VERSION "5.0.7"

NS_ :

BS_:

BU_: BMS EAC EVCC FMCU CVC_P PDU PTC CCU DUMMY_ECU

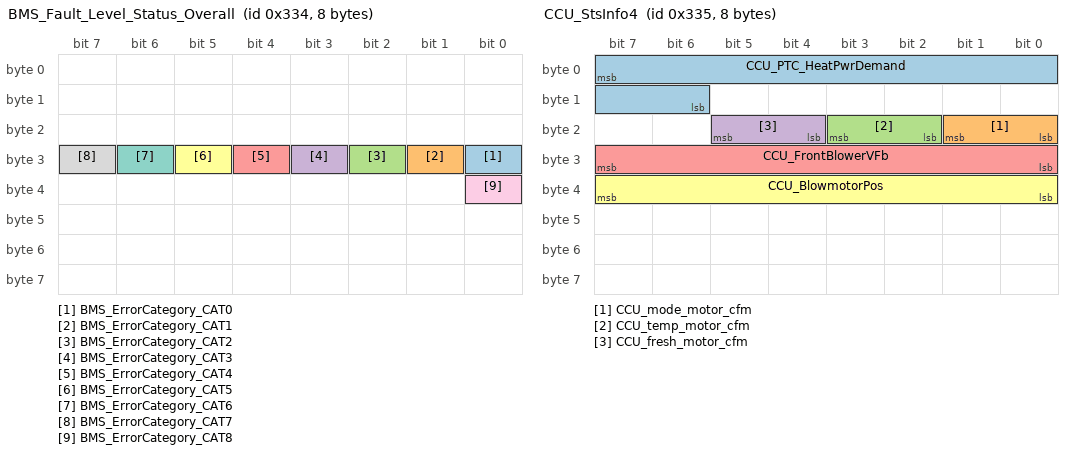
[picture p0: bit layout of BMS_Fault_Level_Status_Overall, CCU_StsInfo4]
BO_ 820 BMS_Fault_Level_Status_Overall: 8 BMS
 SG_ BMS_ErrorCategory_CAT0 : 24|1@0+ (1,0) [0|1] "" Vector__XXX
 SG_ BMS_ErrorCategory_CAT1 : 25|1@0+ (1,0) [0|1] "" Vector__XXX
 SG_ BMS_ErrorCategory_CAT2 : 26|1@0+ (1,0) [0|1] "" Vector__XXX
 SG_ BMS_ErrorCategory_CAT3 : 27|1@0+ (1,0) [0|1] "" Vector__XXX
 SG_ BMS_ErrorCategory_CAT4 : 28|1@0+ (1,0) [0|1] "" Vector__XXX
 SG_ BMS_ErrorCategory_CAT5 : 29|1@0+ (1,0) [0|1] "" Vector__XXX
 SG_ BMS_ErrorCategory_CAT6 : 30|1@0+ (1,0) [0|1] "" Vector__XXX
 SG_ BMS_ErrorCategory_CAT7 : 31|1@0+ (1,0) [0|1] "" Vector__XXX
 SG_ BMS_ErrorCategory_CAT8 : 32|1@0+ (1,0) [0|1] "" Vector__XXX

BO_ 821 CCU_StsInfo4: 8 CCU
 SG_ CCU_PTC_HeatPwrDemand : 7|10@0+ (20,0) [0|5080] "W"  CVC_P,EVCC,PTC
 SG_ CCU_mode_motor_cfm : 17|2@0+ (1,0) [0|3] ""  CVC_P,EVCC,PTC
 SG_ CCU_temp_motor_cfm : 19|2@0+ (1,0) [0|3] ""  CVC_P,EVCC,PTC
 SG_ CCU_fresh_motor_cfm : 21|2@0+ (1,0) [0|3] ""  CVC_P,EVCC,PTC
 SG_ CCU_FrontBlowerVFb : 31|8@0+ (0.1,0) [3|15] "V"  CVC_P
 SG_ CCU_BlowmotorPos : 39|8@0+ (0.1,0) [0|10] "V"  CVC_P

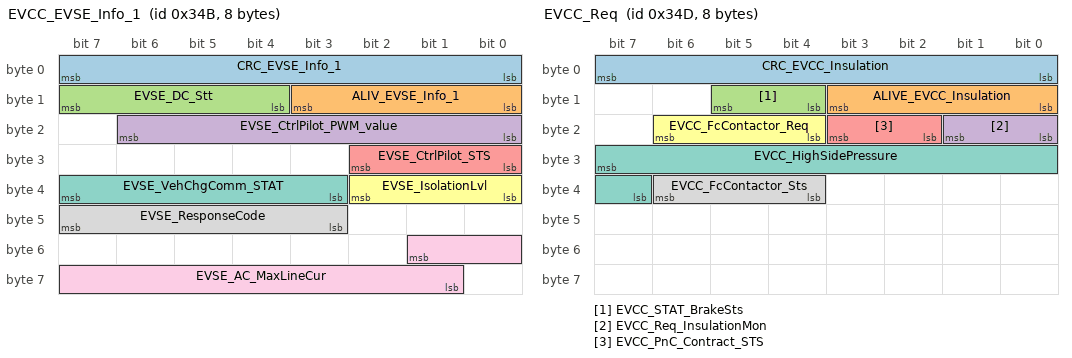
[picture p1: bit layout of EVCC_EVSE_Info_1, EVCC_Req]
BO_ 843 EVCC_EVSE_Info_1: 8 EVCC
 SG_ CRC_EVSE_Info_1 : 7|8@0+ (1,0) [0|255] ""  CVC_P,PDU
 SG_ ALIV_EVSE_Info_1 : 11|4@0+ (1,0) [0|15] ""  CVC_P,PDU
 SG_ EVSE_DC_Stt : 15|4@0+ (1,0) [0|12] ""  CVC_P,PDU
 SG_ EVSE_CtrlPilot_PWM_value : 22|7@0+ (1,0) [0|100] "%"  CVC_P,PDU
 SG_ EVSE_CtrlPilot_STS : 26|3@0+ (1,0) [0|6] ""  CVC_P,PDU
 SG_ EVSE_IsolationLvl : 34|3@0+ (1,0) [0|5] ""  CVC_P,PDU
 SG_ EVSE_VehChgComm_STAT : 39|5@0+ (1,0) [0|27] ""  CVC_P,PDU
 SG_ EVSE_ResponseCode : 47|5@0+ (1,0) [0|26] ""  CVC_P,PDU
 SG_ EVSE_AC_MaxLineCur : 49|9@0+ (1,0) [0|400] "A"  CVC_P,PDU

BO_ 845 EVCC_Req: 8 EVCC
 SG_ CRC_EVCC_Insulation : 7|8@0+ (1,0) [0|255] ""  CVC_P,BMS,PDU
 SG_ ALIVE_EVCC_Insulation : 11|4@0+ (1,0) [0|15] ""  CVC_P,BMS,PDU
 SG_ EVCC_STAT_BrakeSts : 13|2@0+ (1,0) [0|3] ""  CVC_P
 SG_ EVCC_Req_InsulationMon : 17|2@0+ (1,0) [0|3] ""  CVC_P,BMS,PDU
 SG_ EVCC_PnC_Contract_STS : 19|2@0+ (1,0) [0|3] ""  CVC_P,BMS,PDU
 SG_ EVCC_FcContactor_Req : 22|3@0+ (1,0) [0|7] ""  CVC_P,BMS,PDU
 SG_ EVCC_HighSidePressure : 31|9@0+ (10,0) [100|4000] "KPa"  BMS,CVC_P
 SG_ EVCC_FcContactor_Sts : 38|3@0+ (1,0) [0|7] ""  CVC_P,BMS,PDU

BO_ 847 EVCC_EVSE_Info_2: 8 EVCC
 SG_ CRC_EVSE_Info_2 : 7|8@0+ (1,0) [0|255] ""  BMS,CVC_P
 SG_ ALIV_EVSE_Info_2 : 11|4@0+ (1,0) [0|15] ""  BMS,CVC_P
 SG_ EVSE_DC_MaxChgCur : 23|16@0+ (0.1,0) [0|6553.5] "A"  BMS,CVC_P
 SG_ EVSE_DC_MaxChgPwr : 39|16@0+ (0.1,0) [0|6553.5] "kW"  BMS,CVC_P
 SG_ EVSE_DC_ActCurOut : 55|16@0+ (0.1,0) [0|6553.5] "A"  BMS,CVC_P

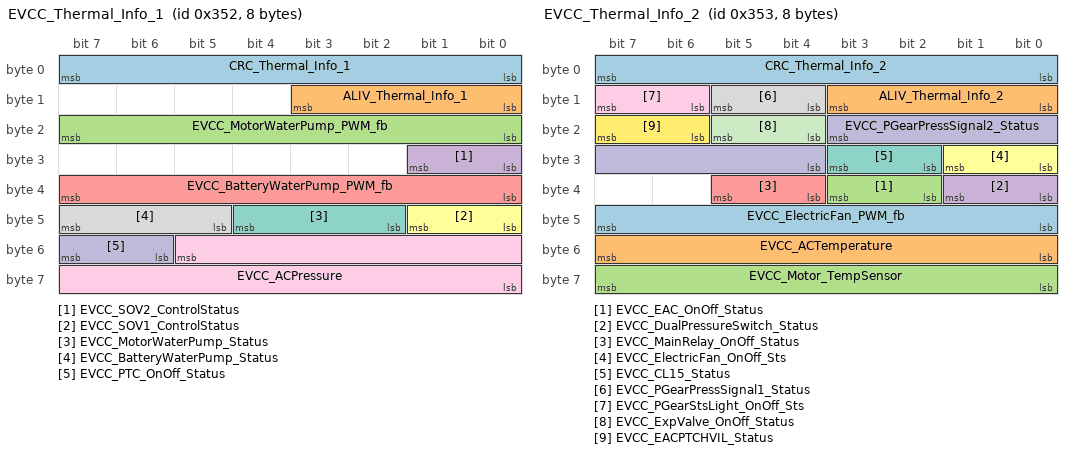
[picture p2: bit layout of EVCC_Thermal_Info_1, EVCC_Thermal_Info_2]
BO_ 850 EVCC_Thermal_Info_1: 8 EVCC
 SG_ CRC_Thermal_Info_1 : 7|8@0+ (1,0) [0|255] ""  CVC_P,CCU
 SG_ ALIV_Thermal_Info_1 : 11|4@0+ (1,0) [0|15] ""  CVC_P,CCU
 SG_ EVCC_MotorWaterPump_PWM_fb : 23|8@0+ (1,0) [0|100] "%"  CVC_P,CCU
 SG_ EVCC_SOV2_ControlStatus : 25|2@0+ (1,0) [0|3] ""  CVC_P,CCU
 SG_ EVCC_BatteryWaterPump_PWM_fb : 39|8@0+ (1,0) [0|100] "%"  CVC_P,CCU
 SG_ EVCC_SOV1_ControlStatus : 41|2@0+ (1,0) [0|3] ""  CVC_P,CCU
 SG_ EVCC_MotorWaterPump_Status : 44|3@0+ (1,0) [0|4] ""  CVC_P,CCU
 SG_ EVCC_BatteryWaterPump_Status : 47|3@0+ (1,0) [0|6] ""  CVC_P,CCU
 SG_ EVCC_ACPressure : 53|14@0+ (0.295,-60) [0|1150] "kPa"  CVC_P,CCU
 SG_ EVCC_PTC_OnOff_Status : 55|2@0+ (1,0) [0|3] ""  CVC_P,CCU

BO_ 851 EVCC_Thermal_Info_2: 8 EVCC
 SG_ CRC_Thermal_Info_2 : 7|8@0+ (1,0) [0|255] ""  CVC_P
 SG_ ALIV_Thermal_Info_2 : 11|4@0+ (1,0) [0|15] ""  CVC_P
 SG_ EVCC_EAC_OnOff_Status : 35|2@0+ (1,0) [0|3] ""  CVC_P
 SG_ EVCC_DualPressureSwitch_Status : 33|2@0+ (1,0) [0|3] ""  CVC_P
 SG_ EVCC_MainRelay_OnOff_Status : 37|2@0+ (1,0) [0|3] ""  CVC_P
 SG_ EVCC_ElectricFan_OnOff_Sts : 25|2@0+ (1,0) [0|3] ""  CVC_P
 SG_ EVCC_CL15_Status : 27|2@0+ (1,0) [0|3] ""  CVC_P
 SG_ EVCC_PGearPressSignal1_Status : 13|2@0+ (1,0) [0|3] ""  CVC_P
 SG_ EVCC_PGearStsLight_OnOff_Sts : 15|2@0+ (1,0) [0|3] ""  CVC_P
 SG_ EVCC_PGearPressSignal2_Status : 19|8@0+ (1,0) [0|255] "kilo ohms"  CVC_P
 SG_ EVCC_ExpValve_OnOff_Status : 21|2@0+ (1,0) [0|3] ""  CVC_P
 SG_ EVCC_EACPTCHVIL_Status : 23|2@0+ (1,0) [0|3] ""  CVC_P
 SG_ EVCC_ElectricFan_PWM_fb : 47|8@0+ (1,0) [0|100] "%"  CVC_P
 SG_ EVCC_ACTemperature : 55|8@0+ (1,-40) [-40|140] "Degree C"  CVC_P
 SG_ EVCC_Motor_TempSensor : 63|8@0+ (1,-40) [-40|140] "Degree C"  CVC_P

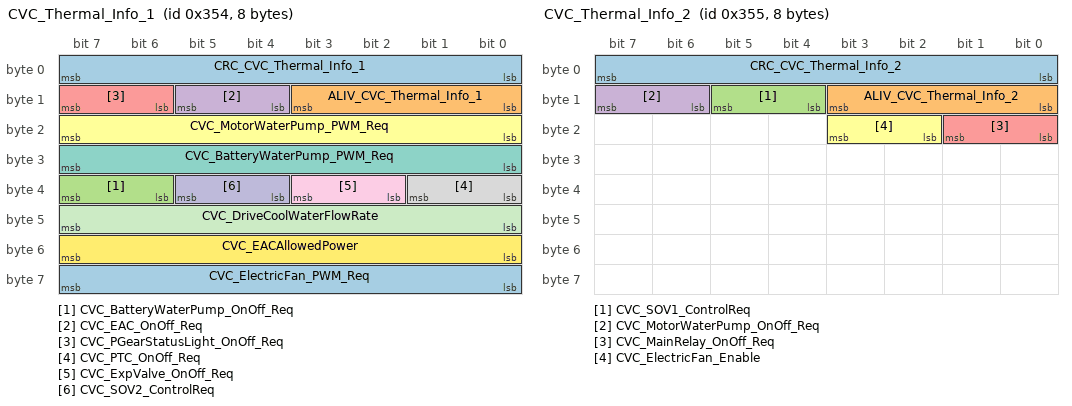
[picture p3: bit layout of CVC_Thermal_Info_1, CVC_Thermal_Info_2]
BO_ 852 CVC_Thermal_Info_1: 8 CVC_P
 SG_ CRC_CVC_Thermal_Info_1 : 7|8@0+ (1,0) [0|255] ""  EVCC,EAC,FMCU
 SG_ ALIV_CVC_Thermal_Info_1 : 11|4@0+ (1,0) [0|15] ""  EVCC,EAC,FMCU
 SG_ CVC_BatteryWaterPump_OnOff_Req : 39|2@0+ (1,0) [0|3] ""  EVCC
 SG_ CVC_EAC_OnOff_Req : 13|2@0+ (1,0) [0|3] ""  EVCC
 SG_ CVC_PGearStatusLight_OnOff_Req : 15|2@0+ (1,0) [0|3] ""  EVCC
 SG_ CVC_MotorWaterPump_PWM_Req : 23|8@0+ (1,0) [0|100] "%"  EVCC
 SG_ CVC_BatteryWaterPump_PWM_Req : 31|8@0+ (1,0) [0|100] "%"  EVCC
 SG_ CVC_PTC_OnOff_Req : 33|2@0+ (1,0) [0|3] ""  EVCC
 SG_ CVC_ExpValve_OnOff_Req : 35|2@0+ (1,0) [0|3] ""  EVCC
 SG_ CVC_SOV2_ControlReq : 37|2@0+ (1,0) [0|3] ""  EVCC
 SG_ CVC_DriveCoolWaterFlowRate : 47|8@0+ (0.1,0) [0|25] "L/min"  EAC,FMCU
 SG_ CVC_EACAllowedPower : 55|8@0+ (40,0) [0|10200] "W"  EAC
 SG_ CVC_ElectricFan_PWM_Req : 63|8@0+ (1,0) [0|100] "%"  EVCC

BO_ 853 CVC_Thermal_Info_2: 8 CVC_P
 SG_ CRC_CVC_Thermal_Info_2 : 7|8@0+ (1,0) [0|255] ""  EVCC
 SG_ ALIV_CVC_Thermal_Info_2 : 11|4@0+ (1,0) [0|15] ""  EVCC
 SG_ CVC_SOV1_ControlReq : 13|2@0+ (1,0) [0|3] ""  EVCC
 SG_ CVC_MotorWaterPump_OnOff_Req : 15|2@0+ (1,0) [0|3] ""  EVCC
 SG_ CVC_MainRelay_OnOff_Req : 17|2@0+ (1,0) [0|3] ""  EVCC
 SG_ CVC_ElectricFan_Enable : 19|2@0+ (1,0) [0|3] ""  EVCC

BO_ 855 CVC_ChgSetting_Info: 8 CVC_P
 SG_ CRC_CVC_ChgSetting_Info : 7|8@0+ (1,0) [0|255] ""  EVCC,BMS
 SG_ ALIV_CVC_ChgSetting_Info : 11|4@0+ (1,0) [0|15] ""  EVCC,BMS
 SG_ CVC_Ack_LimitSetting_SOC : 22|7@0+ (1,0) [0|100] "%"  EVCC,BMS
 SG_ CVC_ACInputChgCurLim : 29|6@0+ (1,0) [0|48] "A"  EVCC

BO_ 858 CVC_CP_Req: 8 CVC_P
 SG_ CRC_CVC_CP_Req : 7|8@0+ (1,0) [0|255] ""  EVCC
 SG_ ALIV_CVC_CP_Req : 11|4@0+ (1,0) [0|15] ""  EVCC
 SG_ CVC_LockCP_Req : 13|2@0+ (1,0) [0|3] ""  EVCC

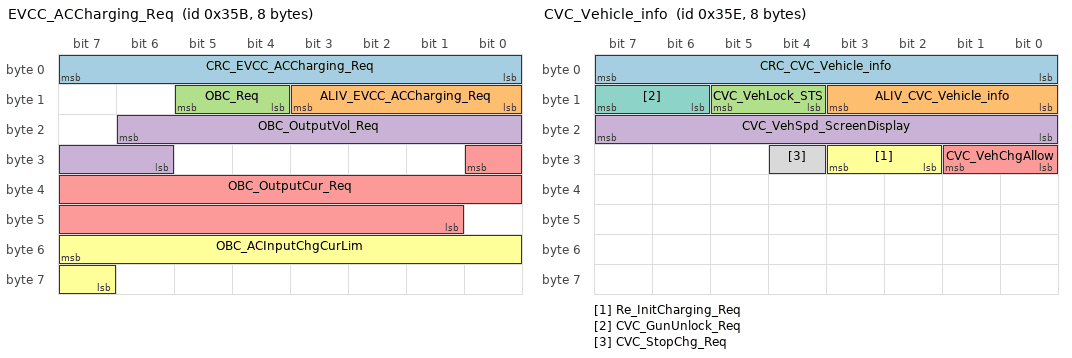
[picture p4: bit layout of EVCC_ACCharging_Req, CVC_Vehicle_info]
BO_ 859 EVCC_ACCharging_Req: 8 EVCC
 SG_ CRC_EVCC_ACCharging_Req : 7|8@0+ (1,0) [0|255] ""  CVC_P,PDU
 SG_ ALIV_EVCC_ACCharging_Req : 11|4@0+ (1,0) [0|15] ""  CVC_P,PDU
 SG_ OBC_Req : 13|2@0+ (1,0) [0|3] ""  CVC_P,PDU
 SG_ OBC_OutputVol_Req : 22|9@0+ (1,0) [0|500] "V"  CVC_P,PDU
 SG_ OBC_OutputCur_Req : 24|16@0+ (0.1,0) [0|48] "A"  CVC_P,PDU
 SG_ OBC_ACInputChgCurLim : 55|9@0+ (0.1,0) [0|48] "A"  CVC_P,PDU

BO_ 862 CVC_Vehicle_info: 8 CVC_P
 SG_ CRC_CVC_Vehicle_info : 7|8@0+ (1,0) [0|255] ""  EVCC,BMS,PDU
 SG_ ALIV_CVC_Vehicle_info : 11|4@0+ (1,0) [0|15] ""  EVCC,BMS,PDU
 SG_ CVC_VehLock_STS : 13|2@0+ (1,0) [0|3] ""  EVCC,BMS,PDU
 SG_ CVC_VehSpd_ScreenDisplay : 23|8@0+ (1,0) [0|254] ""  EVCC,BMS,PDU
 SG_ CVC_VehChgAllow : 25|2@0+ (1,0) [0|3] ""  EVCC,BMS,PDU
 SG_ Re_InitCharging_Req : 27|2@0+ (1,0) [0|3] ""  EVCC,BMS,PDU
 SG_ CVC_GunUnlock_Req : 15|2@0+ (1,0) [0|3] ""  EVCC
 SG_ CVC_StopChg_Req : 28|1@0+ (1,0) [0|1] ""  EVCC

BO_ 872 FMCU_Fault: 8 FMCU
 SG_ FMCU_MCUinternalFault : 48|1@0+ (1,0) [0|1] "" Vector__XXX
 SG_ FMCU_PhaseOverCurrentSWFault : 0|1@0+ (1,0) [0|1] ""  CVC_P
 SG_ FMCU_MCUOverTempFault : 1|1@0+ (1,0) [0|1] ""  CVC_P
 SG_ FMCU_MCUOverTempAlarm : 2|1@0+ (1,0) [0|1] ""  CVC_P
 SG_ FMCU_MotTempSenWFault : 3|1@0+ (1,0) [0|1] ""  CVC_P
 SG_ FMCU_MotTempSenVFault : 4|1@0+ (1,0) [0|1] ""  CVC_P
 SG_ FMCU_MotTempSenUFault : 5|1@0+ (1,0) [0|1] ""  CVC_P
 SG_ FMCU_MotTempSenFault : 6|1@0+ (1,0) [0|1] ""  CVC_P
 SG_ FMCU_MotOverTempFault : 7|1@0+ (1,0) [0|1] ""  CVC_P
 SG_ FMCU_MotOverTempAlarm : 8|1@0+ (1,0) [0|1] ""  CVC_P
 SG_ FMCU_MCUHVUnderVoltageFault : 9|1@0+ (1,0) [0|1] ""  CVC_P
 SG_ FMCU_MCUHVUnderVoltageAlarm : 10|1@0+ (1,0) [0|1] ""  CVC_P
 SG_ FMCU_MCUHVOverVoltageFault : 11|1@0+ (1,0) [0|1] ""  CVC_P
 SG_ FMCU_MCUHVOverVoltageAlarm : 12|1@0+ (1,0) [0|1] ""  CVC_P
 SG_ FMCU_MCUCurrentSenWFault : 13|1@0+ (1,0) [0|1] ""  CVC_P
 SG_ FMCU_MCUCurrentSenVFault : 14|1@0+ (1,0) [0|1] ""  CVC_P
 SG_ FMCU_MCUCurrentSenUFault : 15|1@0+ (1,0) [0|1] ""  CVC_P
 SG_ FMCU_PhaseOverCurrentHWFault : 16|1@0+ (1,0) [0|1] ""  CVC_P
 SG_ FMCU_MotOverFault : 17|1@0+ (1,0) [0|1] ""  CVC_P
 SG_ FMCU_MotOverAlarm : 18|1@0+ (1,0) [0|1] ""  CVC_P
 SG_ FMCU_12VUnderVoltageAlarm : 20|1@0+ (1,0) [0|1] ""  CVC_P
 SG_ FMCU_12VOverVoltageAlarm : 21|1@0+ (1,0) [0|1] ""  CVC_P
 SG_ FMCU_MCUHVSensorFault : 22|1@0+ (1,0) [0|1] ""  CVC_P
 SG_ FMCU_MCUDisChgFault : 24|1@0+ (1,0) [0|1] ""  CVC_P
 SG_ FMCU_MotBlockedFault : 30|1@0+ (1,0) [0|1] ""  CVC_P
 SG_ FMCU_MotRotSenFault : 31|1@0+ (1,0) [0|1] ""  CVC_P
 SG_ FMCU_BMSLostFault : 34|1@0+ (1,0) [0|1] ""  CVC_P
 SG_ FMCU_CVCLostFault : 35|1@0+ (1,0) [0|1] ""  CVC_P
 SG_ FMCU_CANBusoffFault : 36|1@0+ (1,0) [0|1] ""  CVC_P
 SG_ FMCU_IGBTFault : 37|1@0+ (1,0) [0|1] ""  CVC_P
 SG_ FMCU_MCUCurrentSenWZeroFault : 38|1@0+ (1,0) [0|1] ""  CVC_P
 SG_ FMCU_MCUCurrentSenVZeroFault : 43|1@0+ (1,0) [0|1] ""  CVC_P
 SG_ FMCU_MCUCurrentSenUZeroFault : 44|1@0+ (1,0) [0|1] ""  CVC_P
 SG_ FMCU_MCUTempSenWFault : 45|1@0+ (1,0) [0|1] ""  CVC_P
 SG_ FMCU_MCUTempSenVFault : 46|1@0+ (1,0) [0|1] ""  CVC_P
 SG_ FMCU_MCUTempSenUFault : 47|1@0+ (1,0) [0|1] ""  CVC_P
 SG_ FMCU_InitMode : 50|1@0+ (1,0) [0|1] ""  CVC_P
 SG_ FMCU_MCUFaultCode : 63|8@0+ (1,0) [0|255] ""  CVC_P

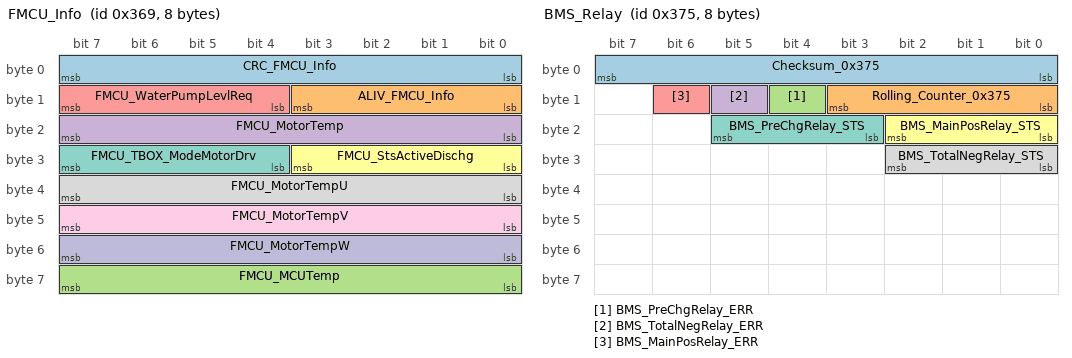
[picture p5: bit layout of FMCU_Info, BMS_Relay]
BO_ 873 FMCU_Info: 8 FMCU
 SG_ CRC_FMCU_Info : 7|8@0+ (1,0) [0|255] ""  CVC_P
 SG_ ALIV_FMCU_Info : 11|4@0+ (1,0) [0|15] ""  CVC_P
 SG_ FMCU_MCUTemp : 63|8@0+ (1,-40) [-40|210] "Degree C"  CVC_P
 SG_ FMCU_MotorTemp : 23|8@0+ (1,-40) [-40|210] "Degree C"  CVC_P
 SG_ FMCU_WaterPumpLevlReq : 15|4@0+ (2,0) [0|30] "l/min"  CVC_P
 SG_ FMCU_StsActiveDischg : 27|4@0+ (1,0) [0|15] ""  CVC_P
 SG_ FMCU_TBOX_ModeMotorDrv : 31|4@0+ (1,0) [0|15] ""  CVC_P
 SG_ FMCU_MotorTempU : 39|8@0+ (1,-40) [-40|210] "Degree C"  CVC_P
 SG_ FMCU_MotorTempV : 47|8@0+ (1,-40) [-40|210] "Degree C"  CVC_P
 SG_ FMCU_MotorTempW : 55|8@0+ (1,-40) [-40|210] "Degree C"  CVC_P

BO_ 876 AC_36C: 8 CVC_P
 SG_ CRC_AC_36C : 7|8@0+ (1,0) [0|255] ""  PTC
 SG_ ALIV_AC_36C : 11|4@0+ (1,0) [0|15] ""  PTC
 SG_ AC_PTC_HeatPwrReq : 23|8@0+ (20,0) [0|5080] "W"  PTC
 SG_ AC_PTC_Enable : 12|1@0+ (1,0) [0|1] "bit"  PTC

BO_ 884 PTC_Info1: 8 PTC
 SG_ PTC_PCBT : 23|8@0+ (1,-48) [-48|207] "Degree C"  CVC_P,CCU
 SG_ PTC_Crt : 31|16@0+ (0.001,0) [0|65.535] "A"  CVC_P,CCU
 SG_ PTC_CrtSts : 41|2@0+ (1,0) [0|3] ""  CVC_P,CCU
 SG_ PTC_HVIntlkFlt : 42|1@0+ (1,0) [0|1] ""  CVC_P,CCU
 SG_ PTC_ComLost_ECC : 43|1@0+ (1,0) [0|1] ""  CVC_P,CCU
 SG_ PTC_OverCrtFlt : 44|1@0+ (1,0) [0|1] ""  CVC_P,CCU
 SG_ PTC_HVUnderVoltFlt : 45|1@0+ (1,0) [0|1] ""  CVC_P,CCU
 SG_ PTC_HVOverVoltFlt : 46|1@0+ (1,0) [0|1] ""  CVC_P,CCU
 SG_ PTC_ChkBattOverVoltFlt : 47|1@0+ (1,0) [0|1] ""  CVC_P,CCU
 SG_ PTC_ChkBattUnderVoltFlt : 48|1@0+ (1,0) [0|1] ""  CVC_P,CCU
 SG_ PTC_InlTSnsrFlt : 49|1@0+ (1,0) [0|1] ""  CVC_P,CCU
 SG_ PTC_OutlTSnsrFlt : 50|1@0+ (1,0) [0|1] ""  CVC_P,CCU
 SG_ PTC_InlOverTFlt : 51|1@0+ (1,0) [0|1] ""  CVC_P,CCU
 SG_ PTC_OutlOverTFlt : 52|1@0+ (1,0) [0|1] ""  CVC_P,CCU
 SG_ PTC_PCBOverTFlt : 53|1@0+ (1,0) [0|1] ""  CVC_P,CCU
 SG_ PTC_PCBTSnsrFlt : 54|1@0+ (1,0) [0|1] ""  CVC_P,CCU
 SG_ PTC_PwrOutpFlt : 55|1@0+ (1,0) [0|1] ""  CVC_P,CCU

BO_ 885 BMS_Relay: 8 BMS
 SG_ Checksum_0x375 : 7|8@0+ (1,0) [0|255] ""  FMCU,CVC_P
 SG_ Rolling_Counter_0x375 : 11|4@0+ (1,0) [0|15] ""  FMCU,CVC_P
 SG_ BMS_PreChgRelay_ERR : 12|1@0+ (1,0) [0|1] ""  FMCU,CVC_P
 SG_ BMS_TotalNegRelay_ERR : 13|1@0+ (1,0) [0|1] ""  FMCU,CVC_P,PDU
 SG_ BMS_MainPosRelay_ERR : 14|1@0+ (1,0) [0|1] ""  FMCU,CVC_P
 SG_ BMS_MainPosRelay_STS : 18|3@0+ (1,0) [0|7] ""  FMCU,CVC_P,PDU
 SG_ BMS_PreChgRelay_STS : 21|3@0+ (1,0) [0|7] ""  FMCU,CVC_P,PDU
 SG_ BMS_TotalNegRelay_STS : 26|3@0+ (1,0) [0|7] ""  FMCU,CVC_P

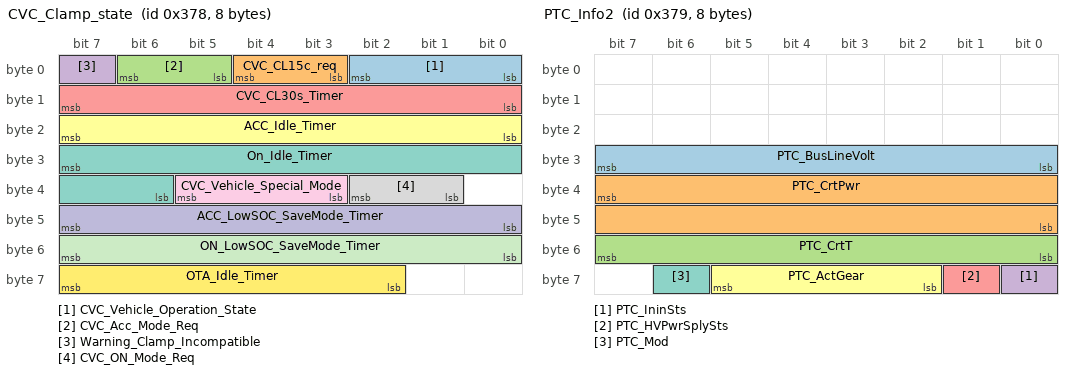
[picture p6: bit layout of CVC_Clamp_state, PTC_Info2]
BO_ 888 CVC_Clamp_state: 8 CVC_P
 SG_ CVC_Vehicle_Operation_State : 2|3@0+ (1,0) [0|7] ""  BMS,FMCU,PDU,EVCC,CCU,EAC,PTC
 SG_ CVC_CL15c_req : 4|2@0+ (1,0) [0|3] ""  BMS,FMCU,PDU,EVCC,CCU
 SG_ CVC_Acc_Mode_Req : 6|2@0+ (1,0) [0|3] ""  BMS,FMCU,PDU,EVCC,CCU
 SG_ Warning_Clamp_Incompatible : 7|1@0+ (1,0) [0|1] ""  BMS,FMCU,PDU,EVCC,CCU
 SG_ CVC_CL30s_Timer : 15|8@0+ (1,0) [0|255] ""  BMS,FMCU,PDU,EVCC,CCU
 SG_ ACC_Idle_Timer : 23|8@0+ (1,0) [0|255] ""  BMS,FMCU,PDU,EVCC,CCU
 SG_ On_Idle_Timer : 31|10@0+ (1,0) [0|1023] ""  BMS,FMCU,PDU,EVCC,CCU
 SG_ CVC_ON_Mode_Req : 34|2@0+ (1,0) [0|3] ""  BMS,FMCU,PDU,EVCC,CCU
 SG_ CVC_Vehicle_Special_Mode : 37|3@0+ (1,0) [0|7] ""  BMS,FMCU,PDU,EVCC,CCU
 SG_ ACC_LowSOC_SaveMode_Timer : 47|8@0+ (1,0) [0|255] ""  BMS,FMCU,PDU,EVCC,CCU
 SG_ ON_LowSOC_SaveMode_Timer : 55|8@0+ (1,0) [0|255] ""  BMS,FMCU,PDU,EVCC,CCU
 SG_ OTA_Idle_Timer : 63|6@0+ (1,0) [0|64] "minute"  DUMMY_ECU

BO_ 889 PTC_Info2: 8 PTC
 SG_ PTC_BusLineVolt : 31|8@0+ (2,0) [0|500] "Volt"  CVC_P,CCU,BMS
 SG_ PTC_CrtPwr : 39|16@0+ (20,0) [0|5080] "W"  CVC_P,CCU,BMS
 SG_ PTC_CrtT : 55|8@0+ (1,-48) [-48|207] "Degree C"  CVC_P,CCU,BMS
 SG_ PTC_IninSts : 56|1@0+ (1,0) [0|1] ""  CVC_P,CCU,BMS
 SG_ PTC_HVPwrSplySts : 57|1@0+ (1,0) [0|1] ""  CVC_P,CCU,BMS
 SG_ PTC_ActGear : 61|4@0+ (1,0) [0|15] ""  CVC_P,CCU,BMS
 SG_ PTC_Mod : 62|1@0+ (1,0) [0|1] ""  CVC_P,CCU,BMS

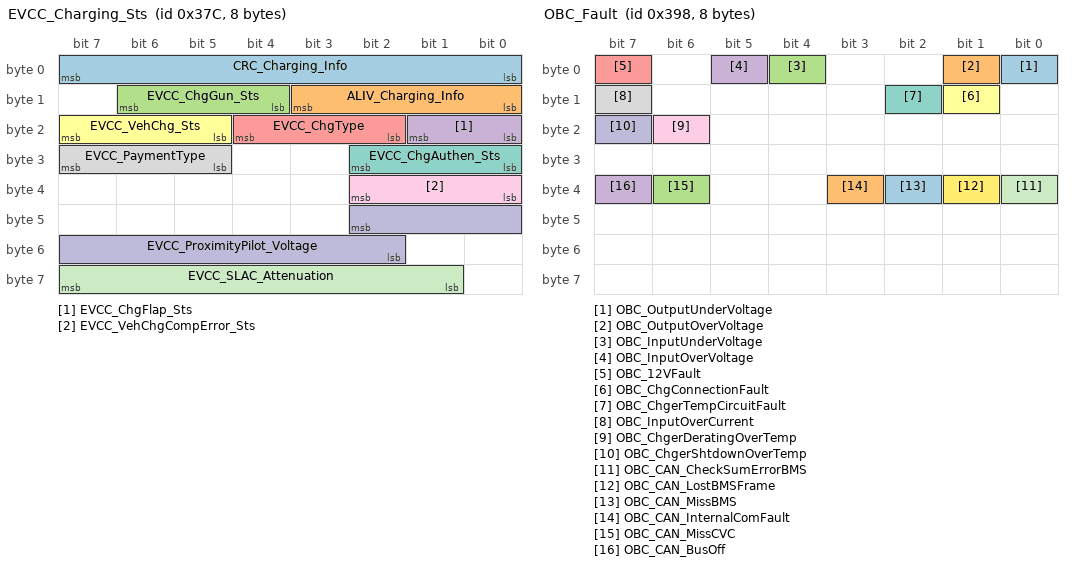
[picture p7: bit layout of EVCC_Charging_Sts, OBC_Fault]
BO_ 892 EVCC_Charging_Sts: 8 EVCC
 SG_ CRC_Charging_Info : 7|8@0+ (1,0) [0|255] ""  CVC_P,BMS,PDU
 SG_ ALIV_Charging_Info : 11|4@0+ (1,0) [0|15] ""  CVC_P,BMS,PDU
 SG_ EVCC_ChgGun_Sts : 14|3@0+ (1,0) [0|7] ""  CVC_P,BMS,PDU
 SG_ EVCC_ChgFlap_Sts : 17|2@0+ (1,0) [0|3] ""  CVC_P,BMS,PDU
 SG_ EVCC_ChgType : 20|3@0+ (1,0) [0|7] ""  CVC_P,BMS,PDU
 SG_ EVCC_VehChg_Sts : 23|3@0+ (1,0) [0|7] ""  CVC_P,BMS,PDU
 SG_ EVCC_ChgAuthen_Sts : 26|3@0+ (1,0) [0|7] ""  CVC_P,BMS,PDU
 SG_ EVCC_PaymentType : 31|3@0+ (1,0) [0|7] ""  CVC_P,BMS,PDU
 SG_ EVCC_VehChgCompError_Sts : 34|3@0+ (1,0) [0|7] ""  CVC_P,BMS,PDU
 SG_ EVCC_ProximityPilot_Voltage : 42|9@0+ (0.01,0) [0|5] "V"  CVC_P,BMS,PDU
 SG_ EVCC_SLAC_Attenuation : 63|7@0+ (1,0) [0|100] "dB"  CVC_P

BO_ 893 CVC_Battery_Info: 8 CVC_P
 SG_ CRC_CVC_Battery_Info : 7|8@0+ (1,0) [0|255] ""  EVCC,BMS,PDU
 SG_ ALIV_CVC_Battery_Info : 11|4@0+ (1,0) [0|15] ""  EVCC,BMS,PDU
 SG_ CVC_HV_DispSOC : 23|10@0+ (0.1,0) [0|100] "%"  EVCC
 SG_ CVC_HV_Cur_LoadComp : 29|10@0+ (0.1,0) [0|100] "A"  EVCC,BMS,PDU

BO_ 896 BCM_VEHICLE_IDENT_NUMBER: 8 CVC_P
 SG_ VIN_Byte1 : 7|8@0+ (1,0) [0|255] ""  FMCU,PDU,BMS
 SG_ VIN_Byte2 : 15|8@0+ (1,0) [0|255] ""  FMCU,PDU,BMS
 SG_ VIN_Byte3 : 23|8@0+ (1,0) [0|255] ""  FMCU,PDU,BMS
 SG_ VIN_Byte4 : 31|8@0+ (1,0) [0|255] ""  FMCU,PDU,BMS
 SG_ VIN_Byte5 : 39|8@0+ (1,0) [0|255] ""  FMCU,PDU,BMS
 SG_ VIN_Byte6 : 47|8@0+ (1,0) [0|255] ""  FMCU,PDU,BMS
 SG_ VIN_Byte7 : 55|8@0+ (1,0) [0|255] ""  FMCU,PDU,BMS

BO_ 919 OBC_Temp: 8 PDU
 SG_ CRC_OBC_Temp : 7|8@0+ (1,0) [0|255] ""  CVC_P
 SG_ ALIV_OBC_Temp : 11|4@0+ (1,0) [0|15] ""  CVC_P
 SG_ OBC_OBCTemp : 31|8@0+ (1,-40) [-40|214] "Degree C"  CVC_P
 SG_ OBC_InletTemp : 23|8@0+ (1,-40) [-40|210] "Degree C"  CVC_P
 SG_ OBC_InletTempSenFault : 46|1@0+ (1,0) [0|1] "-"  CVC_P

BO_ 920 OBC_Fault: 8 PDU
 SG_ OBC_OutputUnderVoltage : 0|1@0+ (1,0) [0|1] ""  CVC_P
 SG_ OBC_OutputOverVoltage : 1|1@0+ (1,0) [0|1] ""  CVC_P
 SG_ OBC_InputUnderVoltage : 4|1@0+ (1,0) [0|1] ""  CVC_P
 SG_ OBC_InputOverVoltage : 5|1@0+ (1,0) [0|1] ""  CVC_P
 SG_ OBC_12VFault : 7|1@0+ (1,0) [0|1] ""  CVC_P
 SG_ OBC_ChgConnectionFault : 9|1@0+ (1,0) [0|1] ""  CVC_P
 SG_ OBC_ChgerTempCircuitFault : 10|1@0+ (1,0) [0|1] ""  CVC_P
 SG_ OBC_InputOverCurrent : 15|1@0+ (1,0) [0|1] ""  CVC_P
 SG_ OBC_ChgerDeratingOverTemp : 22|1@0+ (1,0) [0|1] ""  CVC_P
 SG_ OBC_ChgerShtdownOverTemp : 23|1@0+ (1,0) [0|1] ""  CVC_P
 SG_ OBC_CAN_CheckSumErrorBMS : 32|1@0+ (1,0) [0|1] ""  CVC_P
 SG_ OBC_CAN_LostBMSFrame : 33|1@0+ (1,0) [0|1] ""  CVC_P
 SG_ OBC_CAN_MissBMS : 34|1@0+ (1,0) [0|1] ""  CVC_P
 SG_ OBC_CAN_InternalComFault : 35|1@0+ (1,0) [0|1] ""  CVC_P
 SG_ OBC_CAN_MissCVC : 38|1@0+ (1,0) [0|1] ""  CVC_P
 SG_ OBC_CAN_BusOff : 39|1@0+ (1,0) [0|1] ""  CVC_P

BO_ 1009 IPC_TotalOdometer: 8 CVC_P
 SG_ CheckSum_0x3F1 : 7|8@0+ (1,0) [0|255] ""  BMS,FMCU,PDU,PTC,EAC,CCU,EVCC
 SG_ RollingCounter_0x3F1 : 11|4@0+ (1,0) [0|15] ""  BMS,FMCU,PDU,PTC,EAC,CCU,EVCC
 SG_ IPC_IPCTotalOdometer : 23|24@0+ (0.1,0) [0|999999] "km"  BMS,FMCU,PDU,PTC,EAC,CCU,EVCC
 SG_ IPC_IPCTotalOdometerV : 40|1@0+ (1,0) [0|1] ""  BMS,FMCU,PDU,PTC,EAC,CCU,EVCC
 SG_ IPC_Remain_Maintenance : 55|16@0+ (1,0) [0|50000] "km"  BMS,FMCU,PDU,PTC,EAC,CCU,EVCC

BO_ 1098 PTC_Version: 8 PTC
 SG_ PTC_SwVersS : 15|8@0+ (1,0) [0|255] "" Vector__XXX
 SG_ PTC_PartVers : 23|32@0+ (1,0) [0|4294967295] "" Vector__XXX
 SG_ PTC_HwVers : 55|8@0+ (1,0) [0|255] "" Vector__XXX
 SG_ PTC_SwVersM : 63|8@0+ (1,0) [0|255] "" Vector__XXX

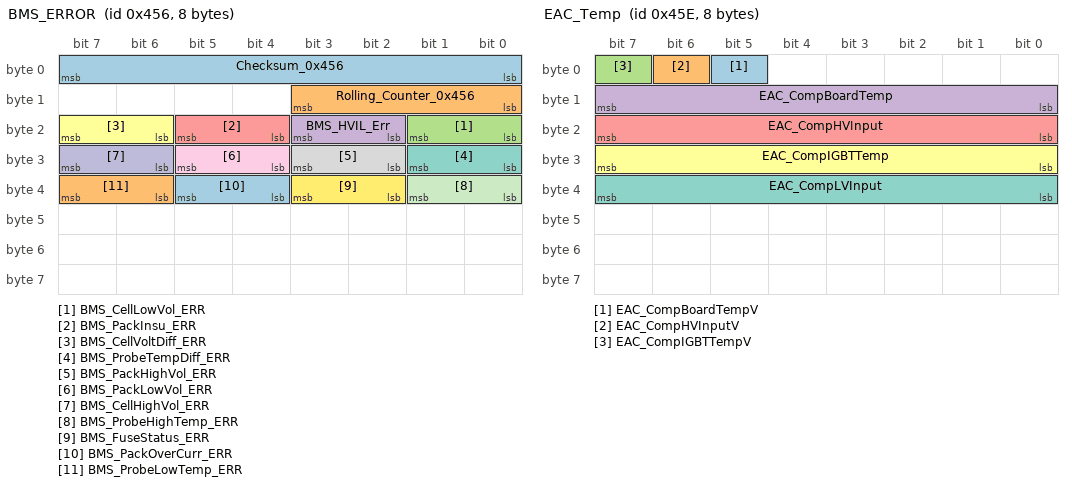
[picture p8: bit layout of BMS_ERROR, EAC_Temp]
BO_ 1110 BMS_ERROR: 8 BMS
 SG_ Checksum_0x456 : 7|8@0+ (1,0) [0|255] ""  CVC_P
 SG_ Rolling_Counter_0x456 : 11|4@0+ (1,0) [0|15] ""  CVC_P
 SG_ BMS_CellLowVol_ERR : 17|2@0+ (1,0) [0|3] ""  CVC_P
 SG_ BMS_HVIL_Err : 19|2@0+ (1,0) [0|3] ""  CVC_P
 SG_ BMS_PackInsu_ERR : 21|2@0+ (1,0) [0|3] ""  CVC_P
 SG_ BMS_CellVoltDiff_ERR : 23|2@0+ (1,0) [0|3] ""  CVC_P
 SG_ BMS_ProbeTempDiff_ERR : 25|2@0+ (1,0) [0|3] ""  CVC_P
 SG_ BMS_PackHighVol_ERR : 27|2@0+ (1,0) [0|3] ""  CVC_P
 SG_ BMS_PackLowVol_ERR : 29|2@0+ (1,0) [0|3] ""  CVC_P
 SG_ BMS_CellHighVol_ERR : 31|2@0+ (1,0) [0|3] ""  CVC_P
 SG_ BMS_ProbeHighTemp_ERR : 33|2@0+ (1,0) [0|3] ""  CVC_P
 SG_ BMS_FuseStatus_ERR : 35|2@0+ (1,0) [0|1] ""  CVC_P
 SG_ BMS_PackOverCurr_ERR : 37|2@0+ (1,0) [0|3] ""  CVC_P
 SG_ BMS_ProbeLowTemp_ERR : 39|2@0+ (1,0) [0|3] ""  CVC_P

BO_ 1118 EAC_Temp: 8 EAC
 SG_ EAC_CompBoardTempV : 5|1@0+ (1,0) [0|1] ""  CVC_P
 SG_ EAC_CompHVInputV : 6|1@0+ (1,0) [0|1] ""  CVC_P
 SG_ EAC_CompIGBTTempV : 7|1@0+ (1,0) [0|1] ""  CVC_P
 SG_ EAC_CompBoardTemp : 15|8@0+ (1,-40) [-40|215] "Degree C"  CVC_P
 SG_ EAC_CompHVInput : 23|8@0+ (4,0) [0|1020] "V"  CVC_P
 SG_ EAC_CompIGBTTemp : 31|8@0+ (1,-40) [-40|215] "Degree C"  CVC_P
 SG_ EAC_CompLVInput : 39|8@0+ (4,0) [0|1020] "V" Vector__XXX

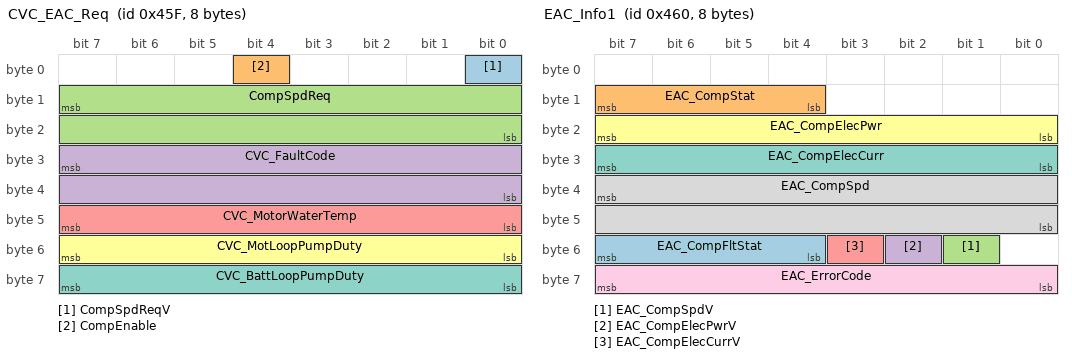
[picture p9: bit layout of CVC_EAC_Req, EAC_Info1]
BO_ 1119 CVC_EAC_Req: 8 CVC_P
 SG_ CompSpdReqV : 0|1@0+ (1,0) [0|1] ""  EAC
 SG_ CompEnable : 4|1@0+ (1,0) [0|1] ""  EAC
 SG_ CompSpdReq : 15|16@0+ (1,0) [0|65535] "RPM"  EAC
 SG_ CVC_FaultCode : 31|16@0+ (1,0) [0|65535] ""  EAC
 SG_ CVC_MotorWaterTemp : 47|8@0+ (1,-40) [-40|210] "Degree C"  EAC
 SG_ CVC_MotLoopPumpDuty : 55|8@0+ (1,0) [0|100] "%"  EAC
 SG_ CVC_BattLoopPumpDuty : 63|8@0+ (1,0) [0|100] "%"  EAC

BO_ 1117 EAC_Version: 8 EAC
 SG_ EAC_HW_MasterVersion : 7|8@0+ (1,0) [0|255] "" Vector__XXX
 SG_ EAC_SW_bottomVersion : 23|8@0+ (1,0) [0|255] "" Vector__XXX
 SG_ EAC_SW_ApplicationVersion : 31|8@0+ (1,0) [0|255] "" Vector__XXX
 SG_ EAC_SW_year : 39|8@0+ (1,2000) [2000|2255] "" Vector__XXX
 SG_ EAC_SW_month : 47|8@0+ (1,0) [0|255] "" Vector__XXX
 SG_ EAC_SW_day : 55|8@0+ (1,0) [0|255] "" Vector__XXX

BO_ 1120 EAC_Info1: 8 EAC
 SG_ EAC_CompFltStat : 55|4@0+ (1,0) [0|15] ""  CVC_P,CCU,BMS
 SG_ EAC_CompStat : 15|4@0+ (1,0) [0|15] ""  CVC_P,CCU,BMS
 SG_ EAC_CompSpdV : 49|1@0+ (1,0) [0|1] ""  CVC_P,CCU,BMS
 SG_ EAC_CompElecPwrV : 50|1@0+ (1,0) [0|1] ""  CVC_P,CCU,BMS
 SG_ EAC_CompElecCurrV : 51|1@0+ (1,0) [0|1] ""  CVC_P,CCU,BMS
 SG_ EAC_CompElecPwr : 23|8@0+ (40,0) [0|10200] "W"  CVC_P,CCU,BMS
 SG_ EAC_CompElecCurr : 31|8@0+ (0.2,0) [0|51] "A"  CVC_P,CCU,BMS
 SG_ EAC_CompSpd : 39|16@0+ (1,0) [0|65535] "rpm"  CVC_P,CCU,BMS
 SG_ EAC_ErrorCode : 63|8@0+ (1,0) [0|255] ""  CVC_P

BO_ 1141 PDU_DCFC_EventMatrix: 8 PDU
 SG_ PDU_DCFC_evt_reserved15 : 63|8@0+ (1,0) [0|1] "" Vector__XXX
 SG_ PDU_DCFC_evt_reserved14 : 55|8@0+ (1,0) [0|1] "" Vector__XXX
 SG_ PDU_DCFC_evt_reserved13 : 47|8@0+ (1,0) [0|1] "" Vector__XXX
 SG_ PDU_DCFC_evt_reserved12 : 39|8@0+ (1,0) [0|1] "" Vector__XXX
 SG_ PDU_DCFC_evt_reserved11 : 24|1@0+ (1,0) [0|1] "" Vector__XXX
 SG_ PDU_DCFC_evt_reserved10 : 25|1@0+ (1,0) [0|1] "" Vector__XXX
 SG_ PDU_DCFC_evt_reserved9 : 26|1@0+ (1,0) [0|1] "" Vector__XXX
 SG_ PDU_DCFC_evt_reserved8 : 27|1@0+ (1,0) [0|1] "" Vector__XXX
 SG_ PDU_DCFC_evt_reserved7 : 28|1@0+ (1,0) [0|1] "" Vector__XXX
 SG_ PDU_DCFC_evt_reserved6 : 29|1@0+ (1,0) [0|1] "" Vector__XXX
 SG_ PDU_DCFC_evt_reserved5 : 30|1@0+ (1,0) [0|1] "" Vector__XXX
 SG_ PDU_DCFC_evt_reserved4 : 31|1@0+ (1,0) [0|1] "" Vector__XXX
 SG_ PDU_DCFC_evt_reserved3 : 16|1@0+ (1,0) [0|1] "" Vector__XXX
 SG_ PDU_DCFC_evt_reserved2 : 17|1@0+ (1,0) [0|1] "" Vector__XXX
 SG_ PDU_DCFC_evt_reserved1 : 18|1@0+ (1,0) [0|1] "" Vector__XXX
 SG_ PDU_DCFC_evt_reserved0 : 19|1@0+ (1,0) [0|1] "" Vector__XXX
 SG_ PDU_DCFC_evt_I2CDataWrong : 20|1@0+ (1,0) [0|1] "" Vector__XXX
 SG_ PDU_DCFC_evt_I2CComFail : 21|1@0+ (1,0) [0|1] "" Vector__XXX
 SG_ PDU_DCFC_evt_ChgPort_RvrsPoltFlt : 22|1@0+ (1,0) [0|1] "" Vector__XXX
 SG_ PDU_DCFC_evt_ChgPort_UnderV_CMP : 23|1@0+ (1,0) [0|1] "" Vector__XXX
 SG_ PDU_DCFC_evt_ChgPort_OverV_CMP : 8|1@0+ (1,0) [0|1] "" Vector__XXX
 SG_ PDU_DCFC_evt_BUSOFF : 9|1@0+ (1,0) [0|1] "" Vector__XXX
 SG_ PDU_DCFC_evt_EXTMEMFAIL : 10|1@0+ (1,0) [0|1] "" Vector__XXX
 SG_ PDU_DCFC_evt_MCUPWRFAIL : 11|1@0+ (1,0) [0|1] "" Vector__XXX
 SG_ PDU_DCFC_evt_CoilPwrFlt : 12|1@0+ (1,0) [0|1] "" Vector__XXX
 SG_ PDU_DCFC_evt_ChgPort_VSensFlt : 13|1@0+ (1,0) [0|1] "" Vector__XXX
 SG_ PDU_DCFC_evt_E2E : 14|1@0+ (1,0) [0|1] "" Vector__XXX
 SG_ PDU_DCFC_evt_MIA : 15|1@0+ (1,0) [0|1] "" Vector__XXX
 SG_ PDU_DCFC_evt_ChgPort_UnderV_SW : 0|1@0+ (1,0) [0|1] "" Vector__XXX
 SG_ PDU_DCFC_evt_PosBB_OverTempFlt : 1|1@0+ (1,0) [0|1] "" Vector__XXX
 SG_ PDU_DCFC_evt_NegBB_OverTempFlt : 2|1@0+ (1,0) [0|1] "" Vector__XXX
 SG_ PDU_DCFC_evt_ChgPort_OverV_SW : 3|1@0+ (1,0) [0|1] "" Vector__XXX
 SG_ PDU_DCFC_evt_Contactor_StuckOpen : 4|1@0+ (1,0) [0|1] "" Vector__XXX
 SG_ PDU_DCFC_evt_Contactor_Welded : 5|1@0+ (1,0) [0|1] "" Vector__XXX
 SG_ PDU_DCFC_evt_PosBB_TempSensFlt : 6|1@0+ (1,0) [0|1] "" Vector__XXX
 SG_ PDU_DCFC_evt_NegBB_TempSensFlt : 7|1@0+ (1,0) [0|1] "" Vector__XXX

BO_ 1145 EVCC_EventMatrix: 8 EVCC
 SG_ EVCC_evt_ePP : 0|1@0+ (1,0) [0|1] "" Vector__XXX
 SG_ EVCC_evt_eCP : 1|1@0+ (1,0) [0|1] "" Vector__XXX
 SG_ EVCC_evt_eGunLck : 2|1@0+ (1,0) [0|1] "" Vector__XXX
 SG_ EVCC_evt_eV2G : 3|1@0+ (1,0) [0|1] "" Vector__XXX
 SG_ EVCC_evt_eAcPlugTemp : 4|1@0+ (1,0) [0|1] "" Vector__XXX
 SG_ EVCC_evt_eDcPlugTemp : 5|1@0+ (1,0) [0|1] "" Vector__XXX
 SG_ EVCC_evt_eBmsLvl : 6|1@0+ (1,0) [0|1] "" Vector__XXX
 SG_ EVCC_evt_eHLC : 7|1@0+ (1,0) [0|1] "" Vector__XXX
 SG_ EVCC_evt_iEvseDcPeakRpl : 8|1@0+ (1,0) [0|1] "" Vector__XXX
 SG_ EVCC_evt_eObcLvl : 9|1@0+ (1,0) [0|1] "" Vector__XXX
 SG_ EVCC_evt_ChgGunStkOpnd : 10|1@0+ (1,0) [0|1] "" Vector__XXX
 SG_ EVCC_evt_ChgGunStkClsd : 11|1@0+ (1,0) [0|1] "" Vector__XXX
 SG_ EVCC_evt_AcTmpShortVcc : 12|1@0+ (1,0) [0|1] "" Vector__XXX
 SG_ EVCC_evt_PPShortVcc : 13|1@0+ (1,0) [0|1] "" Vector__XXX
 SG_ EVCC_evt_PPShortGnd : 14|1@0+ (1,0) [0|1] "" Vector__XXX
 SG_ EVCC_evt_DcPTmpShortGnd : 15|1@0+ (1,0) [0|1] "" Vector__XXX
 SG_ EVCC_evt_eFCWelded : 16|1@0+ (1,0) [0|1] "" Vector__XXX
 SG_ EVCC_evt_eHVBusTemp : 17|1@0+ (1,0) [0|1] "" Vector__XXX
 SG_ EVCC_evt_ChgFlapHBShtGnd : 18|1@0+ (1,0) [0|1] "" Vector__XXX
 SG_ EVCC_evt_ChgFlapHBShtBatt : 19|1@0+ (1,0) [0|1] "" Vector__XXX
 SG_ EVCC_evt_ChgFlapHBOpnCir : 20|1@0+ (1,0) [0|1] "" Vector__XXX
 SG_ EVCC_evt_ChgFlapHBOCVCrr : 21|1@0+ (1,0) [0|1] "" Vector__XXX
 SG_ EVCC_evt_ChgFlapHBOvTemp : 22|1@0+ (1,0) [0|1] "" Vector__XXX
 SG_ EVCC_evt_DcPTmpShortVcc : 23|1@0+ (1,0) [0|1] "" Vector__XXX
 SG_ EVCC_evt_AcTmpShortGnd : 24|1@0+ (1,0) [0|1] "" Vector__XXX
 SG_ EVCC_evt_eBmsInsu : 25|1@0+ (1,0) [0|1] "" Vector__XXX
 SG_ EVCC_evt_eBmsHvil : 26|1@0+ (1,0) [0|1] "" Vector__XXX
 SG_ EVCC_evt_eDcFcLvl1 : 27|1@0+ (1,0) [0|1] "" Vector__XXX
 SG_ EVCC_evt_eDcFcLvl2 : 28|1@0+ (1,0) [0|1] "" Vector__XXX
 SG_ EVCC_evt_eDcFcLvl3 : 29|1@0+ (1,0) [0|1] "" Vector__XXX
 SG_ EVCC_evt_eEVSE : 30|1@0+ (1,0) [0|1] "" Vector__XXX
 SG_ EVCC_evt_S2StkClsd : 31|1@0+ (1,0) [0|1] "" Vector__XXX
 SG_ EVCC_evt_S2StkOpnd : 32|1@0+ (1,0) [0|1] "" Vector__XXX
 SG_ EVCC_evt_CpFreqFailr : 33|1@0+ (1,0) [0|1] "" Vector__XXX
 SG_ EVCC_evt_bPmicOV : 34|1@0+ (1,0) [0|1] "" Vector__XXX
 SG_ EVCC_evt_bPmicUV : 35|1@0+ (1,0) [0|1] "" Vector__XXX
 SG_ EVCC_evt_bMissCvcMsg : 36|1@0+ (1,0) [0|1] "" Vector__XXX
 SG_ EVCC_evt_bMissBmsMsg : 37|1@0+ (1,0) [0|1] "" Vector__XXX
 SG_ EVCC_evt_bMissPodMsg : 38|1@0+ (1,0) [0|1] "" Vector__XXX
 SG_ EVCC_evt_bMissBcmMsg : 39|1@0+ (1,0) [0|1] "" Vector__XXX
 SG_ EVCC_evt_bE2eCvcMsg : 40|1@0+ (1,0) [0|1] "" Vector__XXX
 SG_ EVCC_evt_bE2eBmsMsg : 41|1@0+ (1,0) [0|1] "" Vector__XXX
 SG_ EVCC_evt_bE2ePodMsg : 42|1@0+ (1,0) [0|1] "" Vector__XXX
 SG_ EVCC_evt_bE2eBcmMsg : 43|1@0+ (1,0) [0|1] "" Vector__XXX
 SG_ EVCC_evt_ChgGunHBOvTemp : 44|1@0+ (1,0) [0|1] "" Vector__XXX
 SG_ EVCC_evt_ChgGunHBOCVCrr : 45|1@0+ (1,0) [0|1] "" Vector__XXX
 SG_ EVCC_evt_ChgGunHBOpnCir : 46|1@0+ (1,0) [0|1] "" Vector__XXX
 SG_ EVCC_evt_ChgGunHBShtBatt : 47|1@0+ (1,0) [0|1] "" Vector__XXX
 SG_ EVCC_evt_ChgFlapHBPorErr : 48|1@0+ (1,0) [0|1] "" Vector__XXX
 SG_ EVCC_evt_ChgFlapHBSpiComErr : 49|1@0+ (1,0) [0|1] "" Vector__XXX
 SG_ EVCC_evt_ChgGunHBPorErr : 50|1@0+ (1,0) [0|1] "" Vector__XXX
 SG_ EVCC_evt_ChgGunHBShtGnd : 51|1@0+ (1,0) [0|1] "" Vector__XXX
 SG_ EVCC_evt_DcNTmpShortVcc : 52|1@0+ (1,0) [0|1] "" Vector__XXX
 SG_ EVCC_evt_DcNTmpShortGnd : 53|1@0+ (1,0) [0|1] "" Vector__XXX
 SG_ EVCC_evt_L2ChkErr : 54|1@0+ (1,0) [0|1] "" Vector__XXX
 SG_ EVCC_evt_ChgTypeErr : 55|1@0+ (1,0) [0|1] "" Vector__XXX
 SG_ EVCC_evt_ChgGunHBSpiComErr : 56|1@0+ (1,0) [0|1] "" Vector__XXX
 SG_ EVCC_evt_PreconditionFlt : 57|1@0+ (1,0) [0|1] "" Vector__XXX
 SG_ EVCC_evt_eChrgnUpEvseNotRdy : 58|1@0+ (1,0) [0|1] "" Vector__XXX
 SG_ EVCC_evt_eChrgUpV2GIdle : 59|1@0+ (1,0) [0|1] "" Vector__XXX
 SG_ EVCC_evt_eChrg69CpNot9 : 60|1@0+ (1,0) [0|1] "" Vector__XXX
 SG_ EVCC_evt_eCoEssChModFlt : 61|1@0+ (1,0) [0|1] "" Vector__XXX
 SG_ EVCC_evt_eChrgUpEvseNotifStp : 62|1@0+ (1,0) [0|1] "" Vector__XXX
 SG_ EVCC_evt_ePLCSubTimeOut : 63|1@0+ (1,0) [0|1] "" Vector__XXX

BO_ 1146 BMS_SOCDiag: 8 BMS
 SG_ BMS_CellMaxSOC : 1|10@0+ (0.1,0) [0|100] "%"  FMCU
 SG_ BMS_CellMinSOC : 17|10@0+ (0.1,0) [0|100] "%"  FMCU
 SG_ BMS_CorrectedSOC : 33|10@0+ (0.1,0) [0|100] "%" Vector__XXX
 SG_ BMS_PackSOCDiff : 49|10@0+ (0.1,0) [0|100] "%" Vector__XXX

BO_ 1147 EVCC_EventMatrix_2: 8 EVCC
 SG_ EVCC_evt_ExtHiSide1HBOpnCir : 0|1@0+ (1,0) [0|1] "" Vector__XXX
 SG_ EVCC_evt_ExtHiSide2HBOpnCir : 1|1@0+ (1,0) [0|1] "" Vector__XXX
 SG_ EVCC_evt_ExtHiSide3HBOpnCir : 2|1@0+ (1,0) [0|1] "" Vector__XXX
 SG_ EVCC_evt_ExtHiSide4HBOpnCir : 3|1@0+ (1,0) [0|1] "" Vector__XXX
 SG_ EVCC_evt_ExtHiSide5HBOpnCir : 4|1@0+ (1,0) [0|1] "" Vector__XXX
 SG_ EVCC_evt_ExtHiSide1HBOCVCrr : 5|1@0+ (1,0) [0|1] "" Vector__XXX
 SG_ EVCC_evt_ExtHiSide2HBOCVCrr : 6|1@0+ (1,0) [0|1] "" Vector__XXX
 SG_ EVCC_evt_ExtHiSide3HBOCVCrr : 7|1@0+ (1,0) [0|1] "" Vector__XXX
 SG_ EVCC_evt_ExtHiSide4HBOCVCrr : 8|1@0+ (1,0) [0|1] "" Vector__XXX
 SG_ EVCC_evt_ExtHiSide5HBOCVCrr : 9|1@0+ (1,0) [0|1] "" Vector__XXX
 SG_ EVCC_evt_ExtHiSideHBShtBatt : 10|1@0+ (1,0) [0|1] "" Vector__XXX
 SG_ EVCC_evt_ExtHiSideHBShtGnd : 11|1@0+ (1,0) [0|1] "" Vector__XXX
 SG_ EVCC_evt_ExtHiSideHBTempOv : 12|1@0+ (1,0) [0|1] "" Vector__XXX
 SG_ EVCC_evt_ExtHiSideHBPorErr : 13|1@0+ (1,0) [0|1] "" Vector__XXX
 SG_ EVCC_evt_ExtHiSideHBTempWn : 14|1@0+ (1,0) [0|1] "" Vector__XXX
 SG_ EVCC_evt_ExtLoSide1HBOpnCir : 15|1@0+ (1,0) [0|1] "" Vector__XXX
 SG_ EVCC_evt_ExtLoSide2HBOpnCir : 16|1@0+ (1,0) [0|1] "" Vector__XXX
 SG_ EVCC_evt_ExtLoSide3HBOpnCir : 17|1@0+ (1,0) [0|1] "" Vector__XXX
 SG_ EVCC_evt_ExtLoSide4HBOpnCir : 18|1@0+ (1,0) [0|1] "" Vector__XXX
 SG_ EVCC_evt_ExtLoSide5HBOpnCir : 19|1@0+ (1,0) [0|1] "" Vector__XXX
 SG_ EVCC_evt_ExtLoSide1HBOCVCrr : 20|1@0+ (1,0) [0|1] "" Vector__XXX
 SG_ EVCC_evt_ExtLoSide2HBOCVCrr : 21|1@0+ (1,0) [0|1] "" Vector__XXX
 SG_ EVCC_evt_ExtLoSide3HBOCVCrr : 22|1@0+ (1,0) [0|1] "" Vector__XXX
 SG_ EVCC_evt_ExtLoSide4HBOCVCrr : 23|1@0+ (1,0) [0|1] "" Vector__XXX
 SG_ EVCC_evt_ExtLoSide5HBOCVCrr : 24|1@0+ (1,0) [0|1] "" Vector__XXX
 SG_ EVCC_evt_ExtLoSideHBShtBatt : 25|1@0+ (1,0) [0|1] "" Vector__XXX
 SG_ EVCC_evt_ExtLoSideHBShtGnd : 26|1@0+ (1,0) [0|1] "" Vector__XXX
 SG_ EVCC_evt_ExtLoSideHBTempOv : 27|1@0+ (1,0) [0|1] "" Vector__XXX
 SG_ EVCC_evt_ExtLoSideHBPorErr : 28|1@0+ (1,0) [0|1] "" Vector__XXX
 SG_ EVCC_evt_ExtLoSideHBTempWn : 29|1@0+ (1,0) [0|1] "" Vector__XXX
 SG_ EVCC_bChEndLongDeb : 30|1@0+ (1,0) [0|1] "" Vector__XXX
 SG_ EVCC_bChEndShortDeb : 31|1@0+ (1,0) [0|1] "" Vector__XXX
 SG_ EVCC_stV2GErr : 32|1@0+ (1,0) [0|1] "" Vector__XXX
 SG_ EVCC_stSup : 33|1@0+ (1,0) [0|1] "" Vector__XXX

BO_ 1171 BMS_WarnMsg: 8 BMS
 SG_ CHSKM_BMS_WarnMsg : 7|8@0+ (1,0) [0|255] ""  CVC_P
 SG_ ALV_BMS_WarnMsg : 11|4@0+ (1,0) [0|15] ""  CVC_P
 SG_ BMS_PackTempSts : 13|2@0+ (1,0) [0|3] ""  CVC_P
 SG_ BMS_ThermalRunaway : 14|1@0+ (1,0) [0|1] ""  CVC_P
 SG_ BMS_BatteryReplacement : 15|1@0+ (1,0) [0|1] ""  CVC_P
 SG_ BMS_Warning_PowerDegrade : 16|1@0+ (1,0) [0|1] ""  CVC_P
 SG_ BMS_Warning_DeltaSoC : 17|1@0+ (1,0) [0|1] ""  CVC_P
 SG_ BMS_Warning_HVILSts : 18|1@0+ (1,0) [0|1] ""  CVC_P
 SG_ BMS_Warning_Isolation : 19|1@0+ (1,0) [0|1] ""  CVC_P
 SG_ BMS_Warning_CoolantLeakage : 20|1@0+ (1,0) [0|1] ""  CVC_P
 SG_ BMS_MalfunctionSts : 21|1@0+ (1,0) [0|1] ""  CVC_P
 SG_ BMS_LowBattery : 23|2@0+ (1,0) [0|3] ""  CVC_P
 SG_ BMS_Warning_DeltaTemperature : 31|8@0+ (1,0) [0|255] ""  CVC_P
 SG_ BMS_Warning_BDUTemperatureSts : 39|8@0+ (1,0) [0|255] ""  CVC_P
 SG_ BMS_Warning_Contactor_Aging : 47|1@0+ (1,0) [0|1] ""  CVC_P
 SG_ BMS_Reserved_signal4 : 55|8@0+ (1,0) [0|255] ""  CVC_P
 SG_ BMS_Reserved_signal5 : 63|8@0+ (1,0) [0|255] ""  CVC_P

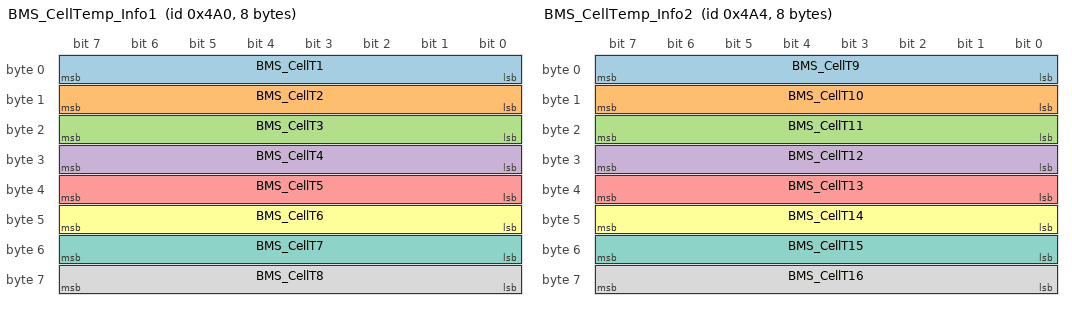
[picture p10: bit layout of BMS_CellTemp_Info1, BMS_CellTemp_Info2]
BO_ 1184 BMS_CellTemp_Info1: 8 BMS
 SG_ BMS_CellT1 : 7|8@0+ (1,-40) [-40|210] "℃" Vector__XXX
 SG_ BMS_CellT2 : 15|8@0+ (1,-40) [-40|210] "℃" Vector__XXX
 SG_ BMS_CellT3 : 23|8@0+ (1,-40) [-40|210] "℃" Vector__XXX
 SG_ BMS_CellT4 : 31|8@0+ (1,-40) [-40|210] "℃" Vector__XXX
 SG_ BMS_CellT5 : 39|8@0+ (1,-40) [-40|210] "℃" Vector__XXX
 SG_ BMS_CellT6 : 47|8@0+ (1,-40) [-40|210] "℃" Vector__XXX
 SG_ BMS_CellT7 : 55|8@0+ (1,-40) [-40|210] "℃" Vector__XXX
 SG_ BMS_CellT8 : 63|8@0+ (1,-40) [-40|210] "℃" Vector__XXX

BO_ 1188 BMS_CellTemp_Info2: 8 BMS
 SG_ BMS_CellT9 : 7|8@0+ (1,-40) [-40|210] "℃" Vector__XXX
 SG_ BMS_CellT10 : 15|8@0+ (1,-40) [-40|210] "℃" Vector__XXX
 SG_ BMS_CellT11 : 23|8@0+ (1,-40) [-40|210] "℃" Vector__XXX
 SG_ BMS_CellT12 : 31|8@0+ (1,-40) [-40|210] "℃" Vector__XXX
 SG_ BMS_CellT13 : 39|8@0+ (1,-40) [-40|210] "℃" Vector__XXX
 SG_ BMS_CellT14 : 47|8@0+ (1,-40) [-40|210] "℃" Vector__XXX
 SG_ BMS_CellT15 : 55|8@0+ (1,-40) [-40|210] "℃" Vector__XXX
 SG_ BMS_CellT16 : 63|8@0+ (1,-40) [-40|210] "℃" Vector__XXX

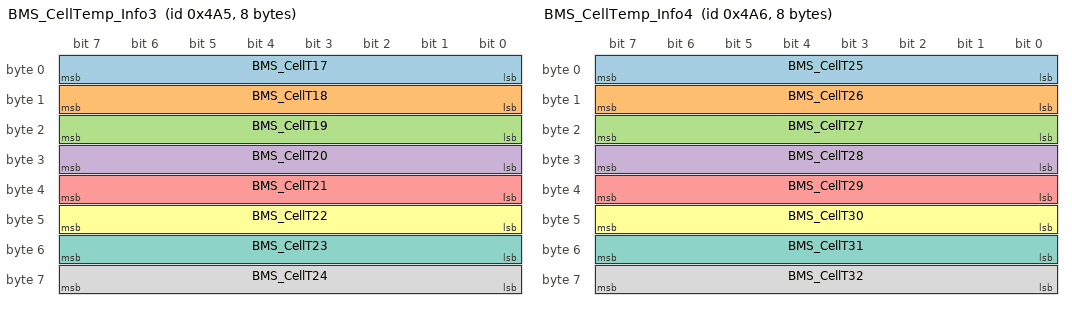
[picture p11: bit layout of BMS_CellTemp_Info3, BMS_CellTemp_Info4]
BO_ 1189 BMS_CellTemp_Info3: 8 BMS
 SG_ BMS_CellT17 : 7|8@0+ (1,-40) [-40|210] "℃" Vector__XXX
 SG_ BMS_CellT18 : 15|8@0+ (1,-40) [-40|210] "℃" Vector__XXX
 SG_ BMS_CellT19 : 23|8@0+ (1,-40) [-40|210] "℃" Vector__XXX
 SG_ BMS_CellT20 : 31|8@0+ (1,-40) [-40|210] "℃" Vector__XXX
 SG_ BMS_CellT21 : 39|8@0+ (1,-40) [-40|210] "℃" Vector__XXX
 SG_ BMS_CellT22 : 47|8@0+ (1,-40) [-40|210] "℃" Vector__XXX
 SG_ BMS_CellT23 : 55|8@0+ (1,-40) [-40|210] "℃" Vector__XXX
 SG_ BMS_CellT24 : 63|8@0+ (1,-40) [-40|210] "℃" Vector__XXX

BO_ 1190 BMS_CellTemp_Info4: 8 BMS
 SG_ BMS_CellT25 : 7|8@0+ (1,-40) [-40|210] "℃" Vector__XXX
 SG_ BMS_CellT26 : 15|8@0+ (1,-40) [-40|210] "℃" Vector__XXX
 SG_ BMS_CellT27 : 23|8@0+ (1,-40) [-40|210] "℃" Vector__XXX
 SG_ BMS_CellT28 : 31|8@0+ (1,-40) [-40|210] "℃" Vector__XXX
 SG_ BMS_CellT29 : 39|8@0+ (1,-40) [-40|210] "℃" Vector__XXX
 SG_ BMS_CellT30 : 47|8@0+ (1,-40) [-40|210] "℃" Vector__XXX
 SG_ BMS_CellT31 : 55|8@0+ (1,-40) [-40|210] "℃" Vector__XXX
 SG_ BMS_CellT32 : 63|8@0+ (1,-40) [-40|210] "℃" Vector__XXX

BO_ 1191 BMS_CellTemp_Info5: 8 BMS
 SG_ BMS_CellT33 : 7|8@0+ (1,-40) [-40|210] "℃" Vector__XXX
 SG_ BMS_CellT34 : 15|8@0+ (1,-40) [-40|210] "℃" Vector__XXX
 SG_ BMS_CellT35 : 23|8@0+ (1,-40) [-40|210] "℃" Vector__XXX
 SG_ BMS_CellT36 : 31|8@0+ (1,-40) [-40|210] "℃" Vector__XXX

BO_ 1192 BMS_CellVolt_Info01: 8 BMS
 SG_ BMS_CellVolt_1 : 7|16@0+ (0.001,0) [0|5] "V" Vector__XXX
 SG_ BMS_CellVolt_2 : 23|16@0+ (0.001,0) [0|5] "V" Vector__XXX
 SG_ BMS_CellVolt_3 : 39|16@0+ (0.001,0) [0|5] "V" Vector__XXX
 SG_ BMS_CellVolt_4 : 55|16@0+ (0.001,0) [0|5] "V" Vector__XXX

BO_ 1193 BMS_CellVolt_Info02: 8 BMS
 SG_ BMS_CellVolt_5 : 7|16@0+ (0.001,0) [0|5] "V" Vector__XXX
 SG_ BMS_CellVolt_6 : 23|16@0+ (0.001,0) [0|5] "V" Vector__XXX
 SG_ BMS_CellVolt_7 : 39|16@0+ (0.001,0) [0|5] "V" Vector__XXX
 SG_ BMS_CellVolt_8 : 55|16@0+ (0.001,0) [0|5] "V" Vector__XXX

BO_ 1196 BMS_CellVolt_Info03: 8 BMS
 SG_ BMS_CellVolt_9 : 7|16@0+ (0.001,0) [0|5] "V" Vector__XXX
 SG_ BMS_CellVolt_10 : 23|16@0+ (0.001,0) [0|5] "V" Vector__XXX
 SG_ BMS_CellVolt_11 : 39|16@0+ (0.001,0) [0|5] "V" Vector__XXX
 SG_ BMS_CellVolt_12 : 55|16@0+ (0.001,0) [0|5] "V" Vector__XXX

BO_ 1197 BMS_CellVolt_Info04: 8 BMS
 SG_ BMS_CellVolt_13 : 7|16@0+ (0.001,0) [0|5] "V" Vector__XXX
 SG_ BMS_CellVolt_14 : 23|16@0+ (0.001,0) [0|5] "V" Vector__XXX
 SG_ BMS_CellVolt_15 : 39|16@0+ (0.001,0) [0|5] "V" Vector__XXX
 SG_ BMS_CellVolt_16 : 55|16@0+ (0.001,0) [0|5] "V" Vector__XXX

BO_ 1198 BMS_CellVolt_Info05: 8 BMS
 SG_ BMS_CellVolt_17 : 7|16@0+ (0.001,0) [0|5] "V" Vector__XXX
 SG_ BMS_CellVolt_18 : 23|16@0+ (0.001,0) [0|5] "V" Vector__XXX
 SG_ BMS_CellVolt_19 : 39|16@0+ (0.001,0) [0|5] "V" Vector__XXX
 SG_ BMS_CellVolt_20 : 55|16@0+ (0.001,0) [0|5] "V" Vector__XXX

BO_ 1199 BMS_CellVolt_Info06: 8 BMS
 SG_ BMS_CellVolt_21 : 7|16@0+ (0.001,0) [0|5] "V" Vector__XXX
 SG_ BMS_CellVolt_22 : 23|16@0+ (0.001,0) [0|5] "V" Vector__XXX
 SG_ BMS_CellVolt_23 : 39|16@0+ (0.001,0) [0|5] "V" Vector__XXX
 SG_ BMS_CellVolt_24 : 55|16@0+ (0.001,0) [0|5] "V" Vector__XXX

BO_ 1200 BMS_CellVolt_Info07: 8 BMS
 SG_ BMS_CellVolt_25 : 7|16@0+ (0.001,0) [0|5] "V" Vector__XXX
 SG_ BMS_CellVolt_26 : 23|16@0+ (0.001,0) [0|5] "V" Vector__XXX
 SG_ BMS_CellVolt_27 : 39|16@0+ (0.001,0) [0|5] "V" Vector__XXX
 SG_ BMS_CellVolt_28 : 55|16@0+ (0.001,0) [0|5] "V" Vector__XXX

BO_ 1201 BMS_CellVolt_Info08: 8 BMS
 SG_ BMS_CellVolt_29 : 7|16@0+ (0.001,0) [0|5] "V" Vector__XXX
 SG_ BMS_CellVolt_30 : 23|16@0+ (0.001,0) [0|5] "V" Vector__XXX
 SG_ BMS_CellVolt_31 : 39|16@0+ (0.001,0) [0|5] "V" Vector__XXX
 SG_ BMS_CellVolt_32 : 55|16@0+ (0.001,0) [0|5] "V" Vector__XXX

BO_ 1202 BMS_CellVolt_Info09: 8 BMS
 SG_ BMS_CellVolt_33 : 7|16@0+ (0.001,0) [0|5] "V" Vector__XXX
 SG_ BMS_CellVolt_34 : 23|16@0+ (0.001,0) [0|5] "V" Vector__XXX
 SG_ BMS_CellVolt_35 : 39|16@0+ (0.001,0) [0|5] "V" Vector__XXX
 SG_ BMS_CellVolt_36 : 55|16@0+ (0.001,0) [0|5] "V" Vector__XXX

BO_ 1203 BMS_CellVolt_Info10: 8 BMS
 SG_ BMS_CellVolt_37 : 7|16@0+ (0.001,0) [0|5] "V" Vector__XXX
 SG_ BMS_CellVolt_38 : 23|16@0+ (0.001,0) [0|5] "V" Vector__XXX
 SG_ BMS_CellVolt_39 : 39|16@0+ (0.001,0) [0|5] "V" Vector__XXX
 SG_ BMS_CellVolt_40 : 55|16@0+ (0.001,0) [0|5] "V" Vector__XXX

BO_ 1204 BMS_CellVolt_Info11: 8 BMS
 SG_ BMS_CellVolt_41 : 7|16@0+ (0.001,0) [0|5] "V" Vector__XXX
 SG_ BMS_CellVolt_42 : 23|16@0+ (0.001,0) [0|5] "V" Vector__XXX
 SG_ BMS_CellVolt_43 : 39|16@0+ (0.001,0) [0|5] "V" Vector__XXX
 SG_ BMS_CellVolt_44 : 55|16@0+ (0.001,0) [0|5] "V" Vector__XXX

BO_ 1205 BMS_CellVolt_Info12: 8 BMS
 SG_ BMS_CellVolt_45 : 7|16@0+ (0.001,0) [0|5] "V" Vector__XXX
 SG_ BMS_CellVolt_46 : 23|16@0+ (0.001,0) [0|5] "V" Vector__XXX
 SG_ BMS_CellVolt_47 : 39|16@0+ (0.001,0) [0|5] "V" Vector__XXX
 SG_ BMS_CellVolt_48 : 55|16@0+ (0.001,0) [0|5] "V" Vector__XXX

BO_ 1206 BMS_CellVolt_Info13: 8 BMS
 SG_ BMS_CellVolt_49 : 7|16@0+ (0.001,0) [0|5] "V" Vector__XXX
 SG_ BMS_CellVolt_50 : 23|16@0+ (0.001,0) [0|5] "V" Vector__XXX
 SG_ BMS_CellVolt_51 : 39|16@0+ (0.001,0) [0|5] "V" Vector__XXX
 SG_ BMS_CellVolt_52 : 55|16@0+ (0.001,0) [0|5] "V" Vector__XXX

BO_ 1207 BMS_CellVolt_Info14: 8 BMS
 SG_ BMS_CellVolt_53 : 7|16@0+ (0.001,0) [0|5] "V" Vector__XXX
 SG_ BMS_CellVolt_54 : 23|16@0+ (0.001,0) [0|5] "V" Vector__XXX
 SG_ BMS_CellVolt_55 : 39|16@0+ (0.001,0) [0|5] "V" Vector__XXX
 SG_ BMS_CellVolt_56 : 55|16@0+ (0.001,0) [0|5] "V" Vector__XXX

BO_ 1208 BMS_CellVolt_Info15: 8 BMS
 SG_ BMS_CellVolt_57 : 7|16@0+ (0.001,0) [0|5] "V" Vector__XXX
 SG_ BMS_CellVolt_58 : 23|16@0+ (0.001,0) [0|5] "V" Vector__XXX
 SG_ BMS_CellVolt_59 : 39|16@0+ (0.001,0) [0|5] "V" Vector__XXX
 SG_ BMS_CellVolt_60 : 55|16@0+ (0.001,0) [0|5] "V" Vector__XXX

BO_ 1209 BMS_CellVolt_Info16: 8 BMS
 SG_ BMS_CellVolt_61 : 7|16@0+ (0.001,0) [0|5] "V" Vector__XXX
 SG_ BMS_CellVolt_62 : 23|16@0+ (0.001,0) [0|5] "V" Vector__XXX
 SG_ BMS_CellVolt_63 : 39|16@0+ (0.001,0) [0|5] "V" Vector__XXX
 SG_ BMS_CellVolt_64 : 55|16@0+ (0.001,0) [0|5] "V" Vector__XXX

BO_ 1210 BMS_CellVolt_Info17: 8 BMS
 SG_ BMS_CellVolt_65 : 7|16@0+ (0.001,0) [0|5] "V" Vector__XXX
 SG_ BMS_CellVolt_66 : 23|16@0+ (0.001,0) [0|5] "V" Vector__XXX
 SG_ BMS_CellVolt_67 : 39|16@0+ (0.001,0) [0|5] "V" Vector__XXX
 SG_ BMS_CellVolt_68 : 55|16@0+ (0.001,0) [0|5] "V" Vector__XXX

BO_ 1211 BMS_CellVolt_Info18: 8 BMS
 SG_ BMS_CellVolt_69 : 7|16@0+ (0.001,0) [0|5] "V" Vector__XXX
 SG_ BMS_CellVolt_70 : 23|16@0+ (0.001,0) [0|5] "V" Vector__XXX
 SG_ BMS_CellVolt_71 : 39|16@0+ (0.001,0) [0|5] "V" Vector__XXX
 SG_ BMS_CellVolt_72 : 55|16@0+ (0.001,0) [0|5] "V" Vector__XXX

BO_ 1212 BMS_CellVolt_Info19: 8 BMS
 SG_ BMS_CellVolt_73 : 7|16@0+ (0.001,0) [0|5] "V" Vector__XXX
 SG_ BMS_CellVolt_74 : 23|16@0+ (0.001,0) [0|5] "V" Vector__XXX
 SG_ BMS_CellVolt_75 : 39|16@0+ (0.001,0) [0|5] "V" Vector__XXX
 SG_ BMS_CellVolt_76 : 55|16@0+ (0.001,0) [0|5] "V" Vector__XXX

BO_ 1213 BMS_CellVolt_Info20: 8 BMS
 SG_ BMS_CellVolt_77 : 7|16@0+ (0.001,0) [0|5] "V" Vector__XXX
 SG_ BMS_CellVolt_78 : 23|16@0+ (0.001,0) [0|5] "V" Vector__XXX
 SG_ BMS_CellVolt_79 : 39|16@0+ (0.001,0) [0|5] "V" Vector__XXX
 SG_ BMS_CellVolt_80 : 55|16@0+ (0.001,0) [0|5] "V" Vector__XXX

BO_ 1214 BMS_CellVolt_Info21: 8 BMS
 SG_ BMS_CellVolt_81 : 7|16@0+ (0.001,0) [0|5] "V" Vector__XXX
 SG_ BMS_CellVolt_82 : 23|16@0+ (0.001,0) [0|5] "V" Vector__XXX
 SG_ BMS_CellVolt_83 : 39|16@0+ (0.001,0) [0|5] "V" Vector__XXX
 SG_ BMS_CellVolt_84 : 55|16@0+ (0.001,0) [0|5] "V" Vector__XXX

BO_ 1215 BMS_CellVolt_Info22: 8 BMS
 SG_ BMS_CellVolt_85 : 7|16@0+ (0.001,0) [0|5] "V" Vector__XXX
 SG_ BMS_CellVolt_86 : 23|16@0+ (0.001,0) [0|5] "V" Vector__XXX
 SG_ BMS_CellVolt_87 : 39|16@0+ (0.001,0) [0|5] "V" Vector__XXX
 SG_ BMS_CellVolt_88 : 55|16@0+ (0.001,0) [0|5] "V" Vector__XXX

BO_ 1216 BMS_CellVolt_Info23: 8 BMS
 SG_ BMS_CellVolt_89 : 7|16@0+ (0.001,0) [0|5] "V" Vector__XXX
 SG_ BMS_CellVolt_90 : 23|16@0+ (0.001,0) [0|5] "V" Vector__XXX
 SG_ BMS_CellVolt_91 : 39|16@0+ (0.001,0) [0|5] "V" Vector__XXX
 SG_ BMS_CellVolt_92 : 55|16@0+ (0.001,0) [0|5] "V" Vector__XXX

BO_ 1217 BMS_CellVolt_Info24: 8 BMS
 SG_ BMS_CellVolt_93 : 7|16@0+ (0.001,0) [0|5] "V" Vector__XXX
 SG_ BMS_CellVolt_94 : 23|16@0+ (0.001,0) [0|5] "V" Vector__XXX
 SG_ BMS_CellVolt_95 : 39|16@0+ (0.001,0) [0|5] "V" Vector__XXX
 SG_ BMS_CellVolt_96 : 55|16@0+ (0.001,0) [0|5] "V" Vector__XXX

BO_ 1218 BMS_CellVolt_Info25: 8 BMS
 SG_ BMS_CellVolt_97 : 7|16@0+ (0.001,0) [0|5] "V" Vector__XXX
 SG_ BMS_CellVolt_98 : 23|16@0+ (0.001,0) [0|5] "V" Vector__XXX
 SG_ BMS_CellVolt_99 : 39|16@0+ (0.001,0) [0|5] "V" Vector__XXX
 SG_ BMS_CellVolt_100 : 55|16@0+ (0.001,0) [0|5] "V" Vector__XXX

BO_ 1219 BMS_CellVolt_Info26: 8 BMS
 SG_ BMS_CellVolt_101 : 7|16@0+ (0.001,0) [0|5] "V" Vector__XXX
 SG_ BMS_CellVolt_102 : 23|16@0+ (0.001,0) [0|5] "V" Vector__XXX
 SG_ BMS_CellVolt_103 : 39|16@0+ (0.001,0) [0|5] "V" Vector__XXX
 SG_ BMS_CellVolt_104 : 55|16@0+ (0.001,0) [0|5] "V" Vector__XXX

BO_ 1220 BMS_CellVolt_Info27: 8 BMS
 SG_ BMS_CellVolt_105 : 7|16@0+ (0.001,0) [0|5] "V" Vector__XXX
 SG_ BMS_CellVolt_106 : 23|16@0+ (0.001,0) [0|5] "V" Vector__XXX
 SG_ BMS_CellVolt_107 : 39|16@0+ (0.001,0) [0|5] "V" Vector__XXX
 SG_ BMS_CellVolt_108 : 55|16@0+ (0.001,0) [0|5] "V" Vector__XXX

BO_ 1221 BMS_CellVolt_Info28: 8 BMS
 SG_ BMS_CellVolt_109 : 7|16@0+ (0.001,0) [0|5] "V" Vector__XXX
 SG_ BMS_CellVolt_110 : 23|16@0+ (0.001,0) [0|5] "V" Vector__XXX
 SG_ BMS_CellVolt_111 : 39|16@0+ (0.001,0) [0|5] "V" Vector__XXX
 SG_ BMS_CellVolt_112 : 55|16@0+ (0.001,0) [0|5] "V" Vector__XXX

BO_ 1222 BMS_CellVolt_Info29: 8 BMS
 SG_ BMS_CellVolt_113 : 7|16@0+ (0.001,0) [0|5] "V" Vector__XXX
 SG_ BMS_CellVolt_114 : 23|16@0+ (0.001,0) [0|5] "V" Vector__XXX
 SG_ BMS_CellVolt_115 : 39|16@0+ (0.001,0) [0|5] "V" Vector__XXX
 SG_ BMS_CellVolt_116 : 55|16@0+ (0.001,0) [0|5] "V" Vector__XXX

BO_ 1223 BMS_CellVolt_Info30: 8 BMS
 SG_ BMS_CellVolt_117 : 7|16@0+ (0.001,0) [0|5] "V" Vector__XXX
 SG_ BMS_CellVolt_118 : 23|16@0+ (0.001,0) [0|5] "V" Vector__XXX
 SG_ BMS_CellVolt_119 : 39|16@0+ (0.001,0) [0|5] "V" Vector__XXX
 SG_ BMS_CellVolt_120 : 55|16@0+ (0.001,0) [0|5] "V" Vector__XXX

BO_ 1224 BMS_CellVolt_Info31: 8 BMS
 SG_ BMS_CellVolt_121 : 7|16@0+ (0.001,0) [0|5] "V" Vector__XXX
 SG_ BMS_CellVolt_122 : 23|16@0+ (0.001,0) [0|5] "V" Vector__XXX
 SG_ BMS_CellVolt_123 : 39|16@0+ (0.001,0) [0|5] "V" Vector__XXX
 SG_ BMS_CellVolt_124 : 55|16@0+ (0.001,0) [0|5] "V" Vector__XXX

BO_ 1225 BMS_CellVolt_Info32: 8 BMS
 SG_ BMS_CellVolt_125 : 7|16@0+ (0.001,0) [0|5] "V" Vector__XXX
 SG_ BMS_CellVolt_126 : 23|16@0+ (0.001,0) [0|5] "V" Vector__XXX
 SG_ BMS_KL30_Voltage : 39|16@0+ (0.001,0) [0|18] "V" Vector__XXX

BO_ 1226 BMS_BPSCVS_SnsrInfor: 8 BMS
 SG_ BMS_BPS_pressureValue : 7|16@0+ (0.1,0) [0|409.5] "kpa" Vector__XXX
 SG_ BMS_CVS_Temperature : 23|16@0+ (1,-50) [-50|150] "Degree C" Vector__XXX

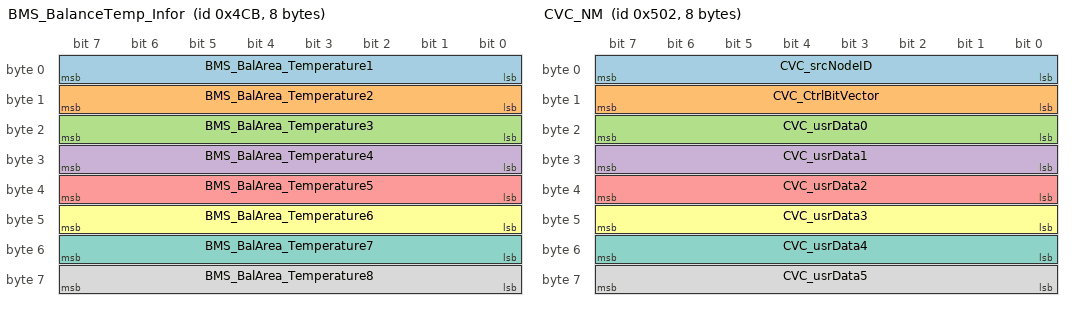
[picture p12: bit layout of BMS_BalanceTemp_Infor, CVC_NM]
BO_ 1227 BMS_BalanceTemp_Infor: 8 BMS
 SG_ BMS_BalArea_Temperature1 : 7|8@0+ (1,-50) [-50|150] "Degree C" Vector__XXX
 SG_ BMS_BalArea_Temperature2 : 15|8@0+ (1,-50) [-50|150] "Degree C" Vector__XXX
 SG_ BMS_BalArea_Temperature3 : 23|8@0+ (1,-50) [-50|150] "Degree C" Vector__XXX
 SG_ BMS_BalArea_Temperature4 : 31|8@0+ (1,-50) [-50|150] "Degree C" Vector__XXX
 SG_ BMS_BalArea_Temperature5 : 39|8@0+ (1,-50) [-50|150] "Degree C" Vector__XXX
 SG_ BMS_BalArea_Temperature6 : 47|8@0+ (1,-50) [-50|150] "Degree C" Vector__XXX
 SG_ BMS_BalArea_Temperature7 : 55|8@0+ (1,-50) [-50|150] "Degree C" Vector__XXX
 SG_ BMS_BalArea_Temperature8 : 63|8@0+ (1,-50) [-50|150] "Degree C" Vector__XXX

BO_ 1282 CVC_NM: 8 CVC_P
 SG_ CVC_srcNodeID : 7|8@0+ (1,0) [0|255] ""  FMCU,PDU,BMS,CCU,EAC,PTC,EVCC
 SG_ CVC_CtrlBitVector : 15|8@0+ (1,0) [0|255] ""  FMCU,PDU,BMS,CCU,EAC,PTC,EVCC
 SG_ CVC_usrData0 : 23|8@0+ (1,0) [0|255] ""  FMCU,PDU,BMS,CCU,EAC,PTC,EVCC
 SG_ CVC_usrData1 : 31|8@0+ (1,0) [0|255] ""  FMCU,PDU,BMS,CCU,EAC,PTC,EVCC
 SG_ CVC_usrData2 : 39|8@0+ (1,0) [0|255] ""  FMCU,PDU,BMS,CCU,EAC,PTC,EVCC
 SG_ CVC_usrData3 : 47|8@0+ (1,0) [0|255] ""  FMCU,PDU,BMS,CCU,EAC,PTC,EVCC
 SG_ CVC_usrData4 : 55|8@0+ (1,0) [0|255] ""  FMCU,PDU,BMS,CCU,EAC,PTC,EVCC
 SG_ CVC_usrData5 : 63|8@0+ (1,0) [0|255] ""  FMCU,PDU,BMS,CCU,EAC,PTC,EVCC

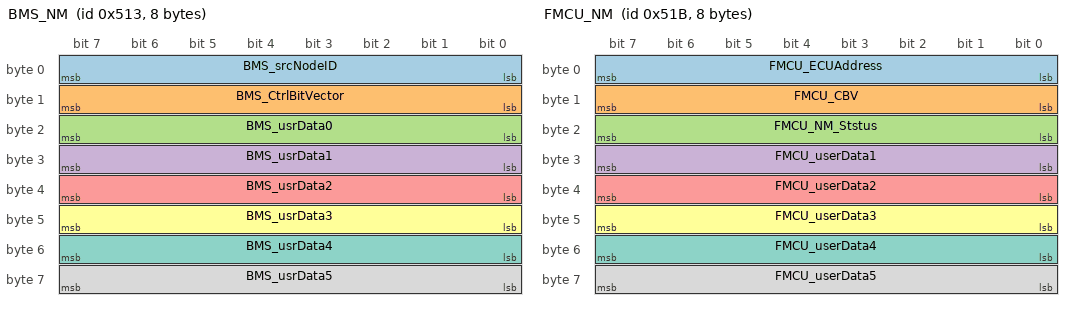
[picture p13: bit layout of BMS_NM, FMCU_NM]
BO_ 1299 BMS_NM: 8 BMS
 SG_ BMS_srcNodeID : 7|8@0+ (1,0) [0|255] ""  CVC_P,EVCC
 SG_ BMS_CtrlBitVector : 15|8@0+ (1,0) [0|255] ""  CVC_P,EVCC
 SG_ BMS_usrData0 : 23|8@0+ (1,0) [0|255] ""  CVC_P,EVCC
 SG_ BMS_usrData1 : 31|8@0+ (1,0) [0|255] ""  CVC_P,EVCC
 SG_ BMS_usrData2 : 39|8@0+ (1,0) [0|255] ""  CVC_P,EVCC
 SG_ BMS_usrData3 : 47|8@0+ (1,0) [0|255] ""  CVC_P,EVCC
 SG_ BMS_usrData4 : 55|8@0+ (1,0) [0|255] ""  CVC_P,EVCC
 SG_ BMS_usrData5 : 63|8@0+ (1,0) [0|255] ""  CVC_P,EVCC

BO_ 1307 FMCU_NM: 8 FMCU
 SG_ FMCU_ECUAddress : 7|8@0+ (1,0) [0|255] ""  CVC_P,PDU,BMS
 SG_ FMCU_CBV : 15|8@0+ (1,0) [0|255] ""  CVC_P,PDU,BMS
 SG_ FMCU_NM_Ststus : 23|8@0+ (1,0) [0|255] ""  CVC_P,PDU,BMS
 SG_ FMCU_userData1 : 31|8@0+ (1,0) [0|255] ""  CVC_P,PDU,BMS
 SG_ FMCU_userData2 : 39|8@0+ (1,0) [0|255] ""  CVC_P,PDU,BMS
 SG_ FMCU_userData3 : 47|8@0+ (1,0) [0|255] ""  CVC_P,PDU,BMS
 SG_ FMCU_userData4 : 55|8@0+ (1,0) [0|255] ""  CVC_P,PDU,BMS
 SG_ FMCU_userData5 : 63|8@0+ (1,0) [0|255] ""  CVC_P,PDU,BMS

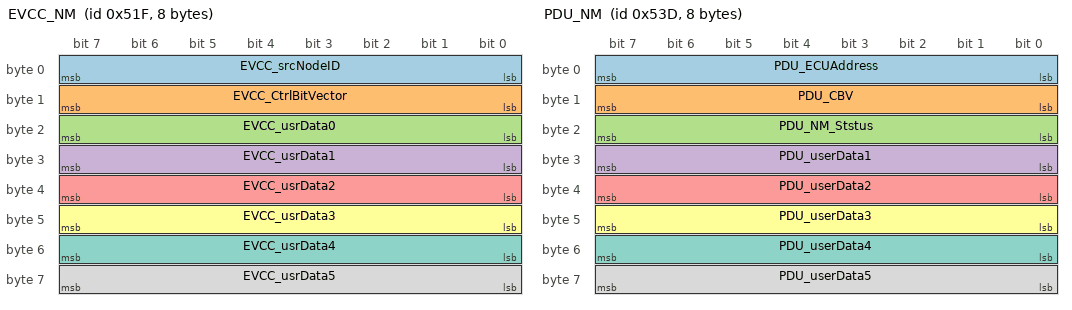
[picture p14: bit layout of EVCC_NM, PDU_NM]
BO_ 1311 EVCC_NM: 8 EVCC
 SG_ EVCC_srcNodeID : 7|8@0+ (1,0) [0|255] ""  CVC_P,PDU,BMS,FMCU
 SG_ EVCC_CtrlBitVector : 15|8@0+ (1,0) [0|255] ""  CVC_P,PDU,BMS,FMCU
 SG_ EVCC_usrData0 : 23|8@0+ (1,0) [0|255] ""  CVC_P,PDU,BMS,FMCU
 SG_ EVCC_usrData1 : 31|8@0+ (1,0) [0|255] ""  CVC_P,PDU,BMS,FMCU
 SG_ EVCC_usrData2 : 39|8@0+ (1,0) [0|255] ""  CVC_P,PDU,BMS,FMCU
 SG_ EVCC_usrData3 : 47|8@0+ (1,0) [0|255] ""  CVC_P,PDU,BMS,FMCU
 SG_ EVCC_usrData4 : 55|8@0+ (1,0) [0|255] ""  CVC_P,PDU,BMS,FMCU
 SG_ EVCC_usrData5 : 63|8@0+ (1,0) [0|255] ""  CVC_P,PDU,BMS,FMCU

BO_ 1341 PDU_NM: 8 PDU
 SG_ PDU_ECUAddress : 7|8@0+ (1,0) [0|255] ""  CVC_P,FMCU,BMS
 SG_ PDU_CBV : 15|8@0+ (1,0) [0|255] ""  CVC_P,FMCU,BMS
 SG_ PDU_NM_Ststus : 23|8@0+ (1,0) [0|255] ""  CVC_P,FMCU,BMS
 SG_ PDU_userData1 : 31|8@0+ (1,0) [0|255] ""  CVC_P,FMCU,BMS
 SG_ PDU_userData2 : 39|8@0+ (1,0) [0|255] ""  CVC_P,FMCU,BMS
 SG_ PDU_userData3 : 47|8@0+ (1,0) [0|255] ""  CVC_P,FMCU,BMS
 SG_ PDU_userData4 : 55|8@0+ (1,0) [0|255] ""  CVC_P,FMCU,BMS
 SG_ PDU_userData5 : 63|8@0+ (1,0) [0|255] ""  CVC_P,FMCU,BMS

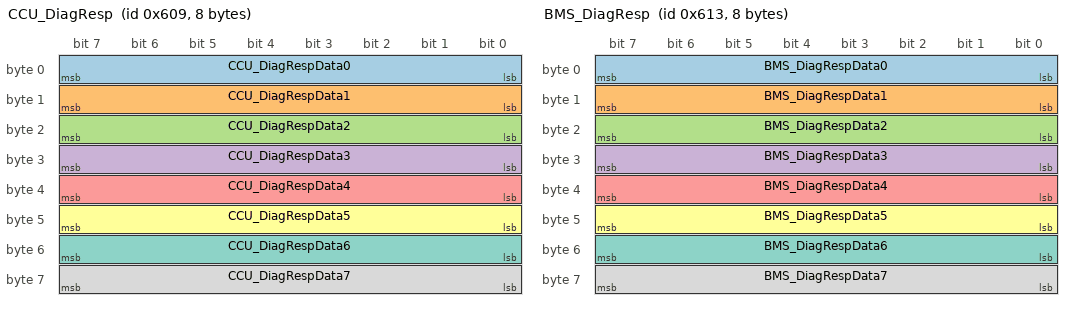
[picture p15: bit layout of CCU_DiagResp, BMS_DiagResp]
BO_ 1545 CCU_DiagResp: 8 CCU
 SG_ CCU_DiagRespData0 : 7|8@0+ (1,0) [0|255] ""  CVC_P
 SG_ CCU_DiagRespData1 : 15|8@0+ (1,0) [0|255] ""  CVC_P
 SG_ CCU_DiagRespData2 : 23|8@0+ (1,0) [0|255] ""  CVC_P
 SG_ CCU_DiagRespData3 : 31|8@0+ (1,0) [0|255] ""  CVC_P
 SG_ CCU_DiagRespData4 : 39|8@0+ (1,0) [0|255] ""  CVC_P
 SG_ CCU_DiagRespData5 : 47|8@0+ (1,0) [0|255] ""  CVC_P
 SG_ CCU_DiagRespData6 : 55|8@0+ (1,0) [0|255] ""  CVC_P
 SG_ CCU_DiagRespData7 : 63|8@0+ (1,0) [0|255] ""  CVC_P

BO_ 1555 BMS_DiagResp: 8 BMS
 SG_ BMS_DiagRespData0 : 7|8@0+ (1,0) [0|255] ""  CVC_P
 SG_ BMS_DiagRespData1 : 15|8@0+ (1,0) [0|255] ""  CVC_P
 SG_ BMS_DiagRespData2 : 23|8@0+ (1,0) [0|255] ""  CVC_P
 SG_ BMS_DiagRespData3 : 31|8@0+ (1,0) [0|255] ""  CVC_P
 SG_ BMS_DiagRespData4 : 39|8@0+ (1,0) [0|255] ""  CVC_P
 SG_ BMS_DiagRespData5 : 47|8@0+ (1,0) [0|255] ""  CVC_P
 SG_ BMS_DiagRespData6 : 55|8@0+ (1,0) [0|255] ""  CVC_P
 SG_ BMS_DiagRespData7 : 63|8@0+ (1,0) [0|255] "-"  CVC_P

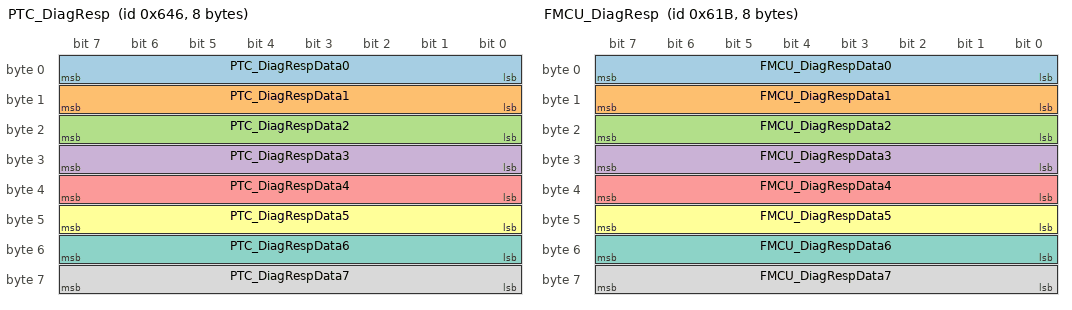
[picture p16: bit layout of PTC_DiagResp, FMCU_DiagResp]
BO_ 1606 PTC_DiagResp: 8 PTC
 SG_ PTC_DiagRespData0 : 7|8@0+ (1,0) [0|255] ""  CVC_P
 SG_ PTC_DiagRespData1 : 15|8@0+ (1,0) [0|255] ""  CVC_P
 SG_ PTC_DiagRespData2 : 23|8@0+ (1,0) [0|255] ""  CVC_P
 SG_ PTC_DiagRespData3 : 31|8@0+ (1,0) [0|255] ""  CVC_P
 SG_ PTC_DiagRespData4 : 39|8@0+ (1,0) [0|255] ""  CVC_P
 SG_ PTC_DiagRespData5 : 47|8@0+ (1,0) [0|255] ""  CVC_P
 SG_ PTC_DiagRespData6 : 55|8@0+ (1,0) [0|255] ""  CVC_P
 SG_ PTC_DiagRespData7 : 63|8@0+ (1,0) [0|255] "-"  CVC_P

BO_ 1563 FMCU_DiagResp: 8 FMCU
 SG_ FMCU_DiagRespData0 : 7|8@0+ (1,0) [0|255] ""  CVC_P
 SG_ FMCU_DiagRespData1 : 15|8@0+ (1,0) [0|255] ""  CVC_P
 SG_ FMCU_DiagRespData2 : 23|8@0+ (1,0) [0|255] ""  CVC_P
 SG_ FMCU_DiagRespData3 : 31|8@0+ (1,0) [0|255] ""  CVC_P
 SG_ FMCU_DiagRespData4 : 39|8@0+ (1,0) [0|255] ""  CVC_P
 SG_ FMCU_DiagRespData5 : 47|8@0+ (1,0) [0|255] ""  CVC_P
 SG_ FMCU_DiagRespData6 : 55|8@0+ (1,0) [0|255] ""  CVC_P
 SG_ FMCU_DiagRespData7 : 63|8@0+ (1,0) [0|255] ""  CVC_P

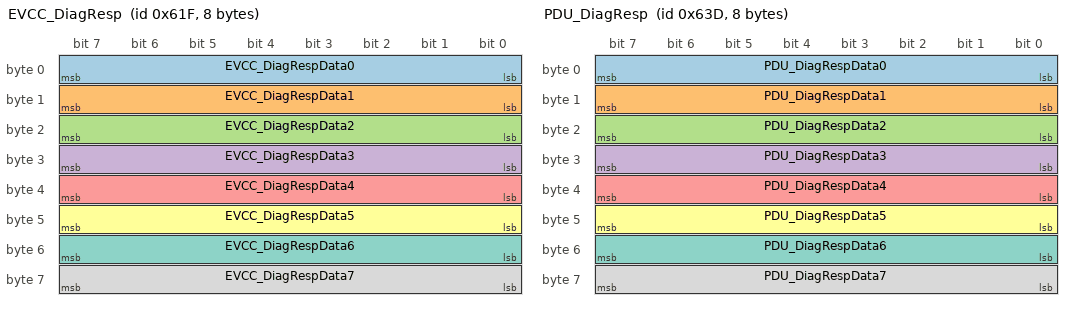
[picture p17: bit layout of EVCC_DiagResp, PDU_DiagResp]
BO_ 1567 EVCC_DiagResp: 8 EVCC
 SG_ EVCC_DiagRespData0 : 7|8@0+ (1,0) [0|255] ""  CVC_P
 SG_ EVCC_DiagRespData1 : 15|8@0+ (1,0) [0|255] ""  CVC_P
 SG_ EVCC_DiagRespData2 : 23|8@0+ (1,0) [0|255] ""  CVC_P
 SG_ EVCC_DiagRespData3 : 31|8@0+ (1,0) [0|255] ""  CVC_P
 SG_ EVCC_DiagRespData4 : 39|8@0+ (1,0) [0|255] ""  CVC_P
 SG_ EVCC_DiagRespData5 : 47|8@0+ (1,0) [0|255] ""  CVC_P
 SG_ EVCC_DiagRespData6 : 55|8@0+ (1,0) [0|255] ""  CVC_P
 SG_ EVCC_DiagRespData7 : 63|8@0+ (1,0) [0|255] ""  CVC_P

BO_ 1597 PDU_DiagResp: 8 PDU
 SG_ PDU_DiagRespData0 : 7|8@0+ (1,0) [0|255] ""  CVC_P
 SG_ PDU_DiagRespData1 : 15|8@0+ (1,0) [0|255] ""  CVC_P
 SG_ PDU_DiagRespData2 : 23|8@0+ (1,0) [0|255] ""  CVC_P
 SG_ PDU_DiagRespData3 : 31|8@0+ (1,0) [0|255] ""  CVC_P
 SG_ PDU_DiagRespData4 : 39|8@0+ (1,0) [0|255] ""  CVC_P
 SG_ PDU_DiagRespData5 : 47|8@0+ (1,0) [0|255] ""  CVC_P
 SG_ PDU_DiagRespData6 : 55|8@0+ (1,0) [0|255] ""  CVC_P
 SG_ PDU_DiagRespData7 : 63|8@0+ (1,0) [0|255] ""  CVC_P

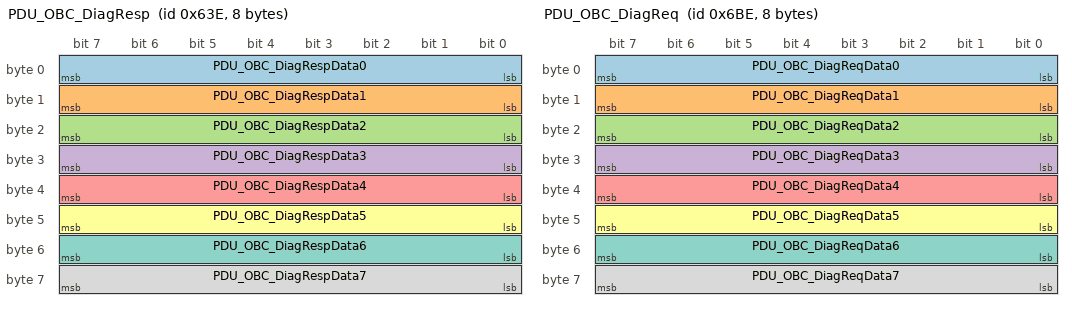
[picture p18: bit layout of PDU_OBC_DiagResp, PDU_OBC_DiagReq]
BO_ 1598 PDU_OBC_DiagResp: 8 PDU
 SG_ PDU_OBC_DiagRespData0 : 7|8@0+ (1,0) [0|255] ""  CVC_P
 SG_ PDU_OBC_DiagRespData1 : 15|8@0+ (1,0) [0|255] ""  CVC_P
 SG_ PDU_OBC_DiagRespData2 : 23|8@0+ (1,0) [0|255] ""  CVC_P
 SG_ PDU_OBC_DiagRespData3 : 31|8@0+ (1,0) [0|255] ""  CVC_P
 SG_ PDU_OBC_DiagRespData4 : 39|8@0+ (1,0) [0|255] ""  CVC_P
 SG_ PDU_OBC_DiagRespData5 : 47|8@0+ (1,0) [0|255] ""  CVC_P
 SG_ PDU_OBC_DiagRespData6 : 55|8@0+ (1,0) [0|255] ""  CVC_P
 SG_ PDU_OBC_DiagRespData7 : 63|8@0+ (1,0) [0|255] ""  CVC_P

BO_ 1726 PDU_OBC_DiagReq: 8 CVC_P
 SG_ PDU_OBC_DiagReqData0 : 7|8@0+ (1,0) [0|255] ""  PDU
 SG_ PDU_OBC_DiagReqData1 : 15|8@0+ (1,0) [0|255] ""  PDU
 SG_ PDU_OBC_DiagReqData2 : 23|8@0+ (1,0) [0|255] ""  PDU
 SG_ PDU_OBC_DiagReqData3 : 31|8@0+ (1,0) [0|255] ""  PDU
 SG_ PDU_OBC_DiagReqData4 : 39|8@0+ (1,0) [0|255] ""  PDU
 SG_ PDU_OBC_DiagReqData5 : 47|8@0+ (1,0) [0|255] ""  PDU
 SG_ PDU_OBC_DiagReqData6 : 55|8@0+ (1,0) [0|255] ""  PDU
 SG_ PDU_OBC_DiagReqData7 : 63|8@0+ (1,0) [0|255] ""  PDU

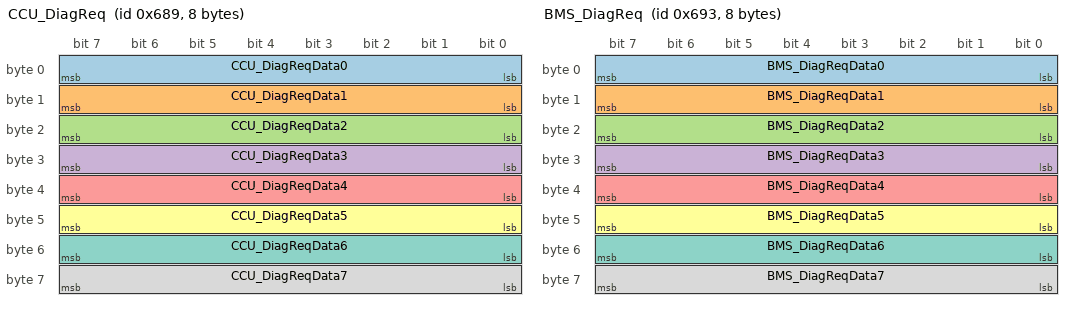
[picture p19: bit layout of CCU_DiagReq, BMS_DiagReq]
BO_ 1673 CCU_DiagReq: 8 CVC_P
 SG_ CCU_DiagReqData0 : 7|8@0+ (1,0) [0|255] ""  CCU
 SG_ CCU_DiagReqData1 : 15|8@0+ (1,0) [0|255] ""  CCU
 SG_ CCU_DiagReqData2 : 23|8@0+ (1,0) [0|255] ""  CCU
 SG_ CCU_DiagReqData3 : 31|8@0+ (1,0) [0|255] ""  CCU
 SG_ CCU_DiagReqData4 : 39|8@0+ (1,0) [0|255] ""  CCU
 SG_ CCU_DiagReqData5 : 47|8@0+ (1,0) [0|255] ""  CCU
 SG_ CCU_DiagReqData6 : 55|8@0+ (1,0) [0|255] ""  CCU
 SG_ CCU_DiagReqData7 : 63|8@0+ (1,0) [0|255] ""  CCU

BO_ 1683 BMS_DiagReq: 8 CVC_P
 SG_ BMS_DiagReqData0 : 7|8@0+ (1,0) [0|255] ""  BMS
 SG_ BMS_DiagReqData1 : 15|8@0+ (1,0) [0|255] ""  BMS
 SG_ BMS_DiagReqData2 : 23|8@0+ (1,0) [0|255] ""  BMS
 SG_ BMS_DiagReqData3 : 31|8@0+ (1,0) [0|255] ""  BMS
 SG_ BMS_DiagReqData4 : 39|8@0+ (1,0) [0|255] ""  BMS
 SG_ BMS_DiagReqData5 : 47|8@0+ (1,0) [0|255] ""  BMS
 SG_ BMS_DiagReqData6 : 55|8@0+ (1,0) [0|255] ""  BMS
 SG_ BMS_DiagReqData7 : 63|8@0+ (1,0) [0|255] ""  BMS

BO_ 1734 PTC_DiagReq: 8 CVC_P
 SG_ PTC_DiagReqData0 : 7|8@0+ (1,0) [0|255] ""  PTC
 SG_ PTC_DiagReqData1 : 15|8@0+ (1,0) [0|255] ""  PTC
 SG_ PTC_DiagReqData2 : 23|8@0+ (1,0) [0|255] ""  PTC
 SG_ PTC_DiagReqData3 : 31|8@0+ (1,0) [0|255] ""  PTC
 SG_ PTC_DiagReqData4 : 39|8@0+ (1,0) [0|255] ""  PTC
 SG_ PTC_DiagReqData5 : 47|8@0+ (1,0) [0|255] ""  PTC
 SG_ PTC_DiagReqData6 : 55|8@0+ (1,0) [0|255] ""  PTC
 SG_ PTC_DiagReqData7 : 63|8@0+ (1,0) [0|255] ""  PTC

BO_ 1691 FMCU_DiagReq: 8 CVC_P
 SG_ FMCU_DiagReqData0 : 7|8@0+ (1,0) [0|255] ""  FMCU
 SG_ FMCU_DiagReqData1 : 15|8@0+ (1,0) [0|255] ""  FMCU
 SG_ FMCU_DiagReqData2 : 23|8@0+ (1,0) [0|255] ""  FMCU
 SG_ FMCU_DiagReqData3 : 31|8@0+ (1,0) [0|255] ""  FMCU
 SG_ FMCU_DiagReqData4 : 39|8@0+ (1,0) [0|255] ""  FMCU
 SG_ FMCU_DiagReqData5 : 47|8@0+ (1,0) [0|255] ""  FMCU
 SG_ FMCU_DiagReqData6 : 55|8@0+ (1,0) [0|255] ""  FMCU
 SG_ FMCU_DiagReqData7 : 63|8@0+ (1,0) [0|255] ""  FMCU

BO_ 1695 EVCC_DiagReq: 8 CVC_P
 SG_ EVCC_DiagReqData0 : 7|8@0+ (1,0) [0|255] ""  EVCC
 SG_ EVCC_DiagReqData1 : 15|8@0+ (1,0) [0|255] ""  EVCC
 SG_ EVCC_DiagReqData2 : 23|8@0+ (1,0) [0|255] ""  EVCC
 SG_ EVCC_DiagReqData3 : 31|8@0+ (1,0) [0|255] ""  EVCC
 SG_ EVCC_DiagReqData4 : 39|8@0+ (1,0) [0|255] ""  EVCC
 SG_ EVCC_DiagReqData5 : 47|8@0+ (1,0) [0|255] ""  EVCC
 SG_ EVCC_DiagReqData6 : 55|8@0+ (1,0) [0|255] ""  EVCC
 SG_ EVCC_DiagReqData7 : 63|8@0+ (1,0) [0|255] ""  EVCC

BO_ 1725 PDU_DiagReq: 8 CVC_P
 SG_ PDU_DiagReqData0 : 7|8@0+ (1,0) [0|255] ""  PDU
 SG_ PDU_DiagReqData1 : 15|8@0+ (1,0) [0|255] ""  PDU
 SG_ PDU_DiagReqData2 : 23|8@0+ (1,0) [0|255] ""  PDU
 SG_ PDU_DiagReqData3 : 31|8@0+ (1,0) [0|255] ""  PDU
 SG_ PDU_DiagReqData4 : 39|8@0+ (1,0) [0|255] ""  PDU
 SG_ PDU_DiagReqData5 : 47|8@0+ (1,0) [0|255] ""  PDU
 SG_ PDU_DiagReqData6 : 55|8@0+ (1,0) [0|255] ""  PDU
 SG_ PDU_DiagReqData7 : 63|8@0+ (1,0) [0|255] ""  PDU

BO_ 1791 DIAG_Req_All_Ecu: 8 CVC_P
 SG_ DiagReqAllEcuData0 : 7|8@0+ (1,0) [0|255] ""  PDU,EVCC,BMS,FMCU,CCU,PTC
 SG_ DiagReqAllEcuData1 : 15|8@0+ (1,0) [0|255] ""  PDU,EVCC,BMS,FMCU,CCU,PTC
 SG_ DiagReqAllEcuData2 : 23|8@0+ (1,0) [0|255] ""  PDU,EVCC,BMS,FMCU,CCU,PTC
 SG_ DiagReqAllEcuData3 : 31|8@0+ (1,0) [0|255] ""  PDU,EVCC,BMS,FMCU,CCU,PTC
 SG_ DiagReqAllEcuData4 : 39|8@0+ (1,0) [0|255] ""  PDU,EVCC,BMS,FMCU,CCU,PTC
 SG_ DiagReqAllEcuData5 : 47|8@0+ (1,0) [0|255] ""  PDU,EVCC,BMS,FMCU,CCU,PTC
 SG_ DiagReqAllEcuData6 : 55|8@0+ (1,0) [0|255] ""  PDU,EVCC,BMS,FMCU,CCU,PTC
 SG_ DiagReqAllEcuData7 : 63|8@0+ (1,0) [0|255] ""  PDU,EVCC,BMS,FMCU,CCU,PTC

BO_ 1939 BMS_XCPTx: 8 BMS
 SG_ BMS_XCPTxData : 7|64@0+ (1,0) [0|0] ""  CVC_P

BO_ 1986 BMS_XCPRx: 8 CVC_P
 SG_ BMS_XCPRxData : 7|64@0+ (1,0) [0|0] ""  BMS

CM_ SG_ 820 BMS_ErrorCategory_CAT0 "Escalation level of an error";
CM_ SG_ 820 BMS_ErrorCategory_CAT1 "Escalation level of an error";
CM_ SG_ 820 BMS_ErrorCategory_CAT2 "Escalation level of an error";
CM_ SG_ 820 BMS_ErrorCategory_CAT3 "Escalation level of an error";
CM_ SG_ 820 BMS_ErrorCategory_CAT4 "Escalation level of an error";
CM_ SG_ 820 BMS_ErrorCategory_CAT5 "Escalation level of an error";
CM_ SG_ 820 BMS_ErrorCategory_CAT6 "Escalation level of an error";
CM_ SG_ 820 BMS_ErrorCategory_CAT7 "Escalation level of an error";
CM_ SG_ 820 BMS_ErrorCategory_CAT8 "Escalation level of an error";
CM_ SG_ 821 CCU_PTC_HeatPwrDemand "Requesting the heating power required for CCU";
CM_ SG_ 821 CCU_FrontBlowerVFb "Voltage feedback of front blower";
CM_ SG_ 821 CCU_BlowmotorPos "Voltage feedback of blow mode motor position signal";
CM_ SG_ 843 CRC_EVSE_Info_1 "Checksum";
CM_ SG_ 843 ALIV_EVSE_Info_1 "Alive counter";
CM_ SG_ 843 EVSE_DC_Stt "Debug Indicate DC-EVSE internal state, element DC_EVSEStatusCode as definded in annex C.6, ISO 15118- 2:2016.";
CM_ SG_ 843 EVSE_CtrlPilot_PWM_value "(Debug) Indicate the PWM value of Control Pilot.";
CM_ SG_ 843 EVSE_CtrlPilot_STS "(Debug) Indicate Control Pilot state, as definded in Table A.4, IEC 61851-1:2017";
CM_ SG_ 843 EVSE_IsolationLvl "(Debug) Indicate EVSE isolation level, element EVSEIsolationStatus as definded in annex C.6, ISO 15118- 2:2016.";
CM_ SG_ 843 EVSE_VehChgComm_STAT "(Debug) Indicate vehicle charging communication state.";
CM_ SG_ 843 EVSE_ResponseCode "(Debug) Indicate EVSE response code, element responseCode as definded in annex C.6, ISO 15118-2:2016.";
CM_ SG_ 843 EVSE_AC_MaxLineCur "The information sent from EVSE to indicate the maximum line current per phase the EV can draw. Element EVSEMaxCurrent as definded in ISO 15118-2:2016.";
CM_ SG_ 845 CRC_EVCC_Insulation "Checksum";
CM_ SG_ 845 ALIVE_EVCC_Insulation "Alive counter";
CM_ SG_ 845 EVCC_Req_InsulationMon "Indicate the request on/off insulation monitor for DC charging from EVCC.";
CM_ SG_ 845 EVCC_PnC_Contract_STS "Indicate the status of the PnC Contract Certificate";
CM_ SG_ 845 EVCC_FcContactor_Req "Indicate the requested state of FC contactors.";
CM_ SG_ 845 EVCC_FcContactor_Sts "Indicate the status of FC contactors";
CM_ SG_ 847 CRC_EVSE_Info_2 "Checksum";
CM_ SG_ 847 ALIV_EVSE_Info_2 "Alive counter";
CM_ SG_ 847 EVSE_DC_MaxChgCur "(Debug) The information sent from EVSE to indicate the maximum DC current the EVSE can deliver. Element EVSEMaximumCurrentLimit as definded in ISO 15118-2:2016.";
CM_ SG_ 847 EVSE_DC_MaxChgPwr "The information was sent from EVSE to indicate the maximum DC power the EVSE can deliver. Element EVSEMaximumPowerLimit as definded in ISO 15118-2:2016.";
CM_ SG_ 847 EVSE_DC_ActCurOut "(Debug) The information was sent from EVSE to indicate the present output current of the EVSE. Element EVSEPresentCurrent as definded in ISO 15118-2:2016.";
CM_ SG_ 850 EVCC_MotorWaterPump_PWM_fb "Feedback of Motor water pump PWM";
CM_ SG_ 850 EVCC_SOV2_ControlStatus "Status ON/OFF SOV 2";
CM_ SG_ 850 EVCC_BatteryWaterPump_PWM_fb "Feedback of Battery water pump PWM";
CM_ SG_ 850 EVCC_SOV1_ControlStatus "Status ON/OFF SOV 1";
CM_ SG_ 850 EVCC_MotorWaterPump_Status "Status of Motor water pump";
CM_ SG_ 850 EVCC_BatteryWaterPump_Status "Status of Battery water pump";
CM_ SG_ 850 EVCC_ACPressure "EVCC_ACPressure EVCC get pressure signal from Temp and pressure sensor";
CM_ SG_ 850 EVCC_PTC_OnOff_Status "Operation status of heater";
CM_ SG_ 851 EVCC_EAC_OnOff_Status "Operation status of EAC";
CM_ SG_ 851 EVCC_DualPressureSwitch_Status "Status of dual pressure switch";
CM_ SG_ 851 EVCC_MainRelay_OnOff_Status "Operation status of main relay";
CM_ SG_ 851 EVCC_ElectricFan_OnOff_Sts "Status ON/OFF electric fan lo speed";
CM_ SG_ 851 EVCC_CL15_Status "Status of Ignition on switch";
CM_ SG_ 851 EVCC_PGearPressSignal1_Status "Status of P Gear Press Signal 1";
CM_ SG_ 851 EVCC_PGearStsLight_OnOff_Sts "Status ON/OFF P Gear Status Light";
CM_ SG_ 851 EVCC_PGearPressSignal2_Status "Status of P Gear Press Signal 2";
CM_ SG_ 851 EVCC_ExpValve_OnOff_Status "Status ON/OFF of Expansion Valve";
CM_ SG_ 851 EVCC_EACPTCHVIL_Status "HVIL status of EAC and PTC";
CM_ SG_ 851 EVCC_ElectricFan_PWM_fb "Feedback of electric fan speed PWM";
CM_ SG_ 851 EVCC_ACTemperature "EVCC get temperature signal from Temp and pressure sensor";
CM_ SG_ 851 EVCC_Motor_TempSensor "EVCC get temperature signal from Motor colling temp sensor";
CM_ SG_ 852 CVC_BatteryWaterPump_OnOff_Req "Request ON/OFF Battery water pump";
CM_ SG_ 852 CVC_EAC_OnOff_Req "Enable Operation of HV-EAC";
CM_ SG_ 852 CVC_PGearStatusLight_OnOff_Req "Request ON/OFF P Gear Status Light";
CM_ SG_ 852 CVC_MotorWaterPump_PWM_Req "Request PWM value to control Motor water pump";
CM_ SG_ 852 CVC_BatteryWaterPump_PWM_Req "Request PWM value to control Baterry water pump";
CM_ SG_ 852 CVC_PTC_OnOff_Req "Enable Operation of HV-PTC";
CM_ SG_ 852 CVC_ExpValve_OnOff_Req "Request ON/OFF Expansion Valve";
CM_ SG_ 852 CVC_SOV2_ControlReq "Request ON/OFF SOV 2";
CM_ SG_ 852 CVC_DriveCoolWaterFlowRate "Actual drive cool water flow rate";
CM_ SG_ 852 CVC_EACAllowedPower "EAC Allowed Power";
CM_ SG_ 852 CVC_ElectricFan_PWM_Req "Request PWM to electric fan speed";
CM_ SG_ 853 CVC_SOV1_ControlReq "Request ON/OFF SOV 1";
CM_ SG_ 853 CVC_MotorWaterPump_OnOff_Req "Request ON/OFF Motor water pump";
CM_ SG_ 853 CVC_MainRelay_OnOff_Req "Request ON/OFF main relay";
CM_ SG_ 853 CVC_ElectricFan_Enable "Request ON/OFF electric fan lo speed";
CM_ SG_ 855 CRC_CVC_ChgSetting_Info "Checksum";
CM_ SG_ 855 ALIV_CVC_ChgSetting_Info "Alive counter";
CM_ SG_ 855 CVC_Ack_LimitSetting_SOC "Indicate the acknowledge setting value for the limit of the HV state-of-charge.";
CM_ SG_ 855 CVC_ACInputChgCurLim "Indicate the setting value for the limit of the AC input charge current.";
CM_ SG_ 858 CRC_CVC_CP_Req "Checksum";
CM_ SG_ 858 ALIV_CVC_CP_Req "Alive counter";
CM_ SG_ 858 CVC_LockCP_Req "Indicate the request for EVCC to lock/unlock the charge port.";
CM_ SG_ 859 CRC_EVCC_ACCharging_Req "Checksum";
CM_ SG_ 859 ALIV_EVCC_ACCharging_Req "Alive counter";
CM_ SG_ 859 OBC_Req "Indicate the request of the OBC state";
CM_ SG_ 859 OBC_OutputVol_Req "Indicate the request for the OBC output voltage.";
CM_ SG_ 859 OBC_OutputCur_Req "Indicate the request for the OBC output current";
CM_ SG_ 859 OBC_ACInputChgCurLim "Indicate the request for the limit of the OBC input current.";
CM_ SG_ 862 CRC_CVC_Vehicle_info "Checksum";
CM_ SG_ 862 ALIV_CVC_Vehicle_info "Alive counter";
CM_ SG_ 862 CVC_VehSpd_ScreenDisplay "Indicate the display speed on HMI screen calculated according to Vehicle actual speed.";
CM_ SG_ 862 CVC_VehChgAllow "Indicate the request to allow the vehicle to start charging";
CM_ SG_ 862 Re_InitCharging_Req "Request re-initiate charging";
CM_ SG_ 872 FMCU_MCUinternalFault "MCU  internal level 3 fault indicate";
CM_ SG_ 872 FMCU_PhaseOverCurrentSWFault "Front Phase Current Overcurrent software fault";
CM_ SG_ 872 FMCU_MCUOverTempFault "FMCU over temperture fault";
CM_ SG_ 872 FMCU_MCUOverTempAlarm "FMCU over temperture alarm";
CM_ SG_ 872 FMCU_MotTempSenFault "Front Motor temperature sensor fault";
CM_ SG_ 872 FMCU_MotTempSenWFault "Front Motor temperature sensorW fault";
CM_ SG_ 872 FMCU_MotTempSenVFault "Front Motor temperature sensorV fault";
CM_ SG_ 872 FMCU_MotTempSenUFault "Front Motor temperature sensorU fault";
CM_ SG_ 872 FMCU_MotOverTempFault "Front Motor over temperture fault";
CM_ SG_ 872 FMCU_MotOverTempAlarm "Front Motor over temperture alarm";
CM_ SG_ 872 FMCU_MCUHVUnderVoltageFault "FMCU high voltage under voltage fault";
CM_ SG_ 872 FMCU_MCUHVUnderVoltageAlarm "FMCU high voltage under voltage alarm";
CM_ SG_ 872 FMCU_MCUHVOverVoltageFault "FMCU high voltage over voltage fault";
CM_ SG_ 872 FMCU_MCUHVOverVoltageAlarm "FMCU high voltage over voltage alarm";
CM_ SG_ 872 FMCU_MCUCurrentSenWFault "FMCU current sensorW fault";
CM_ SG_ 872 FMCU_MCUCurrentSenVFault "FMCU current sensorV fault";
CM_ SG_ 872 FMCU_MCUCurrentSenUFault "FMCU current sensorU fault";
CM_ SG_ 872 FMCU_PhaseOverCurrentHWFault "Phase Current Overcurrent hardware fault";
CM_ SG_ 872 FMCU_MotOverFault "Motor overspeed fault fault";
CM_ SG_ 872 FMCU_MotOverAlarm "Motor overspeed fault alarm";
CM_ SG_ 872 FMCU_12VUnderVoltageAlarm "12V Power under voltage alarm";
CM_ SG_ 872 FMCU_12VOverVoltageAlarm "12V Power over voltage alarm";
CM_ SG_ 872 FMCU_MCUHVSensorFault "FMCU high voltage sensor fault";
CM_ SG_ 872 FMCU_MCUDisChgFault "FMCU Active discharge fault";
CM_ SG_ 872 FMCU_MotBlockedFault "Motor blocked fault";
CM_ SG_ 872 FMCU_MotRotSenFault "Motor resolver fault";
CM_ SG_ 872 FMCU_BMSLostFault "BMS lost communication fault";
CM_ SG_ 872 FMCU_CVCLostFault "CVC lost communication fault";
CM_ SG_ 872 FMCU_CANBusoffFault "CAN busoff fault";
CM_ SG_ 872 FMCU_IGBTFault "IGBT fault";
CM_ SG_ 872 FMCU_MCUCurrentSenWZeroFault "FMCU current sensorW Zero fault";
CM_ SG_ 872 FMCU_MCUCurrentSenVZeroFault "FMCU current sensorV Zero fault";
CM_ SG_ 872 FMCU_MCUCurrentSenUZeroFault "FMCU current sensorU Zero fault";
CM_ SG_ 872 FMCU_MCUTempSenWFault "FMCU temperature sensorW fault";
CM_ SG_ 872 FMCU_MCUTempSenVFault "FMCU temperature sensorV fault";
CM_ SG_ 872 FMCU_MCUTempSenUFault "FMCU temperature sensorU fault";
CM_ SG_ 872 FMCU_InitMode "Initial mode";
CM_ SG_ 872 FMCU_MCUFaultCode "FMCU Fault Code";
CM_ SG_ 873 FMCU_MCUTemp "FMCU internal temperature";
CM_ SG_ 873 FMCU_MotorTemp "Front Motor temperature";
CM_ SG_ 873 FMCU_WaterPumpLevlReq "FMCU waterpump request";
CM_ SG_ 873 FMCU_StsActiveDischg "FMCU Active discharge state";
CM_ SG_ 873 FMCU_TBOX_ModeMotorDrv "Front Motor driving mode";
CM_ SG_ 873 FMCU_MotorTempU "Front Motor U temperature";
CM_ SG_ 873 FMCU_MotorTempV "Front Motor V temperature";
CM_ SG_ 873 FMCU_MotorTempW "Front Motor W temperature";
CM_ SG_ 884 PTC_PCBT "PTC_PCB temperature";
CM_ SG_ 884 PTC_Crt "PTC Current";
CM_ SG_ 884 PTC_CrtSts "PTC status";
CM_ SG_ 884 PTC_HVIntlkFlt "PTC HVIL";
CM_ SG_ 884 PTC_ComLost_ECC "PTC lost ECC communication_U198187_E00";
CM_ SG_ 884 PTC_OverCrtFlt "PTC Over current _P164019_E00";
CM_ SG_ 884 PTC_HVUnderVoltFlt "PTC input HV under Voltage_P165716_E00";
CM_ SG_ 884 PTC_HVOverVoltFlt "PTC input HV Over Voltage_P165717_E00";
CM_ SG_ 884 PTC_ChkBattOverVoltFlt "PTC input LV Over Voltage_U190017_E00";
CM_ SG_ 884 PTC_ChkBattUnderVoltFlt "PTC input LV Under Voltage_U190016_E00";
CM_ SG_ 884 PTC_InlTSnsrFlt "PTC water inlet temp sensor fault_P16491C_E00";
CM_ SG_ 884 PTC_OutlTSnsrFlt "PTC water outlet temp sensor fault_P164A1C_E00";
CM_ SG_ 884 PTC_InlOverTFlt "PTC input Over temperature_P164998_E00";
CM_ SG_ 884 PTC_OutlOverTFlt "PTC Output Over temperature_P164A98_E00";
CM_ SG_ 884 PTC_PCBOverTFlt "PTC PCB Over temperature_P164898_E00";
CM_ SG_ 884 PTC_PCBTSnsrFlt "PTC PCB temp sensor fault_P16481C_E00";
CM_ SG_ 884 PTC_PwrOutpFlt "PTC Output Power fault_P164C00_E00";
CM_ SG_ 885 Checksum_0x375 "Checksum";
CM_ SG_ 885 Rolling_Counter_0x375 "Rolling Counter";
CM_ SG_ 885 BMS_PreChgRelay_ERR "Precahrge relay is not working properly";
CM_ SG_ 885 BMS_TotalNegRelay_ERR "Main Negative Relay Error";
CM_ SG_ 885 BMS_MainPosRelay_ERR "Main Position Relay Error";
CM_ SG_ 885 BMS_MainPosRelay_STS "Main Positive Relay Status";
CM_ SG_ 885 BMS_PreChgRelay_STS "PreCharge Relay Status";
CM_ SG_ 885 BMS_TotalNegRelay_STS "Main Negative Relay Status";
CM_ SG_ 889 PTC_BusLineVolt "Bus Line Voltage";
CM_ SG_ 889 PTC_CrtPwr "PTC current power";
CM_ SG_ 889 PTC_CrtT "PTC current";
CM_ SG_ 889 PTC_IninSts "PTC initial status";
CM_ SG_ 889 PTC_HVPwrSplySts "PTC HV status";
CM_ SG_ 889 PTC_ActGear "PTC gear Status";
CM_ SG_ 889 PTC_Mod "PTC mode";
CM_ SG_ 892 CRC_Charging_Info "Checksum";
CM_ SG_ 892 ALIV_Charging_Info "Alive counter";
CM_ SG_ 892 EVCC_ChgGun_Sts "Indicate the status of the charge gun: whether it is connected, removed, or if there is an error.";
CM_ SG_ 892 EVCC_ChgFlap_Sts "Indicate the status of the charge flap: whether it is opened, closed and locked or released.";
CM_ SG_ 892 EVCC_ChgType "Indicate the charging type for the charging session. The charging type is detected via the PWM value of the CP pin and the message pair ServiceDiscovery during PLC communication";
CM_ SG_ 892 EVCC_VehChg_Sts "Indicate the charging status.";
CM_ SG_ 892 EVCC_ChgAuthen_Sts "Indicate the authentication status of charging session, whether the vehicle and the EVSE is compatible or not.";
CM_ SG_ 892 EVCC_PaymentType "Description Indicate the payment type for the charging session.";
CM_ SG_ 892 EVCC_VehChgCompError_Sts "Indicate the error status of the charging components from the vehicle.";
CM_ SG_ 892 EVCC_ProximityPilot_Voltage "Indicate the measure voltage of Proximity pilot (PP) pin";
CM_ SG_ 892 EVCC_SLAC_Attenuation "EVCC sends charging SLAC attenuation amplitude";
CM_ SG_ 893 CRC_CVC_Battery_Info "Checksum";
CM_ SG_ 893 ALIV_CVC_Battery_Info "Alive counter";
CM_ SG_ 893 CVC_HV_DispSOC "Indicate the state-of-charge of the HV battery rounded by CVC to display to user";
CM_ SG_ 893 CVC_HV_Cur_LoadComp "Indicate the necessary current estimated by CVC to compensate HV load during charging.";
CM_ SG_ 896 VIN_Byte1 "This signal contains the seventh last digit of the chassis number. (The individual digits are encoded in ASCII characters.)
Bit 0: LSB, Bit 7: MSB";
CM_ SG_ 896 VIN_Byte2 "This signal contains the sixth last digit of the chassis number. (The individual digits are encoded in ASCII characters.)
Bit 0: LSB, Bit 7: MSB";
CM_ SG_ 896 VIN_Byte3 "This signal contains the fifth last digit of the chassis number. (The individual digits are encoded in ASCII characters.)
Bit 0: LSB, Bit 7: MSB";
CM_ SG_ 896 VIN_Byte4 "This signal contains the fourth last digit of the chassis number. (The individual digits are encoded in ASCII characters.)
Bit 0: LSB, Bit 7: MSB";
CM_ SG_ 896 VIN_Byte5 "This signal contains the third last digit of the chassis number. (The individual digits are encoded in ASCII characters.)
Bit 0: LSB, Bit 7: MSB";
CM_ SG_ 896 VIN_Byte6 "This signal contains the penultimate digit of the chassis number. (The individual digits are encoded in ASCII characters.)
Bit 0: LSB, Bit 7: MSB";
CM_ SG_ 896 VIN_Byte7 "This signal contains the last digit of the chassis number. (The individual digits are encoded in ASCII characters.)
Bit 0: LSB, Bit 7: MSB";
CM_ SG_ 919 OBC_OBCTemp "Temperature1 of OBC";
CM_ SG_ 919 OBC_InletTemp "Temperature of OBC Cooling Inlet";
CM_ SG_ 919 OBC_InletTempSenFault "OBC Inlet Temperature Sensar Fault";
CM_ SG_ 920 OBC_OutputUnderVoltage "Output voltage too low alarm of OBC";
CM_ SG_ 920 OBC_OutputOverVoltage "Output voltage too high alarm of OBC";
CM_ SG_ 920 OBC_InputUnderVoltage "Input voltage too low alarm of OBC";
CM_ SG_ 920 OBC_InputOverVoltage "Input voltage too high alarm of OBC";
CM_ SG_ 920 OBC_12VFault "12V supply Fault";
CM_ SG_ 920 OBC_ChgConnectionFault "Charging Connection Failure";
CM_ SG_ 920 OBC_ChgerTempCircuitFault "Charger Temp Detction Circuit Fault";
CM_ SG_ 920 OBC_InputOverCurrent "Input current too high alarm of OBC";
CM_ SG_ 920 OBC_ChgerDeratingOverTemp "Charger Over Temp Derating Fault";
CM_ SG_ 920 OBC_ChgerShtdownOverTemp "Charger Over Temp Shutdown Fault";
CM_ SG_ 920 OBC_CAN_CheckSumErrorBMS "BMS  Frame CheckSum Error";
CM_ SG_ 920 OBC_CAN_LostBMSFrame "BMS Frame Lost";
CM_ SG_ 920 OBC_CAN_MissBMS "BMS ECU Missing Fault";
CM_ SG_ 920 OBC_CAN_InternalComFault "Inlet Communication Error";
CM_ SG_ 920 OBC_CAN_MissCVC "CVC ECU Missing Fault";
CM_ SG_ 920 OBC_CAN_BusOff "OBC CAN BusOff";
CM_ SG_ 1009 CheckSum_0x3F1 "CheckSum_0x3F1";
CM_ SG_ 1009 RollingCounter_0x3F1 "RollingCounter_0x3F1";
CM_ SG_ 1009 IPC_IPCTotalOdometer "the total odometer displayed in IPC";
CM_ SG_ 1009 IPC_IPCTotalOdometerV "Odometer infomation validity";
CM_ SG_ 1009 IPC_Remain_Maintenance "Remaining maintenance mileage";
CM_ SG_ 1098 PTC_SwVersS "PTC software numble second value";
CM_ SG_ 1098 PTC_PartVers "PTC part number";
CM_ SG_ 1098 PTC_HwVers "PTC Hardware number";
CM_ SG_ 1098 PTC_SwVersM "PTC Software numble First value";
CM_ SG_ 1110 Checksum_0x456 "Checksum";
CM_ SG_ 1110 Rolling_Counter_0x456 "Rolling Counter";
CM_ SG_ 1110 BMS_CellLowVol_ERR "under voltage of the cell is detected";
CM_ SG_ 1110 BMS_HVIL_Err "High Voltage Interlock loop circuit error";
CM_ SG_ 1110 BMS_PackInsu_ERR "Insulation check lines have problems, short to ground or short to bat";
CM_ SG_ 1110 BMS_CellVoltDiff_ERR "max and min cell voltage difference is too large";
CM_ SG_ 1110 BMS_ProbeTempDiff_ERR "The difference in temperture between max and min is beyound the permissable limit";
CM_ SG_ 1110 BMS_PackHighVol_ERR "Pack voltage is higher than the permittable values";
CM_ SG_ 1110 BMS_PackLowVol_ERR "Pack voltage is lower than the permittable values";
CM_ SG_ 1110 BMS_CellHighVol_ERR "Over voltage of the cell is detected";
CM_ SG_ 1110 BMS_ProbeHighTemp_ERR "Over temperature of the cell is detected";
CM_ SG_ 1110 BMS_FuseStatus_ERR "Fuse and Pyro fuse blowup status";
CM_ SG_ 1110 BMS_PackOverCurr_ERR "When the over current is detected during charging and discharging for the given period of time, then the BMS_Packovercurr_err will set";
CM_ SG_ 1110 BMS_ProbeLowTemp_ERR "Under Temperature of the cell is detected";
CM_ SG_ 1118 EAC_CompBoardTempV "Compressor Board Temperature Validity";
CM_ SG_ 1118 EAC_CompHVInputV "Compressor High Voltage Input Validity";
CM_ SG_ 1118 EAC_CompIGBTTempV "Compressor IGBT Temperature Validity";
CM_ SG_ 1118 EAC_CompBoardTemp "Compressor Board Temperature";
CM_ SG_ 1118 EAC_CompHVInput "Compressor High Voltage Input";
CM_ SG_ 1118 EAC_CompIGBTTemp "Compressor IGBT Temperature";
CM_ SG_ 1118 EAC_CompLVInput "Compressor Low Voltage Input";
CM_ SG_ 1119 CompSpdReqV "Compressor Speed Request valid";
CM_ SG_ 1119 CompEnable "compressor enable";
CM_ SG_ 1119 CompSpdReq "Compressor Speed Request";
CM_ SG_ 1119 CVC_FaultCode "CVC Faultcode";
CM_ SG_ 1119 CVC_MotorWaterTemp "Motor loop inlet water temperature";
CM_ SG_ 1119 CVC_MotLoopPumpDuty "motor loop pump pwm duty";
CM_ SG_ 1119 CVC_BattLoopPumpDuty "battery loop pump pwm duty";
CM_ SG_ 1117 EAC_HW_MasterVersion "Hardware Master Version";
CM_ SG_ 1117 EAC_SW_bottomVersion "Bottom level software version";
CM_ SG_ 1117 EAC_SW_ApplicationVersion "Application layer software version";
CM_ SG_ 1117 EAC_SW_year "Software completion date(year)";
CM_ SG_ 1117 EAC_SW_month "Software completion date(month)";
CM_ SG_ 1117 EAC_SW_day "Software completion date(day)";
CM_ SG_ 1120 EAC_CompFltStat "Compressor Fault Status";
CM_ SG_ 1120 EAC_CompStat "Compressor status";
CM_ SG_ 1120 EAC_CompSpdV "Compressor Actual Speed Validity";
CM_ SG_ 1120 EAC_CompElecPwrV "Compressor Electrical Power Validity";
CM_ SG_ 1120 EAC_CompElecCurrV "Compressor Electrical Current Validity";
CM_ SG_ 1120 EAC_CompElecPwr "Compressor Electrical Power";
CM_ SG_ 1120 EAC_CompElecCurr "Compressor Electrical Current";
CM_ SG_ 1120 EAC_CompSpd "Compressor Actual Speed";
CM_ SG_ 1120 EAC_ErrorCode "Compressor_ErrorCode";
CM_ SG_ 1146 BMS_PackSOCDiff "BMS diagnostic signal for pack SoC difference";
CM_ SG_ 1171 CHSKM_BMS_WarnMsg "Checksum";
CM_ SG_ 1171 ALV_BMS_WarnMsg "Alive Counter";
CM_ SG_ 1171 BMS_PackTempSts "Pack temperature warning";
CM_ SG_ 1171 BMS_ThermalRunaway "Thermal runaway warning";
CM_ SG_ 1171 BMS_BatteryReplacement "Separate signal to indicate the battery replacement information(Battery replacement IVI)";
CM_ SG_ 1171 BMS_Warning_PowerDegrade "Pack Power Degrade: Battery is cold & limited capacity, please charge";
CM_ SG_ 1171 BMS_Warning_DeltaSoC "EV Battery Delta SOC is high, range reduction in vehicle will be absorbed";
CM_ SG_ 1171 BMS_Warning_HVILSts "HVIL warning signal";
CM_ SG_ 1171 BMS_Warning_Isolation "Coolant Leakage warning";
CM_ SG_ 1171 BMS_Warning_CoolantLeakage "Coolant Leakage warning";
CM_ SG_ 1171 BMS_MalfunctionSts "Malfunction status of battery for IVI display";
CM_ SG_ 1171 BMS_LowBattery "Low Battery Warning";
CM_ SG_ 1171 BMS_Warning_DeltaTemperature "Delta temperature warning signal";
CM_ SG_ 1171 BMS_Warning_BDUTemperatureSts "BDU temperature warning signal";
CM_ SG_ 1171 BMS_Warning_Contactor_Aging "Contactor Aging Warning";
CM_ SG_ 1171 BMS_Reserved_signal4 "Warning Message Flag, Component owner, Supplier align and define for this signal";
CM_ SG_ 1171 BMS_Reserved_signal5 "Warning Message Flag, Component owner, Supplier align and define for this signal";
CM_ SG_ 1184 BMS_CellT1 "BMS_CellT1";
CM_ SG_ 1184 BMS_CellT2 "BMS_CellT2";
CM_ SG_ 1184 BMS_CellT3 "BMS_CellT3";
CM_ SG_ 1184 BMS_CellT4 "BMS_CellT4";
CM_ SG_ 1184 BMS_CellT5 "BMS_CellT5";
CM_ SG_ 1184 BMS_CellT6 "BMS_CellT6";
CM_ SG_ 1184 BMS_CellT7 "BMS_CellT7";
CM_ SG_ 1184 BMS_CellT8 "BMS_CellT8";
CM_ SG_ 1188 BMS_CellT9 "BMS_CellT9";
CM_ SG_ 1188 BMS_CellT10 "BMS_CellT10";
CM_ SG_ 1188 BMS_CellT11 "BMS_CellT11";
CM_ SG_ 1188 BMS_CellT12 "BMS_CellT12";
CM_ SG_ 1188 BMS_CellT13 "BMS_CellT13";
CM_ SG_ 1188 BMS_CellT14 "BMS_CellT14";
CM_ SG_ 1188 BMS_CellT15 "BMS_CellT15";
CM_ SG_ 1188 BMS_CellT16 "BMS_CellT16";
CM_ SG_ 1189 BMS_CellT17 "BMS_CellT17";
CM_ SG_ 1189 BMS_CellT18 "BMS_CellT18";
CM_ SG_ 1189 BMS_CellT19 "BMS_CellT19";
CM_ SG_ 1189 BMS_CellT20 "BMS_CellT20";
CM_ SG_ 1189 BMS_CellT21 "BMS_CellT21";
CM_ SG_ 1189 BMS_CellT22 "BMS_CellT22";
CM_ SG_ 1189 BMS_CellT23 "BMS_CellT23";
CM_ SG_ 1189 BMS_CellT24 "BMS_CellT24";
CM_ SG_ 1190 BMS_CellT25 "BMS_CellT25";
CM_ SG_ 1190 BMS_CellT26 "BMS_CellT26";
CM_ SG_ 1190 BMS_CellT27 "BMS_CellT27";
CM_ SG_ 1190 BMS_CellT28 "BMS_CellT28";
CM_ SG_ 1190 BMS_CellT29 "BMS_CellT29";
CM_ SG_ 1190 BMS_CellT30 "BMS_CellT30";
CM_ SG_ 1190 BMS_CellT31 "BMS_CellT31";
CM_ SG_ 1190 BMS_CellT32 "BMS_CellT32";
CM_ SG_ 1191 BMS_CellT33 "BMS_CellT33";
CM_ SG_ 1191 BMS_CellT34 "BMS_CellT34";
CM_ SG_ 1191 BMS_CellT35 "BMS_CellT35";
CM_ SG_ 1191 BMS_CellT36 "BMS_CellT36";
CM_ SG_ 1282 CVC_srcNodeID "Network Management Signal";
CM_ SG_ 1282 CVC_CtrlBitVector "Network Management Signal";
CM_ SG_ 1282 CVC_usrData0 "Network Management Signal";
CM_ SG_ 1282 CVC_usrData1 "Network Management Signal";
CM_ SG_ 1282 CVC_usrData2 "Network Management Signal";
CM_ SG_ 1282 CVC_usrData3 "Network Management Signal";
CM_ SG_ 1282 CVC_usrData4 "Network Management Signal";
CM_ SG_ 1282 CVC_usrData5 "Network Management Signal";
CM_ SG_ 1299 BMS_srcNodeID "Network Management Signal";
CM_ SG_ 1299 BMS_CtrlBitVector "Network Management Signal";
CM_ SG_ 1299 BMS_usrData0 "Network Management Signal";
CM_ SG_ 1299 BMS_usrData1 "Network Management Signal";
CM_ SG_ 1299 BMS_usrData2 "Network Management Signal";
CM_ SG_ 1299 BMS_usrData3 "Network Management Signal";
CM_ SG_ 1299 BMS_usrData4 "Network Management Signal";
CM_ SG_ 1299 BMS_usrData5 "Network Management Signal";
CM_ SG_ 1311 EVCC_srcNodeID "Network Management Signal";
CM_ SG_ 1311 EVCC_CtrlBitVector "Network Management Signal";
CM_ SG_ 1311 EVCC_usrData0 "Network Management Signal";
CM_ SG_ 1311 EVCC_usrData1 "Network Management Signal";
CM_ SG_ 1311 EVCC_usrData2 "Network Management Signal";
CM_ SG_ 1311 EVCC_usrData3 "Network Management Signal";
CM_ SG_ 1311 EVCC_usrData4 "Network Management Signal";
CM_ SG_ 1311 EVCC_usrData5 "Network Management Signal";
CM_ SG_ 1545 CCU_DiagRespData0 "Data0";
CM_ SG_ 1545 CCU_DiagRespData1 "Data1";
CM_ SG_ 1545 CCU_DiagRespData2 "Data2";
CM_ SG_ 1545 CCU_DiagRespData3 "Data3";
CM_ SG_ 1545 CCU_DiagRespData4 "Data4";
CM_ SG_ 1545 CCU_DiagRespData5 "Data5";
CM_ SG_ 1545 CCU_DiagRespData6 "Data6";
CM_ SG_ 1545 CCU_DiagRespData7 "Data7";
CM_ SG_ 1555 BMS_DiagRespData0 "Diagnostic signal Data response";
CM_ SG_ 1555 BMS_DiagRespData1 "Diagnostic signal Data response";
CM_ SG_ 1555 BMS_DiagRespData2 "Diagnostic signal Data response";
CM_ SG_ 1555 BMS_DiagRespData3 "Diagnostic signal Data response";
CM_ SG_ 1555 BMS_DiagRespData4 "Diagnostic signal Data response";
CM_ SG_ 1555 BMS_DiagRespData5 "Diagnostic signal Data response";
CM_ SG_ 1555 BMS_DiagRespData6 "Diagnostic signal Data response";
CM_ SG_ 1555 BMS_DiagRespData7 "Remote Diagnostic signal Data response";
CM_ SG_ 1563 FMCU_DiagRespData0 "Data0";
CM_ SG_ 1563 FMCU_DiagRespData1 "Data1";
CM_ SG_ 1563 FMCU_DiagRespData2 "Data2";
CM_ SG_ 1563 FMCU_DiagRespData3 "Data3";
CM_ SG_ 1563 FMCU_DiagRespData4 "Data4";
CM_ SG_ 1563 FMCU_DiagRespData5 "Data5";
CM_ SG_ 1563 FMCU_DiagRespData6 "Data6";
CM_ SG_ 1563 FMCU_DiagRespData7 "Data7";
CM_ SG_ 1567 EVCC_DiagRespData0 "Data0";
CM_ SG_ 1567 EVCC_DiagRespData1 "Data1";
CM_ SG_ 1567 EVCC_DiagRespData2 "Data2";
CM_ SG_ 1567 EVCC_DiagRespData3 "Data3";
CM_ SG_ 1567 EVCC_DiagRespData4 "Data4";
CM_ SG_ 1567 EVCC_DiagRespData5 "Data5";
CM_ SG_ 1567 EVCC_DiagRespData6 "Data6";
CM_ SG_ 1567 EVCC_DiagRespData7 "Data7";
CM_ SG_ 1597 PDU_DiagRespData0 "Data0";
CM_ SG_ 1597 PDU_DiagRespData1 "Data1";
CM_ SG_ 1597 PDU_DiagRespData2 "Data2";
CM_ SG_ 1597 PDU_DiagRespData3 "Data3";
CM_ SG_ 1597 PDU_DiagRespData4 "Data4";
CM_ SG_ 1597 PDU_DiagRespData5 "Data5";
CM_ SG_ 1597 PDU_DiagRespData6 "Data6";
CM_ SG_ 1597 PDU_DiagRespData7 "Data7";
CM_ SG_ 1598 PDU_OBC_DiagRespData0 "Data0";
CM_ SG_ 1598 PDU_OBC_DiagRespData1 "Data1";
CM_ SG_ 1598 PDU_OBC_DiagRespData2 "Data2";
CM_ SG_ 1598 PDU_OBC_DiagRespData3 "Data3";
CM_ SG_ 1598 PDU_OBC_DiagRespData4 "Data4";
CM_ SG_ 1598 PDU_OBC_DiagRespData5 "Data5";
CM_ SG_ 1598 PDU_OBC_DiagRespData6 "Data6";
CM_ SG_ 1598 PDU_OBC_DiagRespData7 "Data7";
CM_ SG_ 1726 PDU_OBC_DiagReqData0 "Data0";
CM_ SG_ 1726 PDU_OBC_DiagReqData1 "Data1";
CM_ SG_ 1726 PDU_OBC_DiagReqData2 "Data2";
CM_ SG_ 1726 PDU_OBC_DiagReqData3 "Data3";
CM_ SG_ 1726 PDU_OBC_DiagReqData4 "Data4";
CM_ SG_ 1726 PDU_OBC_DiagReqData5 "Data5";
CM_ SG_ 1726 PDU_OBC_DiagReqData6 "Data6";
CM_ SG_ 1726 PDU_OBC_DiagReqData7 "Data7";
CM_ SG_ 1673 CCU_DiagReqData0 "Data0";
CM_ SG_ 1673 CCU_DiagReqData1 "Data1";
CM_ SG_ 1673 CCU_DiagReqData2 "Data2";
CM_ SG_ 1673 CCU_DiagReqData3 "Data3";
CM_ SG_ 1673 CCU_DiagReqData4 "Data4";
CM_ SG_ 1673 CCU_DiagReqData5 "Data5";
CM_ SG_ 1673 CCU_DiagReqData6 "Data6";
CM_ SG_ 1673 CCU_DiagReqData7 "Data7";
CM_ SG_ 1683 BMS_DiagReqData0 "Data0";
CM_ SG_ 1683 BMS_DiagReqData1 "Data1";
CM_ SG_ 1683 BMS_DiagReqData2 "Data2";
CM_ SG_ 1683 BMS_DiagReqData3 "Data3";
CM_ SG_ 1683 BMS_DiagReqData4 "Data4";
CM_ SG_ 1683 BMS_DiagReqData5 "Data5";
CM_ SG_ 1683 BMS_DiagReqData6 "Data6";
CM_ SG_ 1683 BMS_DiagReqData7 "Data7";
CM_ SG_ 1691 FMCU_DiagReqData0 "Data0";
CM_ SG_ 1691 FMCU_DiagReqData1 "Data1";
CM_ SG_ 1691 FMCU_DiagReqData2 "Data2";
CM_ SG_ 1691 FMCU_DiagReqData3 "Data3";
CM_ SG_ 1691 FMCU_DiagReqData4 "Data4";
CM_ SG_ 1691 FMCU_DiagReqData5 "Data5";
CM_ SG_ 1691 FMCU_DiagReqData6 "Data6";
CM_ SG_ 1691 FMCU_DiagReqData7 "Data7";
CM_ SG_ 1695 EVCC_DiagReqData0 "Data0";
CM_ SG_ 1695 EVCC_DiagReqData1 "Data1";
CM_ SG_ 1695 EVCC_DiagReqData2 "Data2";
CM_ SG_ 1695 EVCC_DiagReqData3 "Data3";
CM_ SG_ 1695 EVCC_DiagReqData4 "Data4";
CM_ SG_ 1695 EVCC_DiagReqData5 "Data5";
CM_ SG_ 1695 EVCC_DiagReqData6 "Data6";
CM_ SG_ 1695 EVCC_DiagReqData7 "Data7";
CM_ SG_ 1725 PDU_DiagReqData0 "Data0";
CM_ SG_ 1725 PDU_DiagReqData1 "Data1";
CM_ SG_ 1725 PDU_DiagReqData2 "Data2";
CM_ SG_ 1725 PDU_DiagReqData3 "Data3";
CM_ SG_ 1725 PDU_DiagReqData4 "Data4";
CM_ SG_ 1725 PDU_DiagReqData5 "Data5";
CM_ SG_ 1725 PDU_DiagReqData6 "Data6";
CM_ SG_ 1725 PDU_DiagReqData7 "Data7";
CM_ SG_ 1791 DiagReqAllEcuData0 "Data0";
CM_ SG_ 1791 DiagReqAllEcuData1 "Data1";
CM_ SG_ 1791 DiagReqAllEcuData2 "Data2";
CM_ SG_ 1791 DiagReqAllEcuData3 "Data3";
CM_ SG_ 1791 DiagReqAllEcuData4 "Data4";
CM_ SG_ 1791 DiagReqAllEcuData5 "Data5";
CM_ SG_ 1791 DiagReqAllEcuData6 "Data6";
CM_ SG_ 1791 DiagReqAllEcuData7 "Data7";
CM_ BO_ 1939 "BMS XCP TX message";
CM_ SG_ 1939 BMS_XCPTxData "XCP TX signal";
CM_ BO_ 1986 "BMS XCPRx";
CM_ SG_ 1986 BMS_XCPRxData "XCP RX signal";
BA_DEF_ SG_  "GenSigSendType" ENUM  "Cyclic","OnWrite","OnWriteWithRepetition","OnChange","OnChangeWithRepetition","IfActive","IfActiveWithRepetition","NoSigSendType","NotUsed","NotUsed","NotUsed","NotUsed","NotUsed";
BA_DEF_ SG_  "GenSigTimeoutTime_ALL" INT 0 65535;
BA_DEF_ SG_  "InvalidValue" STRING ;
BA_DEF_ BO_  "GenMsgCycleTimeFast" INT 0 0;
BA_DEF_ BO_  "NmAsrMessage" ENUM  "No","Yes";
BA_DEF_ BO_  "GenMsgILSupport" ENUM  "No","Yes";
BA_DEF_ BO_  "GenMsgNrOfRepetition" INT 0 0;
BA_DEF_ BO_  "GenMsgDelayTime" INT 0 0;
BA_DEF_ BO_  "DiagUudtResponse" ENUM  "False","True";
BA_DEF_ BO_  "DiagState" ENUM  "No","Yes";
BA_DEF_ BO_  "DiagResponse" ENUM  "No","Yes";
BA_DEF_ BO_  "DiagRequest" ENUM  "No","Yes";
BA_DEF_ BO_  "GenMsgCycleTime" INT 0 65535;
BA_DEF_ BO_  "GenMsgSendType" ENUM  "Cyclic","Event","Mix";
BA_DEF_ BO_  "GenMsgStartDelayTime" INT 0 65535;
BA_DEF_ SG_  "GenSigStartValue" HEX 0 0;
BA_DEF_DEF_  "GenSigSendType" "Cyclic";
BA_DEF_DEF_  "GenSigTimeoutTime_ALL" 0;
BA_DEF_DEF_  "InvalidValue" "";
BA_DEF_DEF_  "GenMsgCycleTimeFast" 0;
BA_DEF_DEF_  "NmAsrMessage" "No";
BA_DEF_DEF_  "GenMsgILSupport" "Yes";
BA_DEF_DEF_  "GenMsgNrOfRepetition" 0;
BA_DEF_DEF_  "GenMsgDelayTime" 0;
BA_DEF_DEF_  "DiagUudtResponse" "False";
BA_DEF_DEF_  "DiagState" "No";
BA_DEF_DEF_  "DiagResponse" "No";
BA_DEF_DEF_  "DiagRequest" "No";
BA_DEF_DEF_  "GenMsgCycleTime" 100;
BA_DEF_DEF_  "GenMsgSendType" "Cyclic";
BA_DEF_DEF_  "GenMsgStartDelayTime" 0;
BA_DEF_DEF_  "GenSigStartValue" 0;
BA_ "GenMsgILSupport" BO_ 885 0;
BA_ "GenMsgCycleTime" BO_ 885 50;
BA_ "GenMsgCycleTime" BO_ 896 1000;
BA_ "GenMsgCycleTime" BO_ 919 500;
BA_ "GenMsgCycleTime" BO_ 920 500;
BA_ "GenMsgCycleTime" BO_ 1009 1000;
BA_ "GenMsgCycleTime" BO_ 1098 1000;
BA_ "GenMsgILSupport" BO_ 1110 0;
BA_ "GenMsgCycleTime" BO_ 1118 200;
BA_ "GenMsgCycleTime" BO_ 1119 200;
BA_ "GenMsgCycleTime" BO_ 1117 1000;
BA_ "GenMsgCycleTime" BO_ 1120 200;
BA_ "GenMsgCycleTime" BO_ 1146 1000;
BA_ "GenMsgNrOfRepetition" BO_ 1171 2;
BA_ "GenMsgCycleTimeFast" BO_ 1171 100;
BA_ "GenMsgCycleTime" BO_ 1171 1000;
BA_ "GenMsgCycleTime" BO_ 1184 2000;
BA_ "GenMsgCycleTime" BO_ 1188 2000;
BA_ "GenMsgCycleTime" BO_ 1189 2000;
BA_ "GenMsgCycleTime" BO_ 1190 2000;
BA_ "GenMsgCycleTime" BO_ 1191 2000;
BA_ "GenMsgCycleTime" BO_ 1192 1000;
BA_ "GenMsgCycleTime" BO_ 1193 1000;
BA_ "GenMsgCycleTime" BO_ 1196 1000;
BA_ "GenMsgCycleTime" BO_ 1197 1000;
BA_ "GenMsgCycleTime" BO_ 1198 1000;
BA_ "GenMsgCycleTime" BO_ 1199 1000;
BA_ "GenMsgCycleTime" BO_ 1200 1000;
BA_ "GenMsgCycleTime" BO_ 1201 1000;
BA_ "GenMsgCycleTime" BO_ 1202 1000;
BA_ "GenMsgCycleTime" BO_ 1203 1000;
BA_ "GenMsgCycleTime" BO_ 1204 1000;
BA_ "GenMsgCycleTime" BO_ 1205 1000;
BA_ "GenMsgCycleTime" BO_ 1206 1000;
BA_ "GenMsgCycleTime" BO_ 1207 1000;
BA_ "GenMsgCycleTime" BO_ 1208 1000;
BA_ "GenMsgCycleTime" BO_ 1209 1000;
BA_ "GenMsgCycleTime" BO_ 1210 1000;
BA_ "GenMsgCycleTime" BO_ 1211 1000;
BA_ "GenMsgCycleTime" BO_ 1212 1000;
BA_ "GenMsgCycleTime" BO_ 1213 1000;
BA_ "GenMsgCycleTime" BO_ 1214 1000;
BA_ "GenMsgCycleTime" BO_ 1215 1000;
BA_ "GenMsgCycleTime" BO_ 1216 1000;
BA_ "GenMsgCycleTime" BO_ 1217 1000;
BA_ "GenMsgCycleTime" BO_ 1218 1000;
BA_ "GenMsgCycleTime" BO_ 1219 1000;
BA_ "GenMsgCycleTime" BO_ 1220 1000;
BA_ "GenMsgCycleTime" BO_ 1221 1000;
BA_ "GenMsgCycleTime" BO_ 1222 1000;
BA_ "GenMsgCycleTime" BO_ 1223 1000;
BA_ "GenMsgCycleTime" BO_ 1224 1000;
BA_ "GenMsgCycleTime" BO_ 1225 1000;
BA_ "GenMsgCycleTime" BO_ 1226 1000;
BA_ "GenMsgCycleTime" BO_ 1227 1000;
BA_ "GenMsgCycleTime" BO_ 1282 640;
BA_ "GenMsgILSupport" BO_ 1282 0;
BA_ "NmAsrMessage" BO_ 1282 1;
BA_ "NmAsrMessage" BO_ 1299 1;
BA_ "GenMsgILSupport" BO_ 1299 0;
BA_ "GenMsgCycleTime" BO_ 1299 640;
BA_ "NmAsrMessage" BO_ 1307 1;
BA_ "GenMsgCycleTime" BO_ 1307 640;
BA_ "NmAsrMessage" BO_ 1311 1;
BA_ "GenMsgILSupport" BO_ 1311 0;
BA_ "GenMsgCycleTime" BO_ 1311 640;
BA_ "NmAsrMessage" BO_ 1341 1;
BA_ "GenMsgCycleTime" BO_ 1341 640;
BA_ "DiagResponse" BO_ 1545 1;
BA_ "GenMsgSendType" BO_ 1545 1;
BA_ "GenMsgCycleTime" BO_ 1545 0;
BA_ "GenMsgCycleTime" BO_ 1555 0;
BA_ "GenMsgILSupport" BO_ 1555 0;
BA_ "DiagResponse" BO_ 1555 1;
BA_ "GenMsgSendType" BO_ 1555 1;
BA_ "GenMsgCycleTime" BO_ 1606 0;
BA_ "GenMsgILSupport" BO_ 1606 0;
BA_ "DiagResponse" BO_ 1606 1;
BA_ "GenMsgSendType" BO_ 1606 1;
BA_ "GenMsgSendType" BO_ 1563 1;
BA_ "GenMsgCycleTime" BO_ 1563 0;
BA_ "DiagResponse" BO_ 1563 1;
BA_ "GenMsgSendType" BO_ 1567 1;
BA_ "GenMsgCycleTime" BO_ 1567 0;
BA_ "DiagResponse" BO_ 1567 1;
BA_ "GenMsgSendType" BO_ 1597 1;
BA_ "GenMsgCycleTime" BO_ 1597 0;
BA_ "DiagResponse" BO_ 1597 1;
BA_ "GenMsgSendType" BO_ 1598 1;
BA_ "GenMsgCycleTime" BO_ 1598 0;
BA_ "DiagResponse" BO_ 1598 1;
BA_ "DiagRequest" BO_ 1726 1;
BA_ "GenMsgSendType" BO_ 1726 1;
BA_ "GenMsgCycleTime" BO_ 1726 0;
BA_ "DiagRequest" BO_ 1673 1;
BA_ "GenMsgSendType" BO_ 1673 1;
BA_ "GenMsgCycleTime" BO_ 1673 0;
BA_ "GenMsgSendType" BO_ 1683 1;
BA_ "GenMsgCycleTime" BO_ 1683 0;
BA_ "DiagRequest" BO_ 1683 1;
BA_ "GenMsgSendType" BO_ 1734 1;
BA_ "GenMsgCycleTime" BO_ 1734 0;
BA_ "DiagRequest" BO_ 1734 1;
BA_ "GenMsgSendType" BO_ 1691 1;
BA_ "GenMsgCycleTime" BO_ 1691 0;
BA_ "DiagRequest" BO_ 1691 1;
BA_ "GenMsgSendType" BO_ 1695 1;
BA_ "GenMsgCycleTime" BO_ 1695 0;
BA_ "DiagRequest" BO_ 1695 1;
BA_ "GenMsgSendType" BO_ 1725 1;
BA_ "GenMsgCycleTime" BO_ 1725 0;
BA_ "DiagRequest" BO_ 1725 1;
BA_ "GenMsgSendType" BO_ 1791 1;
BA_ "GenMsgCycleTime" BO_ 1791 0;
BA_ "DiagRequest" BO_ 1791 1;
BA_ "GenMsgCycleTime" BO_ 1939 0;
BA_ "GenMsgILSupport" BO_ 1939 0;
BA_ "GenMsgSendType" BO_ 1939 1;
BA_ "GenMsgCycleTime" BO_ 1986 0;
BA_ "GenMsgILSupport" BO_ 1986 0;
BA_ "GenMsgSendType" BO_ 1986 1;
BA_ "InvalidValue" SG_ 821 CCU_BlowmotorPos "FFh";
BA_ "GenSigTimeoutTime_ALL" SG_ 820 BMS_ErrorCategory_CAT0 500;
BA_ "GenSigTimeoutTime_ALL" SG_ 820 BMS_ErrorCategory_CAT1 500;
BA_ "GenSigTimeoutTime_ALL" SG_ 820 BMS_ErrorCategory_CAT2 500;
BA_ "GenSigTimeoutTime_ALL" SG_ 820 BMS_ErrorCategory_CAT3 500;
BA_ "GenSigTimeoutTime_ALL" SG_ 820 BMS_ErrorCategory_CAT4 500;
BA_ "GenSigTimeoutTime_ALL" SG_ 820 BMS_ErrorCategory_CAT5 500;
BA_ "GenSigTimeoutTime_ALL" SG_ 820 BMS_ErrorCategory_CAT6 500;
BA_ "GenSigTimeoutTime_ALL" SG_ 820 BMS_ErrorCategory_CAT7 500;
BA_ "GenSigTimeoutTime_ALL" SG_ 820 BMS_ErrorCategory_CAT8 500;
BA_ "GenSigTimeoutTime_ALL" SG_ 843 CRC_EVSE_Info_1 500;
BA_ "GenSigTimeoutTime_ALL" SG_ 843 ALIV_EVSE_Info_1 500;
BA_ "InvalidValue" SG_ 843 ALIV_EVSE_Info_1 "Fh";
BA_ "GenSigTimeoutTime_ALL" SG_ 843 EVSE_DC_Stt 500;
BA_ "GenSigTimeoutTime_ALL" SG_ 843 EVSE_CtrlPilot_PWM_value 500;
BA_ "GenSigTimeoutTime_ALL" SG_ 843 EVSE_CtrlPilot_STS 500;
BA_ "GenSigTimeoutTime_ALL" SG_ 843 EVSE_IsolationLvl 500;
BA_ "GenSigTimeoutTime_ALL" SG_ 843 EVSE_VehChgComm_STAT 500;
BA_ "GenSigTimeoutTime_ALL" SG_ 843 EVSE_ResponseCode 500;
BA_ "GenSigTimeoutTime_ALL" SG_ 843 EVSE_AC_MaxLineCur 500;
BA_ "GenSigTimeoutTime_ALL" SG_ 845 CRC_EVCC_Insulation 500;
BA_ "InvalidValue" SG_ 845 ALIVE_EVCC_Insulation "Fh";
BA_ "GenSigTimeoutTime_ALL" SG_ 845 ALIVE_EVCC_Insulation 500;
BA_ "InvalidValue" SG_ 845 EVCC_STAT_BrakeSts "3";
BA_ "GenSigTimeoutTime_ALL" SG_ 845 EVCC_STAT_BrakeSts 500;
BA_ "InvalidValue" SG_ 845 EVCC_Req_InsulationMon "3";
BA_ "GenSigTimeoutTime_ALL" SG_ 845 EVCC_Req_InsulationMon 500;
BA_ "InvalidValue" SG_ 845 EVCC_PnC_Contract_STS "3";
BA_ "GenSigTimeoutTime_ALL" SG_ 845 EVCC_PnC_Contract_STS 500;
BA_ "InvalidValue" SG_ 845 EVCC_FcContactor_Req "4";
BA_ "GenSigTimeoutTime_ALL" SG_ 845 EVCC_FcContactor_Req 500;
BA_ "GenSigTimeoutTime_ALL" SG_ 845 EVCC_HighSidePressure 500;
BA_ "InvalidValue" SG_ 845 EVCC_FcContactor_Sts "4";
BA_ "GenSigTimeoutTime_ALL" SG_ 845 EVCC_FcContactor_Sts 500;
BA_ "GenSigTimeoutTime_ALL" SG_ 847 CRC_EVSE_Info_2 500;
BA_ "InvalidValue" SG_ 847 ALIV_EVSE_Info_2 "Fh";
BA_ "GenSigTimeoutTime_ALL" SG_ 847 ALIV_EVSE_Info_2 500;
BA_ "InvalidValue" SG_ 847 EVSE_DC_MaxChgCur "FFFFh";
BA_ "GenSigTimeoutTime_ALL" SG_ 847 EVSE_DC_MaxChgCur 500;
BA_ "InvalidValue" SG_ 847 EVSE_DC_MaxChgPwr "FFFFh";
BA_ "GenSigTimeoutTime_ALL" SG_ 847 EVSE_DC_MaxChgPwr 500;
BA_ "InvalidValue" SG_ 847 EVSE_DC_ActCurOut "FFFFh";
BA_ "GenSigTimeoutTime_ALL" SG_ 847 EVSE_DC_ActCurOut 500;
BA_ "GenSigTimeoutTime_ALL" SG_ 850 CRC_Thermal_Info_1 500;
BA_ "InvalidValue" SG_ 850 ALIV_Thermal_Info_1 "Fh";
BA_ "GenSigTimeoutTime_ALL" SG_ 850 ALIV_Thermal_Info_1 500;
BA_ "GenSigTimeoutTime_ALL" SG_ 850 EVCC_MotorWaterPump_PWM_fb 500;
BA_ "GenSigTimeoutTime_ALL" SG_ 850 EVCC_SOV2_ControlStatus 500;
BA_ "GenSigStartValue" SG_ 850 EVCC_SOV2_ControlStatus 1;
BA_ "GenSigTimeoutTime_ALL" SG_ 850 EVCC_BatteryWaterPump_PWM_fb 500;
BA_ "GenSigTimeoutTime_ALL" SG_ 850 EVCC_SOV1_ControlStatus 500;
BA_ "GenSigStartValue" SG_ 850 EVCC_SOV1_ControlStatus 1;
BA_ "GenSigTimeoutTime_ALL" SG_ 850 EVCC_MotorWaterPump_Status 500;
BA_ "GenSigStartValue" SG_ 850 EVCC_MotorWaterPump_Status 1;
BA_ "GenSigTimeoutTime_ALL" SG_ 850 EVCC_BatteryWaterPump_Status 500;
BA_ "GenSigStartValue" SG_ 850 EVCC_BatteryWaterPump_Status 1;
BA_ "GenSigTimeoutTime_ALL" SG_ 850 EVCC_ACPressure 500;
BA_ "GenSigStartValue" SG_ 850 EVCC_ACPressure 546;
BA_ "InvalidValue" SG_ 850 EVCC_ACPressure "3FFFh";
BA_ "GenSigTimeoutTime_ALL" SG_ 850 EVCC_PTC_OnOff_Status 500;
BA_ "GenSigStartValue" SG_ 850 EVCC_PTC_OnOff_Status 1;
BA_ "GenSigTimeoutTime_ALL" SG_ 851 CRC_Thermal_Info_2 500;
BA_ "InvalidValue" SG_ 851 ALIV_Thermal_Info_2 "Fh";
BA_ "GenSigTimeoutTime_ALL" SG_ 851 ALIV_Thermal_Info_2 500;
BA_ "GenSigStartValue" SG_ 851 EVCC_EAC_OnOff_Status 1;
BA_ "GenSigTimeoutTime_ALL" SG_ 851 EVCC_EAC_OnOff_Status 500;
BA_ "GenSigStartValue" SG_ 851 EVCC_DualPressureSwitch_Status 1;
BA_ "GenSigTimeoutTime_ALL" SG_ 851 EVCC_DualPressureSwitch_Status 500;
BA_ "GenSigStartValue" SG_ 851 EVCC_MainRelay_OnOff_Status 1;
BA_ "GenSigTimeoutTime_ALL" SG_ 851 EVCC_MainRelay_OnOff_Status 500;
BA_ "GenSigTimeoutTime_ALL" SG_ 851 EVCC_ElectricFan_OnOff_Sts 500;
BA_ "GenSigStartValue" SG_ 851 EVCC_ElectricFan_OnOff_Sts 1;
BA_ "GenSigStartValue" SG_ 851 EVCC_CL15_Status 1;
BA_ "GenSigTimeoutTime_ALL" SG_ 851 EVCC_CL15_Status 500;
BA_ "GenSigStartValue" SG_ 851 EVCC_PGearPressSignal1_Status 1;
BA_ "GenSigTimeoutTime_ALL" SG_ 851 EVCC_PGearPressSignal1_Status 500;
BA_ "GenSigStartValue" SG_ 851 EVCC_PGearStsLight_OnOff_Sts 1;
BA_ "GenSigTimeoutTime_ALL" SG_ 851 EVCC_PGearStsLight_OnOff_Sts 500;
BA_ "GenSigStartValue" SG_ 851 EVCC_PGearPressSignal2_Status 30;
BA_ "GenSigTimeoutTime_ALL" SG_ 851 EVCC_PGearPressSignal2_Status 500;
BA_ "GenSigStartValue" SG_ 851 EVCC_ExpValve_OnOff_Status 1;
BA_ "GenSigTimeoutTime_ALL" SG_ 851 EVCC_ExpValve_OnOff_Status 500;
BA_ "InvalidValue" SG_ 851 EVCC_EACPTCHVIL_Status "3h";
BA_ "GenSigTimeoutTime_ALL" SG_ 851 EVCC_EACPTCHVIL_Status 500;
BA_ "GenSigTimeoutTime_ALL" SG_ 851 EVCC_ElectricFan_PWM_fb 500;
BA_ "GenSigTimeoutTime_ALL" SG_ 851 EVCC_ACTemperature 500;
BA_ "GenSigStartValue" SG_ 851 EVCC_ACTemperature 60;
BA_ "GenSigTimeoutTime_ALL" SG_ 851 EVCC_Motor_TempSensor 500;
BA_ "GenSigStartValue" SG_ 851 EVCC_Motor_TempSensor 60;
BA_ "GenSigTimeoutTime_ALL" SG_ 852 CRC_CVC_Thermal_Info_1 500;
BA_ "InvalidValue" SG_ 852 ALIV_CVC_Thermal_Info_1 "Fh";
BA_ "GenSigTimeoutTime_ALL" SG_ 852 ALIV_CVC_Thermal_Info_1 500;
BA_ "GenSigTimeoutTime_ALL" SG_ 852 CVC_BatteryWaterPump_OnOff_Req 500;
BA_ "GenSigTimeoutTime_ALL" SG_ 852 CVC_EAC_OnOff_Req 500;
BA_ "GenSigTimeoutTime_ALL" SG_ 852 CVC_PGearStatusLight_OnOff_Req 500;
BA_ "GenSigTimeoutTime_ALL" SG_ 852 CVC_MotorWaterPump_PWM_Req 500;
BA_ "GenSigTimeoutTime_ALL" SG_ 852 CVC_BatteryWaterPump_PWM_Req 500;
BA_ "GenSigTimeoutTime_ALL" SG_ 852 CVC_PTC_OnOff_Req 500;
BA_ "GenSigTimeoutTime_ALL" SG_ 852 CVC_ExpValve_OnOff_Req 500;
BA_ "GenSigTimeoutTime_ALL" SG_ 852 CVC_SOV2_ControlReq 500;
BA_ "GenSigTimeoutTime_ALL" SG_ 852 CVC_DriveCoolWaterFlowRate 500;
BA_ "GenSigTimeoutTime_ALL" SG_ 852 CVC_EACAllowedPower 500;
BA_ "GenSigTimeoutTime_ALL" SG_ 852 CVC_ElectricFan_PWM_Req 500;
BA_ "GenSigTimeoutTime_ALL" SG_ 853 CRC_CVC_Thermal_Info_2 500;
BA_ "InvalidValue" SG_ 853 ALIV_CVC_Thermal_Info_2 "Fh";
BA_ "GenSigTimeoutTime_ALL" SG_ 853 ALIV_CVC_Thermal_Info_2 500;
BA_ "GenSigTimeoutTime_ALL" SG_ 853 CVC_SOV1_ControlReq 500;
BA_ "GenSigTimeoutTime_ALL" SG_ 853 CVC_MotorWaterPump_OnOff_Req 500;
BA_ "GenSigTimeoutTime_ALL" SG_ 853 CVC_MainRelay_OnOff_Req 500;
BA_ "GenSigTimeoutTime_ALL" SG_ 853 CVC_ElectricFan_Enable 500;
BA_ "GenSigTimeoutTime_ALL" SG_ 855 CRC_CVC_ChgSetting_Info 500;
BA_ "InvalidValue" SG_ 855 ALIV_CVC_ChgSetting_Info "Fh";
BA_ "GenSigTimeoutTime_ALL" SG_ 855 ALIV_CVC_ChgSetting_Info 500;
BA_ "InvalidValue" SG_ 855 CVC_Ack_LimitSetting_SOC "7Fh";
BA_ "GenSigTimeoutTime_ALL" SG_ 855 CVC_Ack_LimitSetting_SOC 500;
BA_ "GenSigTimeoutTime_ALL" SG_ 855 CVC_ACInputChgCurLim 500;
BA_ "GenSigTimeoutTime_ALL" SG_ 858 CRC_CVC_CP_Req 500;
BA_ "InvalidValue" SG_ 858 ALIV_CVC_CP_Req "Fh";
BA_ "GenSigTimeoutTime_ALL" SG_ 858 ALIV_CVC_CP_Req 500;
BA_ "InvalidValue" SG_ 858 CVC_LockCP_Req "3";
BA_ "GenSigTimeoutTime_ALL" SG_ 858 CVC_LockCP_Req 500;
BA_ "GenSigTimeoutTime_ALL" SG_ 859 CRC_EVCC_ACCharging_Req 500;
BA_ "InvalidValue" SG_ 859 ALIV_EVCC_ACCharging_Req "Fh";
BA_ "GenSigTimeoutTime_ALL" SG_ 859 ALIV_EVCC_ACCharging_Req 500;
BA_ "InvalidValue" SG_ 859 OBC_Req "3";
BA_ "GenSigTimeoutTime_ALL" SG_ 859 OBC_Req 500;
BA_ "GenSigTimeoutTime_ALL" SG_ 859 OBC_OutputVol_Req 500;
BA_ "InvalidValue" SG_ 859 OBC_OutputCur_Req "FFFFh";
BA_ "GenSigTimeoutTime_ALL" SG_ 859 OBC_OutputCur_Req 500;
BA_ "GenSigTimeoutTime_ALL" SG_ 859 OBC_ACInputChgCurLim 500;
BA_ "GenSigTimeoutTime_ALL" SG_ 862 CRC_CVC_Vehicle_info 500;
BA_ "InvalidValue" SG_ 862 ALIV_CVC_Vehicle_info "Fh";
BA_ "GenSigTimeoutTime_ALL" SG_ 862 ALIV_CVC_Vehicle_info 500;
BA_ "InvalidValue" SG_ 862 CVC_VehLock_STS "3h";
BA_ "GenSigTimeoutTime_ALL" SG_ 862 CVC_VehLock_STS 500;
BA_ "InvalidValue" SG_ 862 CVC_VehSpd_ScreenDisplay "FFh";
BA_ "GenSigTimeoutTime_ALL" SG_ 862 CVC_VehSpd_ScreenDisplay 500;
BA_ "InvalidValue" SG_ 862 CVC_VehChgAllow "3";
BA_ "GenSigTimeoutTime_ALL" SG_ 862 CVC_VehChgAllow 500;
BA_ "GenSigTimeoutTime_ALL" SG_ 862 Re_InitCharging_Req 500;
BA_ "InvalidValue" SG_ 862 Re_InitCharging_Req "3h";
BA_ "InvalidValue" SG_ 862 CVC_GunUnlock_Req "3h";
BA_ "GenSigTimeoutTime_ALL" SG_ 862 CVC_GunUnlock_Req 500;
BA_ "GenSigTimeoutTime_ALL" SG_ 862 CVC_StopChg_Req 500;
BA_ "InvalidValue" SG_ 873 ALIV_FMCU_Info "Fh";
BA_ "GenSigStartValue" SG_ 873 FMCU_MCUTemp 40;
BA_ "GenSigStartValue" SG_ 873 FMCU_MotorTemp 40;
BA_ "InvalidValue" SG_ 873 FMCU_MotorTemp "FFh";
BA_ "GenSigStartValue" SG_ 873 FMCU_MotorTempU 40;
BA_ "GenSigStartValue" SG_ 873 FMCU_MotorTempV 40;
BA_ "GenSigStartValue" SG_ 873 FMCU_MotorTempW 40;
BA_ "InvalidValue" SG_ 876 ALIV_AC_36C "Fh";
BA_ "GenSigTimeoutTime_ALL" SG_ 876 AC_PTC_HeatPwrReq 500;
BA_ "InvalidValue" SG_ 876 AC_PTC_HeatPwrReq "FFh";
BA_ "GenSigTimeoutTime_ALL" SG_ 876 AC_PTC_Enable 500;
BA_ "GenSigStartValue" SG_ 884 PTC_PCBT 48;
BA_ "GenSigTimeoutTime_ALL" SG_ 885 Checksum_0x375 500;
BA_ "InvalidValue" SG_ 885 Rolling_Counter_0x375 "Fh";
BA_ "GenSigTimeoutTime_ALL" SG_ 885 Rolling_Counter_0x375 500;
BA_ "GenSigTimeoutTime_ALL" SG_ 885 BMS_PreChgRelay_ERR 500;
BA_ "GenSigTimeoutTime_ALL" SG_ 885 BMS_TotalNegRelay_ERR 500;
BA_ "GenSigTimeoutTime_ALL" SG_ 885 BMS_MainPosRelay_ERR 500;
BA_ "InvalidValue" SG_ 885 BMS_MainPosRelay_STS "7h";
BA_ "GenSigTimeoutTime_ALL" SG_ 885 BMS_MainPosRelay_STS 500;
BA_ "InvalidValue" SG_ 885 BMS_PreChgRelay_STS "7h";
BA_ "GenSigTimeoutTime_ALL" SG_ 885 BMS_PreChgRelay_STS 500;
BA_ "InvalidValue" SG_ 885 BMS_TotalNegRelay_STS "7h";
BA_ "GenSigTimeoutTime_ALL" SG_ 885 BMS_TotalNegRelay_STS 500;
BA_ "GenSigTimeoutTime_ALL" SG_ 888 CVC_Vehicle_Operation_State 500;
BA_ "GenSigTimeoutTime_ALL" SG_ 888 CVC_CL15c_req 500;
BA_ "GenSigTimeoutTime_ALL" SG_ 888 CVC_Acc_Mode_Req 500;
BA_ "GenSigTimeoutTime_ALL" SG_ 888 Warning_Clamp_Incompatible 500;
BA_ "GenSigTimeoutTime_ALL" SG_ 888 CVC_CL30s_Timer 500;
BA_ "GenSigTimeoutTime_ALL" SG_ 888 ACC_Idle_Timer 500;
BA_ "GenSigTimeoutTime_ALL" SG_ 888 On_Idle_Timer 500;
BA_ "InvalidValue" SG_ 888 CVC_ON_Mode_Req "3h";
BA_ "GenSigTimeoutTime_ALL" SG_ 888 CVC_ON_Mode_Req 500;
BA_ "InvalidValue" SG_ 888 CVC_Vehicle_Special_Mode "7h";
BA_ "GenSigTimeoutTime_ALL" SG_ 888 CVC_Vehicle_Special_Mode 500;
BA_ "GenSigTimeoutTime_ALL" SG_ 888 ACC_LowSOC_SaveMode_Timer 500;
BA_ "GenSigTimeoutTime_ALL" SG_ 888 ON_LowSOC_SaveMode_Timer 500;
BA_ "GenSigTimeoutTime_ALL" SG_ 888 OTA_Idle_Timer 500;
BA_ "GenSigStartValue" SG_ 889 PTC_CrtT 48;
BA_ "GenSigTimeoutTime_ALL" SG_ 892 CRC_Charging_Info 500;
BA_ "InvalidValue" SG_ 892 ALIV_Charging_Info "Fh";
BA_ "GenSigTimeoutTime_ALL" SG_ 892 ALIV_Charging_Info 500;
BA_ "InvalidValue" SG_ 892 EVCC_ChgGun_Sts "7h";
BA_ "GenSigTimeoutTime_ALL" SG_ 892 EVCC_ChgGun_Sts 500;
BA_ "InvalidValue" SG_ 892 EVCC_ChgFlap_Sts "3h";
BA_ "GenSigTimeoutTime_ALL" SG_ 892 EVCC_ChgFlap_Sts 500;
BA_ "InvalidValue" SG_ 892 EVCC_ChgType "7h";
BA_ "GenSigTimeoutTime_ALL" SG_ 892 EVCC_ChgType 500;
BA_ "InvalidValue" SG_ 892 EVCC_VehChg_Sts "7h";
BA_ "GenSigTimeoutTime_ALL" SG_ 892 EVCC_VehChg_Sts 500;
BA_ "InvalidValue" SG_ 892 EVCC_ChgAuthen_Sts "7h";
BA_ "GenSigTimeoutTime_ALL" SG_ 892 EVCC_ChgAuthen_Sts 500;
BA_ "InvalidValue" SG_ 892 EVCC_PaymentType "7h";
BA_ "GenSigTimeoutTime_ALL" SG_ 892 EVCC_PaymentType 500;
BA_ "InvalidValue" SG_ 892 EVCC_VehChgCompError_Sts "null";
BA_ "GenSigTimeoutTime_ALL" SG_ 892 EVCC_VehChgCompError_Sts 500;
BA_ "GenSigTimeoutTime_ALL" SG_ 892 EVCC_ProximityPilot_Voltage 500;
BA_ "GenSigTimeoutTime_ALL" SG_ 892 EVCC_SLAC_Attenuation 500;
BA_ "GenSigTimeoutTime_ALL" SG_ 893 CRC_CVC_Battery_Info 500;
BA_ "InvalidValue" SG_ 893 ALIV_CVC_Battery_Info "Fh";
BA_ "GenSigTimeoutTime_ALL" SG_ 893 ALIV_CVC_Battery_Info 500;
BA_ "GenSigTimeoutTime_ALL" SG_ 893 CVC_HV_DispSOC 500;
BA_ "GenSigTimeoutTime_ALL" SG_ 893 CVC_HV_Cur_LoadComp 500;
BA_ "GenSigTimeoutTime_ALL" SG_ 896 VIN_Byte1 5000;
BA_ "GenSigTimeoutTime_ALL" SG_ 896 VIN_Byte2 5000;
BA_ "GenSigTimeoutTime_ALL" SG_ 896 VIN_Byte3 5000;
BA_ "GenSigTimeoutTime_ALL" SG_ 896 VIN_Byte4 5000;
BA_ "GenSigTimeoutTime_ALL" SG_ 896 VIN_Byte5 5000;
BA_ "GenSigTimeoutTime_ALL" SG_ 896 VIN_Byte6 5000;
BA_ "GenSigTimeoutTime_ALL" SG_ 896 VIN_Byte7 5000;
BA_ "InvalidValue" SG_ 919 ALIV_OBC_Temp "Fh";
BA_ "GenSigStartValue" SG_ 919 OBC_OBCTemp 40;
BA_ "GenSigStartValue" SG_ 919 OBC_InletTemp 40;
BA_ "InvalidValue" SG_ 1009 RollingCounter_0x3F1 "Fh";
BA_ "InvalidValue" SG_ 1110 Checksum_0x456 "null";
BA_ "GenSigTimeoutTime_ALL" SG_ 1110 Checksum_0x456 500;
BA_ "InvalidValue" SG_ 1110 Rolling_Counter_0x456 "Fh";
BA_ "GenSigTimeoutTime_ALL" SG_ 1110 Rolling_Counter_0x456 500;
BA_ "InvalidValue" SG_ 1110 BMS_CellLowVol_ERR "null";
BA_ "GenSigTimeoutTime_ALL" SG_ 1110 BMS_CellLowVol_ERR 500;
BA_ "InvalidValue" SG_ 1110 BMS_HVIL_Err "null";
BA_ "GenSigTimeoutTime_ALL" SG_ 1110 BMS_HVIL_Err 500;
BA_ "InvalidValue" SG_ 1110 BMS_PackInsu_ERR "null";
BA_ "GenSigTimeoutTime_ALL" SG_ 1110 BMS_PackInsu_ERR 500;
BA_ "InvalidValue" SG_ 1110 BMS_CellVoltDiff_ERR "null";
BA_ "GenSigTimeoutTime_ALL" SG_ 1110 BMS_CellVoltDiff_ERR 500;
BA_ "InvalidValue" SG_ 1110 BMS_ProbeTempDiff_ERR "null";
BA_ "GenSigTimeoutTime_ALL" SG_ 1110 BMS_ProbeTempDiff_ERR 500;
BA_ "InvalidValue" SG_ 1110 BMS_PackHighVol_ERR "null";
BA_ "GenSigTimeoutTime_ALL" SG_ 1110 BMS_PackHighVol_ERR 500;
BA_ "InvalidValue" SG_ 1110 BMS_PackLowVol_ERR "null";
BA_ "GenSigTimeoutTime_ALL" SG_ 1110 BMS_PackLowVol_ERR 500;
BA_ "InvalidValue" SG_ 1110 BMS_CellHighVol_ERR "null";
BA_ "GenSigTimeoutTime_ALL" SG_ 1110 BMS_CellHighVol_ERR 500;
BA_ "InvalidValue" SG_ 1110 BMS_ProbeHighTemp_ERR "null";
BA_ "GenSigTimeoutTime_ALL" SG_ 1110 BMS_ProbeHighTemp_ERR 500;
BA_ "InvalidValue" SG_ 1110 BMS_FuseStatus_ERR "null";
BA_ "GenSigTimeoutTime_ALL" SG_ 1110 BMS_FuseStatus_ERR 500;
BA_ "InvalidValue" SG_ 1110 BMS_PackOverCurr_ERR "null";
BA_ "GenSigTimeoutTime_ALL" SG_ 1110 BMS_PackOverCurr_ERR 500;
BA_ "InvalidValue" SG_ 1110 BMS_ProbeLowTemp_ERR "null";
BA_ "GenSigTimeoutTime_ALL" SG_ 1110 BMS_ProbeLowTemp_ERR 500;
BA_ "GenSigStartValue" SG_ 1118 EAC_CompBoardTemp 40;
BA_ "GenSigStartValue" SG_ 1118 EAC_CompIGBTTemp 40;
BA_ "GenSigStartValue" SG_ 1119 CVC_MotorWaterTemp 40;
BA_ "GenSigStartValue" SG_ 1117 EAC_HW_MasterVersion 1;
BA_ "GenSigStartValue" SG_ 1117 EAC_SW_bottomVersion 2;
BA_ "GenSigStartValue" SG_ 1117 EAC_SW_ApplicationVersion 7;
BA_ "GenSigStartValue" SG_ 1117 EAC_SW_year 24;
BA_ "GenSigStartValue" SG_ 1117 EAC_SW_month 6;
BA_ "GenSigStartValue" SG_ 1117 EAC_SW_day 18;
BA_ "GenSigTimeoutTime_ALL" SG_ 1145 EVCC_evt_ePP 500;
BA_ "InvalidValue" SG_ 1145 EVCC_evt_ePP "0h";
BA_ "GenSigTimeoutTime_ALL" SG_ 1145 EVCC_evt_eCP 500;
BA_ "InvalidValue" SG_ 1145 EVCC_evt_eCP "0h";
BA_ "GenSigTimeoutTime_ALL" SG_ 1145 EVCC_evt_eGunLck 500;
BA_ "InvalidValue" SG_ 1145 EVCC_evt_eGunLck "0h";
BA_ "GenSigTimeoutTime_ALL" SG_ 1145 EVCC_evt_eV2G 500;
BA_ "InvalidValue" SG_ 1145 EVCC_evt_eV2G "0h";
BA_ "GenSigTimeoutTime_ALL" SG_ 1145 EVCC_evt_eAcPlugTemp 500;
BA_ "InvalidValue" SG_ 1145 EVCC_evt_eAcPlugTemp "0h";
BA_ "GenSigTimeoutTime_ALL" SG_ 1145 EVCC_evt_eDcPlugTemp 500;
BA_ "InvalidValue" SG_ 1145 EVCC_evt_eDcPlugTemp "0h";
BA_ "GenSigTimeoutTime_ALL" SG_ 1145 EVCC_evt_eBmsLvl 500;
BA_ "InvalidValue" SG_ 1145 EVCC_evt_eBmsLvl "0h";
BA_ "GenSigTimeoutTime_ALL" SG_ 1145 EVCC_evt_eHLC 500;
BA_ "InvalidValue" SG_ 1145 EVCC_evt_eHLC "0h";
BA_ "GenSigTimeoutTime_ALL" SG_ 1145 EVCC_evt_iEvseDcPeakRpl 500;
BA_ "InvalidValue" SG_ 1145 EVCC_evt_iEvseDcPeakRpl "0h";
BA_ "GenSigTimeoutTime_ALL" SG_ 1145 EVCC_evt_eObcLvl 500;
BA_ "InvalidValue" SG_ 1145 EVCC_evt_eObcLvl "0h";
BA_ "GenSigTimeoutTime_ALL" SG_ 1145 EVCC_evt_ChgGunStkOpnd 500;
BA_ "InvalidValue" SG_ 1145 EVCC_evt_ChgGunStkOpnd "0h";
BA_ "GenSigTimeoutTime_ALL" SG_ 1145 EVCC_evt_ChgGunStkClsd 500;
BA_ "InvalidValue" SG_ 1145 EVCC_evt_ChgGunStkClsd "0h";
BA_ "GenSigTimeoutTime_ALL" SG_ 1145 EVCC_evt_AcTmpShortVcc 500;
BA_ "InvalidValue" SG_ 1145 EVCC_evt_AcTmpShortVcc "0h";
BA_ "GenSigTimeoutTime_ALL" SG_ 1145 EVCC_evt_PPShortVcc 500;
BA_ "InvalidValue" SG_ 1145 EVCC_evt_PPShortVcc "0h";
BA_ "GenSigTimeoutTime_ALL" SG_ 1145 EVCC_evt_PPShortGnd 500;
BA_ "InvalidValue" SG_ 1145 EVCC_evt_PPShortGnd "0h";
BA_ "GenSigTimeoutTime_ALL" SG_ 1145 EVCC_evt_DcPTmpShortGnd 500;
BA_ "InvalidValue" SG_ 1145 EVCC_evt_DcPTmpShortGnd "0h";
BA_ "GenSigTimeoutTime_ALL" SG_ 1145 EVCC_evt_eFCWelded 500;
BA_ "InvalidValue" SG_ 1145 EVCC_evt_eFCWelded "0h";
BA_ "GenSigTimeoutTime_ALL" SG_ 1145 EVCC_evt_eHVBusTemp 500;
BA_ "InvalidValue" SG_ 1145 EVCC_evt_eHVBusTemp "0h";
BA_ "GenSigTimeoutTime_ALL" SG_ 1145 EVCC_evt_ChgFlapHBShtGnd 500;
BA_ "InvalidValue" SG_ 1145 EVCC_evt_ChgFlapHBShtGnd "0h";
BA_ "GenSigTimeoutTime_ALL" SG_ 1145 EVCC_evt_ChgFlapHBShtBatt 500;
BA_ "InvalidValue" SG_ 1145 EVCC_evt_ChgFlapHBShtBatt "0h";
BA_ "GenSigTimeoutTime_ALL" SG_ 1145 EVCC_evt_ChgFlapHBOpnCir 500;
BA_ "InvalidValue" SG_ 1145 EVCC_evt_ChgFlapHBOpnCir "0h";
BA_ "GenSigTimeoutTime_ALL" SG_ 1145 EVCC_evt_ChgFlapHBOCVCrr 500;
BA_ "InvalidValue" SG_ 1145 EVCC_evt_ChgFlapHBOCVCrr "0h";
BA_ "GenSigTimeoutTime_ALL" SG_ 1145 EVCC_evt_ChgFlapHBOvTemp 500;
BA_ "InvalidValue" SG_ 1145 EVCC_evt_ChgFlapHBOvTemp "0h";
BA_ "GenSigTimeoutTime_ALL" SG_ 1145 EVCC_evt_DcPTmpShortVcc 500;
BA_ "InvalidValue" SG_ 1145 EVCC_evt_DcPTmpShortVcc "0h";
BA_ "GenSigTimeoutTime_ALL" SG_ 1145 EVCC_evt_AcTmpShortGnd 500;
BA_ "InvalidValue" SG_ 1145 EVCC_evt_AcTmpShortGnd "0h";
BA_ "GenSigTimeoutTime_ALL" SG_ 1145 EVCC_evt_eBmsInsu 500;
BA_ "InvalidValue" SG_ 1145 EVCC_evt_eBmsInsu "0h";
BA_ "GenSigTimeoutTime_ALL" SG_ 1145 EVCC_evt_eBmsHvil 500;
BA_ "InvalidValue" SG_ 1145 EVCC_evt_eBmsHvil "0h";
BA_ "GenSigTimeoutTime_ALL" SG_ 1145 EVCC_evt_eDcFcLvl1 500;
BA_ "InvalidValue" SG_ 1145 EVCC_evt_eDcFcLvl1 "0h";
BA_ "GenSigTimeoutTime_ALL" SG_ 1145 EVCC_evt_eDcFcLvl2 500;
BA_ "InvalidValue" SG_ 1145 EVCC_evt_eDcFcLvl2 "0h";
BA_ "GenSigTimeoutTime_ALL" SG_ 1145 EVCC_evt_eDcFcLvl3 500;
BA_ "InvalidValue" SG_ 1145 EVCC_evt_eDcFcLvl3 "0h";
BA_ "GenSigTimeoutTime_ALL" SG_ 1145 EVCC_evt_eEVSE 500;
BA_ "InvalidValue" SG_ 1145 EVCC_evt_eEVSE "0h";
BA_ "GenSigTimeoutTime_ALL" SG_ 1145 EVCC_evt_S2StkClsd 500;
BA_ "InvalidValue" SG_ 1145 EVCC_evt_S2StkClsd "0h";
BA_ "GenSigTimeoutTime_ALL" SG_ 1145 EVCC_evt_S2StkOpnd 500;
BA_ "InvalidValue" SG_ 1145 EVCC_evt_S2StkOpnd "0h";
BA_ "GenSigTimeoutTime_ALL" SG_ 1145 EVCC_evt_CpFreqFailr 500;
BA_ "InvalidValue" SG_ 1145 EVCC_evt_CpFreqFailr "0h";
BA_ "GenSigTimeoutTime_ALL" SG_ 1145 EVCC_evt_bPmicOV 500;
BA_ "InvalidValue" SG_ 1145 EVCC_evt_bPmicOV "0h";
BA_ "GenSigTimeoutTime_ALL" SG_ 1145 EVCC_evt_bPmicUV 500;
BA_ "InvalidValue" SG_ 1145 EVCC_evt_bPmicUV "0h";
BA_ "GenSigTimeoutTime_ALL" SG_ 1145 EVCC_evt_bMissCvcMsg 500;
BA_ "InvalidValue" SG_ 1145 EVCC_evt_bMissCvcMsg "0h";
BA_ "GenSigTimeoutTime_ALL" SG_ 1145 EVCC_evt_bMissBmsMsg 500;
BA_ "InvalidValue" SG_ 1145 EVCC_evt_bMissBmsMsg "0h";
BA_ "GenSigTimeoutTime_ALL" SG_ 1145 EVCC_evt_bMissPodMsg 500;
BA_ "InvalidValue" SG_ 1145 EVCC_evt_bMissPodMsg "0h";
BA_ "GenSigTimeoutTime_ALL" SG_ 1145 EVCC_evt_bMissBcmMsg 500;
BA_ "InvalidValue" SG_ 1145 EVCC_evt_bMissBcmMsg "0h";
BA_ "GenSigTimeoutTime_ALL" SG_ 1145 EVCC_evt_bE2eCvcMsg 500;
BA_ "InvalidValue" SG_ 1145 EVCC_evt_bE2eCvcMsg "0h";
BA_ "GenSigTimeoutTime_ALL" SG_ 1145 EVCC_evt_bE2eBmsMsg 500;
BA_ "InvalidValue" SG_ 1145 EVCC_evt_bE2eBmsMsg "0h";
BA_ "GenSigTimeoutTime_ALL" SG_ 1145 EVCC_evt_bE2ePodMsg 500;
BA_ "InvalidValue" SG_ 1145 EVCC_evt_bE2ePodMsg "0h";
BA_ "GenSigTimeoutTime_ALL" SG_ 1145 EVCC_evt_bE2eBcmMsg 500;
BA_ "InvalidValue" SG_ 1145 EVCC_evt_bE2eBcmMsg "0h";
BA_ "GenSigTimeoutTime_ALL" SG_ 1145 EVCC_evt_ChgGunHBOvTemp 500;
BA_ "InvalidValue" SG_ 1145 EVCC_evt_ChgGunHBOvTemp "0h";
BA_ "GenSigTimeoutTime_ALL" SG_ 1145 EVCC_evt_ChgGunHBOCVCrr 500;
BA_ "InvalidValue" SG_ 1145 EVCC_evt_ChgGunHBOCVCrr "0h";
BA_ "GenSigTimeoutTime_ALL" SG_ 1145 EVCC_evt_ChgGunHBOpnCir 500;
BA_ "InvalidValue" SG_ 1145 EVCC_evt_ChgGunHBOpnCir "0h";
BA_ "GenSigTimeoutTime_ALL" SG_ 1145 EVCC_evt_ChgGunHBShtBatt 500;
BA_ "InvalidValue" SG_ 1145 EVCC_evt_ChgGunHBShtBatt "0h";
BA_ "GenSigTimeoutTime_ALL" SG_ 1145 EVCC_evt_ChgGunHBShtGnd 500;
BA_ "InvalidValue" SG_ 1145 EVCC_evt_ChgGunHBShtGnd "0h";
BA_ "GenSigTimeoutTime_ALL" SG_ 1145 EVCC_evt_PreconditionFlt 500;
BA_ "InvalidValue" SG_ 1145 EVCC_evt_PreconditionFlt "0h";
BA_ "GenSigTimeoutTime_ALL" SG_ 1146 BMS_CellMaxSOC 5000;
BA_ "GenSigTimeoutTime_ALL" SG_ 1146 BMS_CellMinSOC 5000;
BA_ "GenSigTimeoutTime_ALL" SG_ 1146 BMS_CorrectedSOC 5000;
BA_ "GenSigTimeoutTime_ALL" SG_ 1146 BMS_PackSOCDiff 5000;
BA_ "InvalidValue" SG_ 1171 CHSKM_BMS_WarnMsg "null";
BA_ "GenSigTimeoutTime_ALL" SG_ 1171 CHSKM_BMS_WarnMsg 5000;
BA_ "GenSigSendType" SG_ 1171 CHSKM_BMS_WarnMsg 3;
BA_ "InvalidValue" SG_ 1171 ALV_BMS_WarnMsg "Fh";
BA_ "GenSigTimeoutTime_ALL" SG_ 1171 ALV_BMS_WarnMsg 5000;
BA_ "GenSigSendType" SG_ 1171 ALV_BMS_WarnMsg 3;
BA_ "InvalidValue" SG_ 1171 BMS_PackTempSts "null";
BA_ "GenSigTimeoutTime_ALL" SG_ 1171 BMS_PackTempSts 5000;
BA_ "GenSigSendType" SG_ 1171 BMS_PackTempSts 4;
BA_ "InvalidValue" SG_ 1171 BMS_ThermalRunaway "null";
BA_ "GenSigTimeoutTime_ALL" SG_ 1171 BMS_ThermalRunaway 5000;
BA_ "GenSigSendType" SG_ 1171 BMS_ThermalRunaway 4;
BA_ "InvalidValue" SG_ 1171 BMS_BatteryReplacement "null";
BA_ "GenSigTimeoutTime_ALL" SG_ 1171 BMS_BatteryReplacement 5000;
BA_ "GenSigSendType" SG_ 1171 BMS_BatteryReplacement 4;
BA_ "InvalidValue" SG_ 1171 BMS_Warning_PowerDegrade "null";
BA_ "GenSigTimeoutTime_ALL" SG_ 1171 BMS_Warning_PowerDegrade 5000;
BA_ "GenSigSendType" SG_ 1171 BMS_Warning_PowerDegrade 4;
BA_ "InvalidValue" SG_ 1171 BMS_Warning_DeltaSoC "null";
BA_ "GenSigTimeoutTime_ALL" SG_ 1171 BMS_Warning_DeltaSoC 5000;
BA_ "GenSigSendType" SG_ 1171 BMS_Warning_DeltaSoC 4;
BA_ "InvalidValue" SG_ 1171 BMS_Warning_HVILSts "null";
BA_ "GenSigTimeoutTime_ALL" SG_ 1171 BMS_Warning_HVILSts 5000;
BA_ "GenSigSendType" SG_ 1171 BMS_Warning_HVILSts 4;
BA_ "InvalidValue" SG_ 1171 BMS_Warning_Isolation "null";
BA_ "GenSigTimeoutTime_ALL" SG_ 1171 BMS_Warning_Isolation 5000;
BA_ "GenSigSendType" SG_ 1171 BMS_Warning_Isolation 4;
BA_ "InvalidValue" SG_ 1171 BMS_Warning_CoolantLeakage "null";
BA_ "GenSigTimeoutTime_ALL" SG_ 1171 BMS_Warning_CoolantLeakage 5000;
BA_ "GenSigSendType" SG_ 1171 BMS_Warning_CoolantLeakage 4;
BA_ "InvalidValue" SG_ 1171 BMS_MalfunctionSts "null";
BA_ "GenSigTimeoutTime_ALL" SG_ 1171 BMS_MalfunctionSts 5000;
BA_ "GenSigSendType" SG_ 1171 BMS_MalfunctionSts 4;
BA_ "InvalidValue" SG_ 1171 BMS_LowBattery "null";
BA_ "GenSigTimeoutTime_ALL" SG_ 1171 BMS_LowBattery 5000;
BA_ "GenSigSendType" SG_ 1171 BMS_LowBattery 4;
BA_ "InvalidValue" SG_ 1171 BMS_Warning_DeltaTemperature "null";
BA_ "GenSigTimeoutTime_ALL" SG_ 1171 BMS_Warning_DeltaTemperature 5000;
BA_ "GenSigSendType" SG_ 1171 BMS_Warning_DeltaTemperature 4;
BA_ "InvalidValue" SG_ 1171 BMS_Warning_BDUTemperatureSts "null";
BA_ "GenSigTimeoutTime_ALL" SG_ 1171 BMS_Warning_BDUTemperatureSts 5000;
BA_ "GenSigSendType" SG_ 1171 BMS_Warning_BDUTemperatureSts 4;
BA_ "GenSigSendType" SG_ 1171 BMS_Warning_Contactor_Aging 4;
BA_ "GenSigTimeoutTime_ALL" SG_ 1171 BMS_Warning_Contactor_Aging 5000;
BA_ "GenSigSendType" SG_ 1171 BMS_Reserved_signal4 4;
BA_ "InvalidValue" SG_ 1171 BMS_Reserved_signal4 "null";
BA_ "GenSigTimeoutTime_ALL" SG_ 1171 BMS_Reserved_signal4 5000;
BA_ "InvalidValue" SG_ 1171 BMS_Reserved_signal5 "null";
BA_ "GenSigTimeoutTime_ALL" SG_ 1171 BMS_Reserved_signal5 5000;
BA_ "GenSigSendType" SG_ 1171 BMS_Reserved_signal5 4;
BA_ "GenSigStartValue" SG_ 1184 BMS_CellT1 65;
BA_ "GenSigStartValue" SG_ 1184 BMS_CellT2 65;
BA_ "GenSigStartValue" SG_ 1184 BMS_CellT3 65;
BA_ "GenSigStartValue" SG_ 1184 BMS_CellT4 65;
BA_ "GenSigStartValue" SG_ 1184 BMS_CellT5 65;
BA_ "GenSigStartValue" SG_ 1184 BMS_CellT6 65;
BA_ "GenSigStartValue" SG_ 1184 BMS_CellT7 65;
BA_ "GenSigStartValue" SG_ 1184 BMS_CellT8 65;
BA_ "GenSigStartValue" SG_ 1188 BMS_CellT9 65;
BA_ "GenSigStartValue" SG_ 1188 BMS_CellT10 65;
BA_ "GenSigStartValue" SG_ 1188 BMS_CellT11 65;
BA_ "GenSigStartValue" SG_ 1188 BMS_CellT12 65;
BA_ "GenSigStartValue" SG_ 1188 BMS_CellT13 65;
BA_ "GenSigStartValue" SG_ 1188 BMS_CellT14 65;
BA_ "GenSigStartValue" SG_ 1188 BMS_CellT15 65;
BA_ "GenSigStartValue" SG_ 1188 BMS_CellT16 65;
BA_ "GenSigStartValue" SG_ 1189 BMS_CellT17 65;
BA_ "GenSigStartValue" SG_ 1189 BMS_CellT18 65;
BA_ "GenSigStartValue" SG_ 1189 BMS_CellT19 65;
BA_ "GenSigStartValue" SG_ 1189 BMS_CellT20 65;
BA_ "GenSigStartValue" SG_ 1189 BMS_CellT21 65;
BA_ "GenSigStartValue" SG_ 1189 BMS_CellT22 65;
BA_ "GenSigStartValue" SG_ 1189 BMS_CellT23 65;
BA_ "GenSigStartValue" SG_ 1189 BMS_CellT24 65;
BA_ "GenSigStartValue" SG_ 1190 BMS_CellT25 65;
BA_ "GenSigStartValue" SG_ 1190 BMS_CellT26 65;
BA_ "GenSigStartValue" SG_ 1190 BMS_CellT27 65;
BA_ "GenSigStartValue" SG_ 1190 BMS_CellT28 65;
BA_ "GenSigStartValue" SG_ 1190 BMS_CellT29 65;
BA_ "GenSigStartValue" SG_ 1190 BMS_CellT30 65;
BA_ "GenSigStartValue" SG_ 1190 BMS_CellT31 65;
BA_ "GenSigStartValue" SG_ 1190 BMS_CellT32 65;
BA_ "GenSigStartValue" SG_ 1191 BMS_CellT33 65;
BA_ "GenSigStartValue" SG_ 1191 BMS_CellT34 65;
BA_ "GenSigStartValue" SG_ 1191 BMS_CellT35 65;
BA_ "GenSigStartValue" SG_ 1191 BMS_CellT36 65;
BA_ "GenSigStartValue" SG_ 1226 BMS_BPS_pressureValue 50;
BA_ "GenSigStartValue" SG_ 1226 BMS_CVS_Temperature 50;
BA_ "GenSigStartValue" SG_ 1227 BMS_BalArea_Temperature1 50;
BA_ "GenSigStartValue" SG_ 1227 BMS_BalArea_Temperature2 50;
BA_ "GenSigStartValue" SG_ 1227 BMS_BalArea_Temperature3 50;
BA_ "GenSigStartValue" SG_ 1227 BMS_BalArea_Temperature4 50;
BA_ "GenSigStartValue" SG_ 1227 BMS_BalArea_Temperature5 50;
BA_ "GenSigStartValue" SG_ 1227 BMS_BalArea_Temperature6 50;
BA_ "GenSigStartValue" SG_ 1227 BMS_BalArea_Temperature7 50;
BA_ "GenSigStartValue" SG_ 1227 BMS_BalArea_Temperature8 50;
BA_ "GenSigTimeoutTime_ALL" SG_ 1282 CVC_srcNodeID 2000;
BA_ "InvalidValue" SG_ 1282 CVC_srcNodeID "FFh";
BA_ "GenSigTimeoutTime_ALL" SG_ 1282 CVC_CtrlBitVector 2000;
BA_ "InvalidValue" SG_ 1282 CVC_CtrlBitVector "null";
BA_ "GenSigStartValue" SG_ 1282 CVC_usrData0 255;
BA_ "GenSigTimeoutTime_ALL" SG_ 1282 CVC_usrData0 2000;
BA_ "InvalidValue" SG_ 1282 CVC_usrData0 "null";
BA_ "GenSigStartValue" SG_ 1282 CVC_usrData1 255;
BA_ "GenSigTimeoutTime_ALL" SG_ 1282 CVC_usrData1 2000;
BA_ "InvalidValue" SG_ 1282 CVC_usrData1 "null";
BA_ "GenSigStartValue" SG_ 1282 CVC_usrData2 255;
BA_ "GenSigTimeoutTime_ALL" SG_ 1282 CVC_usrData2 2000;
BA_ "InvalidValue" SG_ 1282 CVC_usrData2 "null";
BA_ "GenSigStartValue" SG_ 1282 CVC_usrData3 255;
BA_ "GenSigTimeoutTime_ALL" SG_ 1282 CVC_usrData3 2000;
BA_ "InvalidValue" SG_ 1282 CVC_usrData3 "null";
BA_ "GenSigStartValue" SG_ 1282 CVC_usrData4 255;
BA_ "GenSigTimeoutTime_ALL" SG_ 1282 CVC_usrData4 2000;
BA_ "InvalidValue" SG_ 1282 CVC_usrData4 "null";
BA_ "GenSigStartValue" SG_ 1282 CVC_usrData5 255;
BA_ "GenSigTimeoutTime_ALL" SG_ 1282 CVC_usrData5 2000;
BA_ "InvalidValue" SG_ 1282 CVC_usrData5 "null";
BA_ "InvalidValue" SG_ 1299 BMS_srcNodeID "FFh";
BA_ "GenSigTimeoutTime_ALL" SG_ 1299 BMS_srcNodeID 2000;
BA_ "InvalidValue" SG_ 1299 BMS_CtrlBitVector "null";
BA_ "GenSigTimeoutTime_ALL" SG_ 1299 BMS_CtrlBitVector 2000;
BA_ "InvalidValue" SG_ 1299 BMS_usrData0 "null";
BA_ "GenSigTimeoutTime_ALL" SG_ 1299 BMS_usrData0 2000;
BA_ "GenSigStartValue" SG_ 1299 BMS_usrData0 255;
BA_ "InvalidValue" SG_ 1299 BMS_usrData1 "null";
BA_ "GenSigTimeoutTime_ALL" SG_ 1299 BMS_usrData1 2000;
BA_ "GenSigStartValue" SG_ 1299 BMS_usrData1 255;
BA_ "InvalidValue" SG_ 1299 BMS_usrData2 "null";
BA_ "GenSigTimeoutTime_ALL" SG_ 1299 BMS_usrData2 2000;
BA_ "GenSigStartValue" SG_ 1299 BMS_usrData2 255;
BA_ "InvalidValue" SG_ 1299 BMS_usrData3 "null";
BA_ "GenSigTimeoutTime_ALL" SG_ 1299 BMS_usrData3 2000;
BA_ "GenSigStartValue" SG_ 1299 BMS_usrData3 255;
BA_ "InvalidValue" SG_ 1299 BMS_usrData4 "null";
BA_ "GenSigTimeoutTime_ALL" SG_ 1299 BMS_usrData4 2000;
BA_ "GenSigStartValue" SG_ 1299 BMS_usrData4 255;
BA_ "InvalidValue" SG_ 1299 BMS_usrData5 "null";
BA_ "GenSigTimeoutTime_ALL" SG_ 1299 BMS_usrData5 2000;
BA_ "GenSigStartValue" SG_ 1299 BMS_usrData5 255;
BA_ "InvalidValue" SG_ 1311 EVCC_srcNodeID "FFh";
BA_ "GenSigTimeoutTime_ALL" SG_ 1311 EVCC_srcNodeID 2000;
BA_ "InvalidValue" SG_ 1311 EVCC_CtrlBitVector "null";
BA_ "GenSigTimeoutTime_ALL" SG_ 1311 EVCC_CtrlBitVector 2000;
BA_ "GenSigStartValue" SG_ 1311 EVCC_usrData0 255;
BA_ "InvalidValue" SG_ 1311 EVCC_usrData0 "null";
BA_ "GenSigTimeoutTime_ALL" SG_ 1311 EVCC_usrData0 2000;
BA_ "GenSigStartValue" SG_ 1311 EVCC_usrData1 255;
BA_ "InvalidValue" SG_ 1311 EVCC_usrData1 "null";
BA_ "GenSigTimeoutTime_ALL" SG_ 1311 EVCC_usrData1 2000;
BA_ "GenSigStartValue" SG_ 1311 EVCC_usrData2 255;
BA_ "InvalidValue" SG_ 1311 EVCC_usrData2 "null";
BA_ "GenSigTimeoutTime_ALL" SG_ 1311 EVCC_usrData2 2000;
BA_ "GenSigStartValue" SG_ 1311 EVCC_usrData3 255;
BA_ "InvalidValue" SG_ 1311 EVCC_usrData3 "null";
BA_ "GenSigTimeoutTime_ALL" SG_ 1311 EVCC_usrData3 2000;
BA_ "GenSigStartValue" SG_ 1311 EVCC_usrData4 255;
BA_ "InvalidValue" SG_ 1311 EVCC_usrData4 "null";
BA_ "GenSigTimeoutTime_ALL" SG_ 1311 EVCC_usrData4 2000;
BA_ "GenSigStartValue" SG_ 1311 EVCC_usrData5 255;
BA_ "InvalidValue" SG_ 1311 EVCC_usrData5 "null";
BA_ "GenSigTimeoutTime_ALL" SG_ 1311 EVCC_usrData5 2000;
BA_ "GenSigSendType" SG_ 1545 CCU_DiagRespData0 7;
BA_ "GenSigSendType" SG_ 1545 CCU_DiagRespData1 7;
BA_ "GenSigSendType" SG_ 1545 CCU_DiagRespData2 7;
BA_ "GenSigSendType" SG_ 1545 CCU_DiagRespData3 7;
BA_ "GenSigSendType" SG_ 1545 CCU_DiagRespData4 7;
BA_ "GenSigSendType" SG_ 1545 CCU_DiagRespData5 7;
BA_ "GenSigSendType" SG_ 1545 CCU_DiagRespData6 7;
BA_ "GenSigSendType" SG_ 1545 CCU_DiagRespData7 7;
BA_ "InvalidValue" SG_ 1555 BMS_DiagRespData0 "null";
BA_ "GenSigSendType" SG_ 1555 BMS_DiagRespData0 7;
BA_ "InvalidValue" SG_ 1555 BMS_DiagRespData1 "null";
BA_ "GenSigSendType" SG_ 1555 BMS_DiagRespData1 7;
BA_ "InvalidValue" SG_ 1555 BMS_DiagRespData2 "null";
BA_ "GenSigSendType" SG_ 1555 BMS_DiagRespData2 7;
BA_ "InvalidValue" SG_ 1555 BMS_DiagRespData3 "null";
BA_ "GenSigSendType" SG_ 1555 BMS_DiagRespData3 7;
BA_ "InvalidValue" SG_ 1555 BMS_DiagRespData4 "null";
BA_ "GenSigSendType" SG_ 1555 BMS_DiagRespData4 7;
BA_ "InvalidValue" SG_ 1555 BMS_DiagRespData5 "null";
BA_ "GenSigSendType" SG_ 1555 BMS_DiagRespData5 7;
BA_ "InvalidValue" SG_ 1555 BMS_DiagRespData6 "null";
BA_ "GenSigSendType" SG_ 1555 BMS_DiagRespData6 7;
BA_ "InvalidValue" SG_ 1555 BMS_DiagRespData7 "null";
BA_ "GenSigSendType" SG_ 1555 BMS_DiagRespData7 7;
BA_ "InvalidValue" SG_ 1606 PTC_DiagRespData0 "null";
BA_ "GenSigSendType" SG_ 1606 PTC_DiagRespData0 7;
BA_ "InvalidValue" SG_ 1606 PTC_DiagRespData1 "null";
BA_ "GenSigSendType" SG_ 1606 PTC_DiagRespData1 7;
BA_ "InvalidValue" SG_ 1606 PTC_DiagRespData2 "null";
BA_ "GenSigSendType" SG_ 1606 PTC_DiagRespData2 7;
BA_ "InvalidValue" SG_ 1606 PTC_DiagRespData3 "null";
BA_ "GenSigSendType" SG_ 1606 PTC_DiagRespData3 7;
BA_ "InvalidValue" SG_ 1606 PTC_DiagRespData4 "null";
BA_ "GenSigSendType" SG_ 1606 PTC_DiagRespData4 7;
BA_ "InvalidValue" SG_ 1606 PTC_DiagRespData5 "null";
BA_ "GenSigSendType" SG_ 1606 PTC_DiagRespData5 7;
BA_ "InvalidValue" SG_ 1606 PTC_DiagRespData6 "null";
BA_ "GenSigSendType" SG_ 1606 PTC_DiagRespData6 7;
BA_ "InvalidValue" SG_ 1606 PTC_DiagRespData7 "null";
BA_ "GenSigSendType" SG_ 1606 PTC_DiagRespData7 7;
BA_ "GenSigSendType" SG_ 1563 FMCU_DiagRespData0 7;
BA_ "GenSigSendType" SG_ 1563 FMCU_DiagRespData1 7;
BA_ "GenSigSendType" SG_ 1563 FMCU_DiagRespData2 7;
BA_ "GenSigSendType" SG_ 1563 FMCU_DiagRespData3 7;
BA_ "GenSigSendType" SG_ 1563 FMCU_DiagRespData4 7;
BA_ "GenSigSendType" SG_ 1563 FMCU_DiagRespData5 7;
BA_ "GenSigSendType" SG_ 1563 FMCU_DiagRespData6 7;
BA_ "GenSigSendType" SG_ 1563 FMCU_DiagRespData7 7;
BA_ "GenSigSendType" SG_ 1567 EVCC_DiagRespData0 7;
BA_ "GenSigSendType" SG_ 1567 EVCC_DiagRespData1 7;
BA_ "GenSigSendType" SG_ 1567 EVCC_DiagRespData2 7;
BA_ "GenSigSendType" SG_ 1567 EVCC_DiagRespData3 7;
BA_ "GenSigSendType" SG_ 1567 EVCC_DiagRespData4 7;
BA_ "GenSigSendType" SG_ 1567 EVCC_DiagRespData5 7;
BA_ "GenSigSendType" SG_ 1567 EVCC_DiagRespData6 7;
BA_ "GenSigSendType" SG_ 1567 EVCC_DiagRespData7 7;
BA_ "GenSigSendType" SG_ 1597 PDU_DiagRespData0 7;
BA_ "GenSigSendType" SG_ 1597 PDU_DiagRespData1 7;
BA_ "GenSigSendType" SG_ 1597 PDU_DiagRespData2 7;
BA_ "GenSigSendType" SG_ 1597 PDU_DiagRespData3 7;
BA_ "GenSigSendType" SG_ 1597 PDU_DiagRespData4 7;
BA_ "GenSigSendType" SG_ 1597 PDU_DiagRespData5 7;
BA_ "GenSigSendType" SG_ 1597 PDU_DiagRespData6 7;
BA_ "GenSigSendType" SG_ 1597 PDU_DiagRespData7 7;
BA_ "GenSigSendType" SG_ 1598 PDU_OBC_DiagRespData0 7;
BA_ "GenSigSendType" SG_ 1598 PDU_OBC_DiagRespData1 7;
BA_ "GenSigSendType" SG_ 1598 PDU_OBC_DiagRespData2 7;
BA_ "GenSigSendType" SG_ 1598 PDU_OBC_DiagRespData3 7;
BA_ "GenSigSendType" SG_ 1598 PDU_OBC_DiagRespData4 7;
BA_ "GenSigSendType" SG_ 1598 PDU_OBC_DiagRespData5 7;
BA_ "GenSigSendType" SG_ 1598 PDU_OBC_DiagRespData6 7;
BA_ "GenSigSendType" SG_ 1598 PDU_OBC_DiagRespData7 7;
BA_ "GenSigSendType" SG_ 1726 PDU_OBC_DiagReqData0 7;
BA_ "GenSigSendType" SG_ 1726 PDU_OBC_DiagReqData1 7;
BA_ "GenSigSendType" SG_ 1726 PDU_OBC_DiagReqData2 7;
BA_ "GenSigSendType" SG_ 1726 PDU_OBC_DiagReqData3 7;
BA_ "GenSigSendType" SG_ 1726 PDU_OBC_DiagReqData4 7;
BA_ "GenSigSendType" SG_ 1726 PDU_OBC_DiagReqData5 7;
BA_ "GenSigSendType" SG_ 1726 PDU_OBC_DiagReqData6 7;
BA_ "GenSigSendType" SG_ 1726 PDU_OBC_DiagReqData7 7;
BA_ "GenSigSendType" SG_ 1673 CCU_DiagReqData0 7;
BA_ "GenSigSendType" SG_ 1673 CCU_DiagReqData1 7;
BA_ "GenSigSendType" SG_ 1673 CCU_DiagReqData2 7;
BA_ "GenSigSendType" SG_ 1673 CCU_DiagReqData3 7;
BA_ "GenSigSendType" SG_ 1673 CCU_DiagReqData4 7;
BA_ "GenSigSendType" SG_ 1673 CCU_DiagReqData5 7;
BA_ "GenSigSendType" SG_ 1673 CCU_DiagReqData6 7;
BA_ "GenSigSendType" SG_ 1673 CCU_DiagReqData7 7;
BA_ "GenSigSendType" SG_ 1683 BMS_DiagReqData0 7;
BA_ "GenSigSendType" SG_ 1683 BMS_DiagReqData1 7;
BA_ "GenSigSendType" SG_ 1683 BMS_DiagReqData2 7;
BA_ "GenSigSendType" SG_ 1683 BMS_DiagReqData3 7;
BA_ "GenSigSendType" SG_ 1683 BMS_DiagReqData4 7;
BA_ "GenSigSendType" SG_ 1683 BMS_DiagReqData5 7;
BA_ "GenSigSendType" SG_ 1683 BMS_DiagReqData6 7;
BA_ "GenSigSendType" SG_ 1683 BMS_DiagReqData7 7;
BA_ "GenSigSendType" SG_ 1734 PTC_DiagReqData0 7;
BA_ "GenSigSendType" SG_ 1734 PTC_DiagReqData1 7;
BA_ "GenSigSendType" SG_ 1734 PTC_DiagReqData2 7;
BA_ "GenSigSendType" SG_ 1734 PTC_DiagReqData3 7;
BA_ "GenSigSendType" SG_ 1734 PTC_DiagReqData4 7;
BA_ "GenSigSendType" SG_ 1734 PTC_DiagReqData5 7;
BA_ "GenSigSendType" SG_ 1734 PTC_DiagReqData6 7;
BA_ "GenSigSendType" SG_ 1734 PTC_DiagReqData7 7;
BA_ "GenSigSendType" SG_ 1691 FMCU_DiagReqData0 7;
BA_ "GenSigSendType" SG_ 1691 FMCU_DiagReqData1 7;
BA_ "GenSigSendType" SG_ 1691 FMCU_DiagReqData2 7;
BA_ "GenSigSendType" SG_ 1691 FMCU_DiagReqData3 7;
BA_ "GenSigSendType" SG_ 1691 FMCU_DiagReqData4 7;
BA_ "GenSigSendType" SG_ 1691 FMCU_DiagReqData5 7;
BA_ "GenSigSendType" SG_ 1691 FMCU_DiagReqData6 7;
BA_ "GenSigSendType" SG_ 1691 FMCU_DiagReqData7 7;
BA_ "GenSigSendType" SG_ 1695 EVCC_DiagReqData0 7;
BA_ "GenSigSendType" SG_ 1695 EVCC_DiagReqData1 7;
BA_ "GenSigSendType" SG_ 1695 EVCC_DiagReqData2 7;
BA_ "GenSigSendType" SG_ 1695 EVCC_DiagReqData3 7;
BA_ "GenSigSendType" SG_ 1695 EVCC_DiagReqData4 7;
BA_ "GenSigSendType" SG_ 1695 EVCC_DiagReqData5 7;
BA_ "GenSigSendType" SG_ 1695 EVCC_DiagReqData6 7;
BA_ "GenSigSendType" SG_ 1695 EVCC_DiagReqData7 7;
BA_ "GenSigSendType" SG_ 1725 PDU_DiagReqData0 7;
BA_ "GenSigSendType" SG_ 1725 PDU_DiagReqData1 7;
BA_ "GenSigSendType" SG_ 1725 PDU_DiagReqData2 7;
BA_ "GenSigSendType" SG_ 1725 PDU_DiagReqData3 7;
BA_ "GenSigSendType" SG_ 1725 PDU_DiagReqData4 7;
BA_ "GenSigSendType" SG_ 1725 PDU_DiagReqData5 7;
BA_ "GenSigSendType" SG_ 1725 PDU_DiagReqData6 7;
BA_ "GenSigSendType" SG_ 1725 PDU_DiagReqData7 7;
BA_ "GenSigSendType" SG_ 1791 DiagReqAllEcuData0 7;
BA_ "GenSigSendType" SG_ 1791 DiagReqAllEcuData1 7;
BA_ "GenSigSendType" SG_ 1791 DiagReqAllEcuData2 7;
BA_ "GenSigSendType" SG_ 1791 DiagReqAllEcuData3 7;
BA_ "GenSigSendType" SG_ 1791 DiagReqAllEcuData4 7;
BA_ "GenSigSendType" SG_ 1791 DiagReqAllEcuData5 7;
BA_ "GenSigSendType" SG_ 1791 DiagReqAllEcuData6 7;
BA_ "GenSigSendType" SG_ 1791 DiagReqAllEcuData7 7;
BA_ "InvalidValue" SG_ 1939 BMS_XCPTxData "null";
BA_ "GenSigSendType" SG_ 1939 BMS_XCPTxData 7;
BA_ "InvalidValue" SG_ 1986 BMS_XCPRxData "null";
BA_ "GenSigSendType" SG_ 1986 BMS_XCPRxData 7;
VAL_ 820 BMS_ErrorCategory_CAT0 0 "CATOK" 1 "CATFailure" ;
VAL_ 820 BMS_ErrorCategory_CAT1 0 "CATOK" 1 "CATFailure" ;
VAL_ 820 BMS_ErrorCategory_CAT2 0 "CATOK" 1 "CATFailure" ;
VAL_ 820 BMS_ErrorCategory_CAT3 0 "CATOK" 1 "CATFailure" ;
VAL_ 820 BMS_ErrorCategory_CAT4 0 "CATOK" 1 "CATFailure" ;
VAL_ 820 BMS_ErrorCategory_CAT5 0 "CATOK" 1 "CATFailure" ;
VAL_ 820 BMS_ErrorCategory_CAT6 0 "CATOK" 1 "CATFailure" ;
VAL_ 820 BMS_ErrorCategory_CAT7 0 "CATOK" 1 "CATFailure" ;
VAL_ 820 BMS_ErrorCategory_CAT8 0 "CATOK" 1 "CATFailure" ;
VAL_ 821 CCU_mode_motor_cfm 0 "Success" 1 "Failure" 2 "Not responding" ;
VAL_ 821 CCU_temp_motor_cfm 0 "Success" 1 "Failure" 2 "Not responding" ;
VAL_ 821 CCU_fresh_motor_cfm 0 "Success" 1 "Failure" 2 "Not responding" ;
VAL_ 843 EVSE_DC_Stt 0 "Init" 1 "EVSE not ready" 2 "EVSE ready" 3 "EVSE shutdown" 4 "EVSE utility interrupt event" 5 "EVSE isolation monitoring active" 6 "EVSE emergency shutdown" 7 "EVSE Malfunction" 8 "Reserved by ISO/IEC for future use" 9 "Reserved by ISO/IEC for future use" 10 "Reserved by ISO/IEC for future use" 11 "Reserved by ISO/IEC for future use" 12 "Reserved by ISO/IEC for future use" ;
VAL_ 843 EVSE_CtrlPilot_STS 0 "A" 1 "B" 2 "C" 3 "D" 4 "E" 5 "F" 6 "Error" ;
VAL_ 843 EVSE_IsolationLvl 0 "Init" 1 "Invalid" 2 "Valid" 3 "Warning" 4 "Fault" 5 "No IMD" ;
VAL_ 843 EVSE_VehChgComm_STAT 0 "None" 1 "Scc_StateMachineStatus_Initialized" 2 "SLAC" 3 "WaitForIP" 4 "SECCDiscoveryProtocol" 5 "TLConnection" 6 "SupportedAppProtocol" 7 "SessionSetup" 8 "ServiceDiscovery" 9 "ServiceDetail" 10 "PaymentServiceSelection" 11 "CertificateInstallation" 12 "CertificateUpdate" 13 "PaymentDetails" 14 "Authorization" 15 "ChargeParameterDiscovery" 16 "PowerDelivery" 17 "MeteringReceipt" 18 "ChargingStatus (AC Charging)" 19 "CableCheck" 20 "PreCharge" 21 "CurrentDemand" 22 "WeldingDetection" 23 "Scc_StateMachineStatus_SessionStop" 24 "StopCommunicationSession" 25 "Finished" 26 "Error_WaitingForRetry" 27 "Error_Stopped" ;
VAL_ 843 EVSE_ResponseCode 0 "Init" 1 "No error" 2 "No error, new session established" 3 "No error, old session joined" 4 "No error, certificate expires soon" 5 "Error" 6 "Sequence error" 7 "Error, service ID invalid" 8 "Error, unknown session" 9 "Error, service selection invalid" 10 "Error, payment selection invalid" 11 "Error, Certificate Expired" 12 "Error, Signature Error" 13 "Error, No Certificate Available" 14 "Error, Cert Chain Error" 15 "Error, Challenge Invalid" 16 "Error, Contract Canceled" 17 "Error, Wrong Charge Parameter" 18 "Error, Power Delivery Not Applied" 19 "Error, Tariff Selection Invalid" 20 "Error, Charging Profile Invalid" 21 "Error, Metering Signature Not Valid" 22 "Error, No Charge Service Selected" 23 "Error, Wrong Energy Transfer Mode" 24 "Error, Contactor Error" 25 "Error, Certificate Not Allowed At This EVSE" 26 "Error, Certificate Revoked" ;
VAL_ 845 EVCC_STAT_BrakeSts 0 "Not Pressed" 1 "Pressed" 2 "Reversed" 3 "Invalid" ;
VAL_ 845 EVCC_Req_InsulationMon 0 "ON" 1 "OFF" 2 "Reserved" 3 "Invalid" ;
VAL_ 845 EVCC_PnC_Contract_STS 0 "Not available" 1 "Installed" 2 "Error" 3 "Invalid" ;
VAL_ 845 EVCC_FcContactor_Req 0 "Open both" 1 "Close both" 2 "Open negative, close positive" 3 "Close negative, open positive" 4 "Invalid" ;
VAL_ 845 EVCC_FcContactor_Sts 0 "Contactor normal" 1 "Both contactors welded" 2 "Negative contactor welded" 3 "Positive contactor welded" 4 "Invalid" ;
VAL_ 850 EVCC_SOV2_ControlStatus 0 "Invalid" 1 "OFF" 2 "ON" 3 "Fault" ;
VAL_ 850 EVCC_SOV1_ControlStatus 0 "Invalid" 1 "OFF" 2 "ON" 3 "Fault" ;
VAL_ 850 EVCC_MotorWaterPump_Status 0 "Invalid" 1 "OFF" 2 "Normal operation" 3 "Dry" 4 "Fault" ;
VAL_ 850 EVCC_BatteryWaterPump_Status 0 "Invalid" 1 "OFF" 2 "Normal operation" 3 "Dry" 4 "Over & Under Voltage" 5 "Over Heat" ;
VAL_ 850 EVCC_PTC_OnOff_Status 0 "Invalid" 1 "OFF" 2 "ON" 3 "Fault" ;
VAL_ 851 EVCC_EAC_OnOff_Status 0 "Invalid" 1 "OFF" 2 "ON" 3 "Fault" ;
VAL_ 851 EVCC_DualPressureSwitch_Status 0 "Invalid" 1 "OFF" 2 "ON" 3 "Fault" ;
VAL_ 851 EVCC_MainRelay_OnOff_Status 0 "Invalid" 1 "OFF" 2 "ON" 3 "Fault" ;
VAL_ 851 EVCC_ElectricFan_OnOff_Sts 0 "Invalid" 1 "OFF" 2 "ON" 3 "Fault" ;
VAL_ 851 EVCC_CL15_Status 0 "Invalid" 1 "OFF" 2 "ON" 3 "Fault" ;
VAL_ 851 EVCC_PGearPressSignal1_Status 0 "Invalid" 1 "OFF" 2 "ON" 3 "Fault" ;
VAL_ 851 EVCC_PGearStsLight_OnOff_Sts 0 "Invalid" 1 "OFF" 2 "ON" 3 "Fault" ;
VAL_ 851 EVCC_ExpValve_OnOff_Status 0 "Invalid" 1 "OFF" 2 "ON" 3 "Fault" ;
VAL_ 851 EVCC_EACPTCHVIL_Status 0 "Normal" 1 "Error" 2 "Reserved" 3 "Invalid" ;
VAL_ 852 CVC_BatteryWaterPump_OnOff_Req 0 "Invalid" 1 "OFF" 2 "ON" ;
VAL_ 852 CVC_EAC_OnOff_Req 0 "Invalid" 1 "OFF" 2 "ON" ;
VAL_ 852 CVC_PGearStatusLight_OnOff_Req 0 "Invalid" 1 "OFF" 2 "ON" ;
VAL_ 852 CVC_PTC_OnOff_Req 0 "Invalid" 1 "OFF" 2 "ON" ;
VAL_ 852 CVC_ExpValve_OnOff_Req 0 "Invalid" 1 "OFF" 2 "ON" ;
VAL_ 852 CVC_SOV2_ControlReq 0 "Invalid" 1 "OFF" 2 "ON" ;
VAL_ 853 CVC_SOV1_ControlReq 0 "Invalid" 1 "OFF" 2 "ON" ;
VAL_ 853 CVC_MotorWaterPump_OnOff_Req 0 "Invalid" 1 "OFF" 2 "ON" ;
VAL_ 853 CVC_MainRelay_OnOff_Req 0 "Invalid" 1 "OFF" 2 "ON" ;
VAL_ 853 CVC_ElectricFan_Enable 0 "Invalid" 1 "OFF" 2 "ON" ;
VAL_ 858 CVC_LockCP_Req 0 "No action" 1 "Lock" 2 "Unlock" 3 "Invalid" ;
VAL_ 859 OBC_Req 0 "OBC OFF" 1 "OBC ON NORMAL" 2 "OBC ON VOLTAGE" 3 "Invalid" ;
VAL_ 862 CVC_VehLock_STS 0 "Unlocked" 1 "Locked" 2 "Reserved" 3 "Invalid" ;
VAL_ 862 CVC_VehChgAllow 0 "Forbid charging" 1 "Not allow, waiting" 2 "Allow charging" 3 "Invalid" ;
VAL_ 862 Re_InitCharging_Req 0 "Forbid" 1 "Allow" 2 "Reserved" 3 "Invalid" ;
VAL_ 862 CVC_GunUnlock_Req 0 "No action" 1 "Lock" 2 "Unlock" 3 "Invalid" ;
VAL_ 862 CVC_StopChg_Req 0 "No request" 1 "Request" ;
VAL_ 872 FMCU_MCUinternalFault 1 "Fault" 0 "Normal" ;
VAL_ 872 FMCU_PhaseOverCurrentSWFault 0 "Normal" 1 "Error" ;
VAL_ 872 FMCU_MCUOverTempFault 0 "Normal" 1 "Error" ;
VAL_ 872 FMCU_MCUOverTempAlarm 0 "Normal" 1 "Error" ;
VAL_ 872 FMCU_MotTempSenFault 0 "Normal" 1 "Error" ;
VAL_ 872 FMCU_MotTempSenWFault 0 "Normal" 1 "Error" ;
VAL_ 872 FMCU_MotTempSenVFault 0 "Normal" 1 "Error" ;
VAL_ 872 FMCU_MotTempSenUFault 0 "Normal" 1 "Error" ;
VAL_ 872 FMCU_MotOverTempFault 0 "Normal" 1 "Error" ;
VAL_ 872 FMCU_MotOverTempAlarm 0 "Normal" 1 "Error" ;
VAL_ 872 FMCU_MCUHVUnderVoltageFault 0 "Normal" 1 "Error" ;
VAL_ 872 FMCU_MCUHVUnderVoltageAlarm 0 "Normal" 1 "Error" ;
VAL_ 872 FMCU_MCUHVOverVoltageFault 0 "Normal" 1 "Error" ;
VAL_ 872 FMCU_MCUHVOverVoltageAlarm 0 "Normal" 1 "Error" ;
VAL_ 872 FMCU_MCUCurrentSenWFault 0 "Normal" 1 "Error" ;
VAL_ 872 FMCU_MCUCurrentSenVFault 0 "Normal" 1 "Error" ;
VAL_ 872 FMCU_MCUCurrentSenUFault 0 "Normal" 1 "Error" ;
VAL_ 872 FMCU_PhaseOverCurrentHWFault 0 "Normal" 1 "Error" ;
VAL_ 872 FMCU_MotOverFault 0 "Normal" 1 "Error" ;
VAL_ 872 FMCU_MotOverAlarm 0 "Normal" 1 "Error" ;
VAL_ 872 FMCU_12VUnderVoltageAlarm 0 "Normal" 1 "Error" ;
VAL_ 872 FMCU_12VOverVoltageAlarm 0 "Normal" 1 "Error" ;
VAL_ 872 FMCU_MCUHVSensorFault 0 "Normal" 1 "Error" ;
VAL_ 872 FMCU_MCUDisChgFault 0 "Normal" 1 "Error" ;
VAL_ 872 FMCU_MotBlockedFault 0 "Normal" 1 "Error" ;
VAL_ 872 FMCU_MotRotSenFault 0 "Normal" 1 "Error" ;
VAL_ 872 FMCU_BMSLostFault 0 "Normal" 1 "Error" ;
VAL_ 872 FMCU_CVCLostFault 0 "Normal" 1 "Error" ;
VAL_ 872 FMCU_CANBusoffFault 0 "Normal" 1 "Error" ;
VAL_ 872 FMCU_IGBTFault 0 "Normal" 1 "Error" ;
VAL_ 872 FMCU_MCUCurrentSenWZeroFault 0 "Normal" 1 "Error" ;
VAL_ 872 FMCU_MCUCurrentSenVZeroFault 0 "Normal" 1 "Error" ;
VAL_ 872 FMCU_MCUCurrentSenUZeroFault 0 "Normal" 1 "Error" ;
VAL_ 872 FMCU_MCUTempSenWFault 0 "Normal" 1 "Error" ;
VAL_ 872 FMCU_MCUTempSenVFault 0 "Normal" 1 "Error" ;
VAL_ 872 FMCU_MCUTempSenUFault 0 "Normal" 1 "Error" ;
VAL_ 872 FMCU_InitMode 0 "Normal" 1 "Error" ;
VAL_ 873 FMCU_StsActiveDischg 0 "No Active Discharge" 1 "Active Discharge" 2 "Failed Active Discharge" 3 "Finished Active Discharge" ;
VAL_ 873 FMCU_TBOX_ModeMotorDrv 1 "DispateEnergy" 2 "GenerateEnergy" 3 "Shutdown" 4 "Ready" 5 "Reserved" ;
VAL_ 876 AC_PTC_Enable 0 "Disable" 1 "Enable" ;
VAL_ 884 PTC_CrtSts 0 "Standby" 1 "Power working mode" 2 "Fault" 3 "Gear working mode" ;
VAL_ 884 PTC_HVIntlkFlt 0 "Normol" 1 "Fault" ;
VAL_ 884 PTC_ComLost_ECC 0 "Normol" 1 "Fault" ;
VAL_ 884 PTC_OverCrtFlt 0 "Normol" 1 "Fault" ;
VAL_ 884 PTC_HVUnderVoltFlt 0 "Normol" 1 "Fault" ;
VAL_ 884 PTC_HVOverVoltFlt 0 "Normol" 1 "Fault" ;
VAL_ 884 PTC_ChkBattOverVoltFlt 0 "Normol" 1 "Fault" ;
VAL_ 884 PTC_ChkBattUnderVoltFlt 0 "Normol" 1 "Fault" ;
VAL_ 884 PTC_InlTSnsrFlt 0 "Normol" 1 "Fault" ;
VAL_ 884 PTC_OutlTSnsrFlt 0 "Normol" 1 "Fault" ;
VAL_ 884 PTC_InlOverTFlt 0 "Normol" 1 "Fault" ;
VAL_ 884 PTC_OutlOverTFlt 0 "Normol" 1 "Fault" ;
VAL_ 884 PTC_PCBOverTFlt 0 "Normol" 1 "Fault" ;
VAL_ 884 PTC_PCBTSnsrFlt 0 "Normol" 1 "Fault" ;
VAL_ 884 PTC_PwrOutpFlt 0 "Normol" 1 "Fault" ;
VAL_ 885 BMS_PreChgRelay_ERR 0 "error" 1 "normal" ;
VAL_ 885 BMS_TotalNegRelay_ERR 0 "Error" 1 "normal" ;
VAL_ 885 BMS_MainPosRelay_ERR 0 "Error" 1 "normal" ;
VAL_ 885 BMS_MainPosRelay_STS 0 "reserved" 1 "open" 2 "closed" 3 "stuck closed" 4 "stuck open" ;
VAL_ 885 BMS_PreChgRelay_STS 0 "reserved" 1 "open" 2 "closed" 3 "stuck closed" 4 "stuck open" ;
VAL_ 885 BMS_TotalNegRelay_STS 0 "reserved" 1 "open" 2 "closed" 3 "stuck closed" 4 "stuck open" ;
VAL_ 888 CVC_Vehicle_Operation_State 0 "OFF" 1 "ACC" 2 "ON (Drive Present)" 3 "START (eMotor running)" 4 "OTA" 5 "Invaild" ;
VAL_ 888 CVC_CL15c_req 0 "OFF" 1 "ON" 2 "Reserved" 3 "Invaild" ;
VAL_ 888 CVC_Acc_Mode_Req 0 "No request" 1 "ACC state request" 2 "Reserved" 3 "Invaild" ;
VAL_ 888 Warning_Clamp_Incompatible 0 "No Alert" 1 "Alert" ;
VAL_ 888 CVC_ON_Mode_Req 0 "No request" 1 "ON state request" 2 "Reserved" 3 "Signal Invaild" ;
VAL_ 888 CVC_Vehicle_Special_Mode 0 "None" 1 "Camp mode" 2 "Pet mode" 3 "Showroom mode" 4 "Tow mode" 5 "Reserved" 6 "Reserved" 7 "Signal invalid" ;
VAL_ 889 PTC_IninSts 0 "Not finished" 1 "Finished" ;
VAL_ 889 PTC_HVPwrSplySts 0 "HV OFF" 1 "HV On" ;
VAL_ 889 PTC_ActGear 0 "Gear 0" 1 "Gear 1" 2 "Gear 2" 3 "Gear 3" 4 "Gear 4" 5 "Gear 5" 6 "Gear 6" ;
VAL_ 889 PTC_Mod 0 "Gear mode" 1 "Power mode" ;
VAL_ 892 EVCC_ChgGun_Sts 0 "Gun not plugged-in" 1 "Gun plugged-in, locked" 2 "Gun plugged-in, released" 3 "Error, cannot lock" 4 "Error, cannot release" 5 "Bad connection" 6 "Reversed" 7 "Invalid" ;
VAL_ 892 EVCC_ChgFlap_Sts 0 "Closed, locked" 1 "Closed, released" 2 "Opened" 3 "Invalid" ;
VAL_ 892 EVCC_ChgType 0 "No charging" 1 "Normal AC charging" 2 "PLC AC charging" 3 "DC charging" 4 "Reserved" 5 "Reserved" 6 "Reserved" 7 "Invalid" ;
VAL_ 892 EVCC_VehChg_Sts 0 "Not charging" 1 "Charging in-progress" 2 "Waiting to start charging" 3 "Charging complete" 4 "Charge fault" 5 "Reserved" 6 "Reserved" 7 "Invalid" ;
VAL_ 892 EVCC_ChgAuthen_Sts 0 "Not authenticating" 1 "Authenticating" 2 "Authentication success" 3 "Authentication failed" 4 "Forbidden vehicle" 5 "Reserved" 6 "Reserved" 7 "Invalid" ;
VAL_ 892 EVCC_PaymentType 0 "Init" 1 "EIM" 2 "PnC" 3 "Reserved" 4 "Reserved" 5 "Reserved" 6 "Reserved" 7 "Invalid" ;
VAL_ 892 EVCC_VehChgCompError_Sts 0 "No error" 1 "Error level 1" 2 "Error level 2" 3 "Error level 3" 4 "Error level 4" 5 "Reserved" 6 "Reserved" 7 "Reserved" ;
VAL_ 919 OBC_InletTempSenFault 0 "Normal" 1 "Error" ;
VAL_ 920 OBC_OutputUnderVoltage 0 "Normal" 1 "Error" ;
VAL_ 920 OBC_OutputOverVoltage 0 "Normal" 1 "Error" ;
VAL_ 920 OBC_InputUnderVoltage 0 "Normal" 1 "Error" ;
VAL_ 920 OBC_InputOverVoltage 0 "Normal" 1 "Error" ;
VAL_ 920 OBC_12VFault 0 "Normal" 1 "Error" ;
VAL_ 920 OBC_ChgConnectionFault 0 "Normal" 1 "Error" ;
VAL_ 920 OBC_ChgerTempCircuitFault 0 "Normal" 1 "Error" ;
VAL_ 920 OBC_InputOverCurrent 0 "Normal" 1 "Error" ;
VAL_ 920 OBC_ChgerDeratingOverTemp 0 "Normal" 1 "Error" ;
VAL_ 920 OBC_ChgerShtdownOverTemp 0 "Normal" 1 "Error" ;
VAL_ 920 OBC_CAN_CheckSumErrorBMS 0 "Normal" 1 "Error" ;
VAL_ 920 OBC_CAN_LostBMSFrame 0 "Normal" 1 "Error" ;
VAL_ 920 OBC_CAN_MissBMS 0 "Normal" 1 "Error" ;
VAL_ 920 OBC_CAN_InternalComFault 0 "Normal" 1 "Error" ;
VAL_ 920 OBC_CAN_MissCVC 0 "Normal" 1 "Error" ;
VAL_ 920 OBC_CAN_BusOff 0 "Normal" 1 "Error" ;
VAL_ 1009 IPC_IPCTotalOdometerV 0 "valid" 1 "invalid" ;
VAL_ 1110 BMS_CellLowVol_ERR 0 "Normal" 1 "Warning" 2 "Error" 3 "Safety Error" ;
VAL_ 1110 BMS_HVIL_Err 0 "Normal" 1 "Level1" 2 "Level2" 3 "Level3" ;
VAL_ 1110 BMS_PackInsu_ERR 0 "Lv0-No Err" 1 "Lv1 - Short to ground" 2 "Lv2-Short to vbat and open line" ;
VAL_ 1110 BMS_CellVoltDiff_ERR 0 "Normal" 1 "Warning" 2 "Error" 3 "Safety Error" ;
VAL_ 1110 BMS_ProbeTempDiff_ERR 0 "Normal" 1 "Warning" 2 "Error" 3 "Safety Error" ;
VAL_ 1110 BMS_PackHighVol_ERR 0 "Normal" 1 "Warning" 2 "Error" 3 "Safety Error" ;
VAL_ 1110 BMS_PackLowVol_ERR 0 "Normal" 1 "Warning" 2 "Error" 3 "Safety Error" ;
VAL_ 1110 BMS_CellHighVol_ERR 0 "Normal" 1 "Warning" 2 "Error" 3 "Safety Error" ;
VAL_ 1110 BMS_ProbeHighTemp_ERR 0 "Normal" 1 "Warning" 2 "Error" 3 "Safety Error" ;
VAL_ 1110 BMS_FuseStatus_ERR 0 "Normal" 1 "Fuse blow" ;
VAL_ 1110 BMS_PackOverCurr_ERR 0 "Normal" 1 "Warning" 2 "Error" 3 "Safety Error" ;
VAL_ 1110 BMS_ProbeLowTemp_ERR 0 "Normal" 1 "Warning" 2 "Error" 3 "Safety Error" ;
VAL_ 1118 EAC_CompBoardTempV 0 "Valid" 1 "Invalid" ;
VAL_ 1118 EAC_CompHVInputV 0 "Valid" 1 "Invalid" ;
VAL_ 1118 EAC_CompIGBTTempV 0 "Valid" 1 "Invalid" ;
VAL_ 1119 CompSpdReqV 0 "Valid" 1 "Invalid" ;
VAL_ 1119 CompEnable 0 "compressor Off" 1 "compressor ON" ;
VAL_ 1120 EAC_CompFltStat 0 "No Fault" 1 "Under Voltage" 2 "Over Voltage" 3 "Over Temperature" 4 "Current Fault" 5 "Internal Fault" ;
VAL_ 1120 EAC_CompStat 0 "Normal Operation" 1 "Degraded Operation" 2 "Inoperative" ;
VAL_ 1120 EAC_CompSpdV 0 "Valid" 1 "Invalid" ;
VAL_ 1120 EAC_CompElecPwrV 0 "Valid" 1 "Invalid" ;
VAL_ 1120 EAC_CompElecCurrV 0 "Valid" 1 "Invalid" ;
VAL_ 1120 EAC_ErrorCode 0 "Normal" ;
VAL_ 1171 BMS_PackTempSts 0 "No warning" 1 "Over Temperature Warning" 2 "Under Temperature Warning" ;
VAL_ 1171 BMS_ThermalRunaway 0 "No Warning" 1 "Warning" ;
VAL_ 1171 BMS_BatteryReplacement 0 "No Warning" 1 "Warning" ;
VAL_ 1171 BMS_Warning_PowerDegrade 0 "Normal" 1 "Pack Power Degrade" ;
VAL_ 1171 BMS_Warning_DeltaSoC 0 "Normal" 1 "Delta SOC high" ;
VAL_ 1171 BMS_Warning_HVILSts 0 "Normal" 1 "HVIL error detected" ;
VAL_ 1171 BMS_Warning_Isolation 0 "Normal" 1 "Isolation reached level 3" ;
VAL_ 1171 BMS_Warning_CoolantLeakage 0 "Normal" 1 "Coolant leakage detected" ;
VAL_ 1171 BMS_MalfunctionSts 0 "No Warning" 1 "Warning" ;
VAL_ 1171 BMS_LowBattery 0 "No warning" 1 "Low level" 2 "Extremely low level" ;
VAL_ 1171 BMS_Warning_DeltaTemperature 0 "Normal" 1 "Level 1 warning" 2 "Level 2 extreme" ;
VAL_ 1171 BMS_Warning_BDUTemperatureSts 0 "Normal" 1 "BDU temp warning" 2 "BDU hot" 3 "BDU extreme hot" ;
VAL_ 1171 BMS_Warning_Contactor_Aging 0 "No Warning" 1 "Warning" ;
